VERSION ""

NS_ :

BS_:

BU_: Sound_A Ladegeraet_PAG_PF Motor_EDC17_Pirol PSM_Ant_Derivate GW_Routing_Derivate GW_Applikation_Derivate BMS_Hybrid Getriebe_Derivate LEH_Hybrid Motor_MED17_Hybrid Sound_I Tool Airbag Waehlhebel

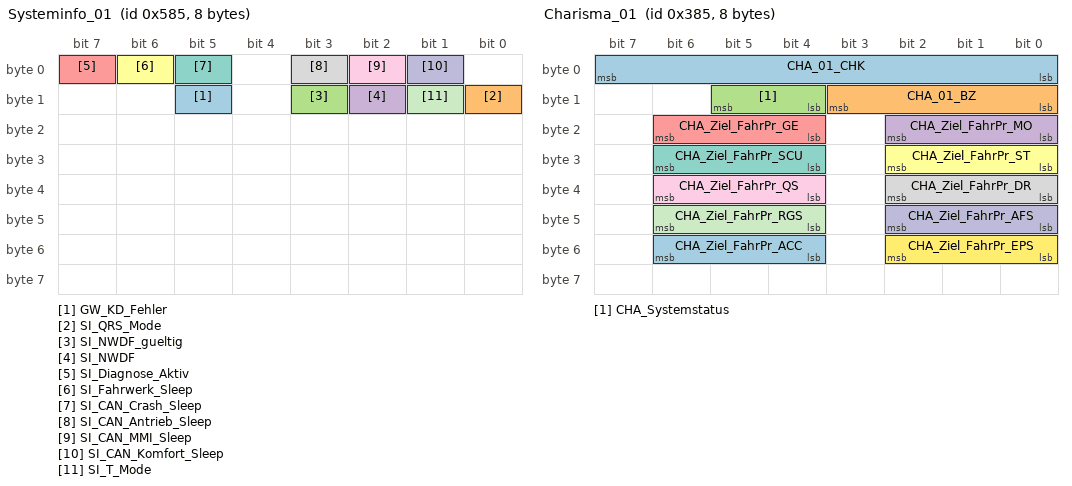
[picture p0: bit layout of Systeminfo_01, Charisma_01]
BO_ 1413 Systeminfo_01: 8 GW_Applikation_Derivate
 SG_ GW_KD_Fehler : 13|1@1+ (1,0) [0|1] "" Vector__XXX
 SG_ SI_QRS_Mode : 8|1@1+ (1,0) [0|1] ""  Motor_MED17_Hybrid,Motor_EDC17_Pirol
 SG_ SI_NWDF_gueltig : 11|1@1+ (1,0) [0|1] "" Vector__XXX
 SG_ SI_NWDF : 10|1@1+ (1,0) [0|1] "" Vector__XXX
 SG_ SI_Diagnose_Aktiv : 7|1@1+ (1,0) [0|1] "" Vector__XXX
 SG_ SI_Fahrwerk_Sleep : 6|1@1+ (1,0) [0|1] "" Vector__XXX
 SG_ SI_CAN_Crash_Sleep : 5|1@1+ (1,0) [0|1] "" Vector__XXX
 SG_ SI_CAN_Antrieb_Sleep : 3|1@1+ (1,0) [0|1] "" Vector__XXX
 SG_ SI_CAN_MMI_Sleep : 2|1@1+ (1,0) [0|1] "" Vector__XXX
 SG_ SI_CAN_Komfort_Sleep : 1|1@1+ (1,0) [0|1] "" Vector__XXX
 SG_ SI_T_Mode : 9|1@1+ (1,0) [0|1] ""  Motor_EDC17_Pirol,Motor_MED17_Hybrid,Airbag

BO_ 2616986624 CCP_MO_CRO_02: 8 Tool
 SG_ CCP_MO_CRO_02_Data : 0|64@1+ (1,0) [0|1] ""  Motor_MED17_Hybrid,Motor_EDC17_Pirol

BO_ 480 CCP_MO_CRO_01: 8 Tool
 SG_ CCP_MO_CRO_01_Data : 0|64@1+ (1,0) [0|1] ""  Motor_MED17_Hybrid,Motor_EDC17_Pirol

BO_ 901 Charisma_01: 8 GW_Routing_Derivate
 SG_ CHA_01_CHK : 0|8@1+ (1,0) [0|255] ""  Motor_EDC17_Pirol,Motor_MED17_Hybrid
 SG_ CHA_01_BZ : 8|4@1+ (1,0) [0|15] ""  Motor_EDC17_Pirol,Motor_MED17_Hybrid
 SG_ CHA_Systemstatus : 12|2@1+ (1,0) [0|3] ""  Motor_EDC17_Pirol,Motor_MED17_Hybrid
 SG_ CHA_Ziel_FahrPr_MO : 16|3@1+ (1,0) [0|7] ""  Motor_EDC17_Pirol,Motor_MED17_Hybrid
 SG_ CHA_Ziel_FahrPr_GE : 20|3@1+ (1,0) [0|7] ""  Getriebe_Derivate
 SG_ CHA_Ziel_FahrPr_ST : 24|3@1+ (1,0) [0|7] "" Vector__XXX
 SG_ CHA_Ziel_FahrPr_SCU : 28|3@1+ (1,0) [0|7] "" Vector__XXX
 SG_ CHA_Ziel_FahrPr_DR : 32|3@1+ (1,0) [0|7] "" Vector__XXX
 SG_ CHA_Ziel_FahrPr_QS : 36|3@1+ (1,0) [0|7] "" Vector__XXX
 SG_ CHA_Ziel_FahrPr_AFS : 40|3@1+ (1,0) [0|7] "" Vector__XXX
 SG_ CHA_Ziel_FahrPr_RGS : 44|3@1+ (1,0) [0|7] "" Vector__XXX
 SG_ CHA_Ziel_FahrPr_EPS : 48|3@1+ (1,0) [0|7] "" Vector__XXX
 SG_ CHA_Ziel_FahrPr_ACC : 52|3@1+ (1,0) [0|7] "" Vector__XXX

BO_ 1728 NMH_Gateway: 7 GW_Applikation_Derivate
 SG_ NMH_GW_Start_1 : 0|1@1+ (1,0) [0|1] ""  Ladegeraet_PAG_PF,Getriebe_Derivate,Motor_MED17_Hybrid,Motor_EDC17_Pirol,LEH_Hybrid,BMS_Hybrid
 SG_ NMH_GW_Start_2 : 1|1@1+ (1,0) [0|1] "" Vector__XXX
 SG_ NMH_GW_Normal_Mode_1 : 2|1@1+ (1,0) [0|1] "" Vector__XXX
 SG_ NMH_GW_Normal_Mode_2 : 3|1@1+ (1,0) [0|1] "" Vector__XXX
 SG_ NMH_GW_Car_WakeUp : 6|1@1+ (1,0) [0|1] "" Vector__XXX
 SG_ NMH_GW_Per_WakeUp : 8|5@1+ (1,0) [0|31] "" Vector__XXX
 SG_ NMH_GW_Fkt_WakeUp : 13|3@1+ (1,0) [0|7] "" Vector__XXX
 SG_ NMH_GW_NM_aktiv_Klemme_15 : 16|1@1+ (1,0) [0|1] "" Vector__XXX
 SG_ NMH_GW_NM_aktiv_Diagnose : 17|1@1+ (1,0) [0|1] "" Vector__XXX
 SG_ NMH_GW_NM_aktiv_Start : 18|1@1+ (1,0) [0|1] "" Vector__XXX
 SG_ NMH_GW_NM_aktiv_BDM : 19|1@1+ (1,0) [0|1] "" Vector__XXX
 SG_ NMH_GW_NM_aktiv_Warnblinken : 20|1@1+ (1,0) [0|1] "" Vector__XXX
 SG_ NMH_GW_NM_aktiv_ESP : 21|1@1+ (1,0) [0|1] "" Vector__XXX
 SG_ NMH_GW_NM_aktiv_EMP : 22|1@1+ (1,0) [0|1] "" Vector__XXX
 SG_ NMH_GW_Abschaltstufe_3 : 24|1@1+ (1,0) [0|1] "" Vector__XXX
 SG_ NMH_GW_SG_Fehlerdauer : 25|1@1+ (1,0) [0|1] "" Vector__XXX
 SG_ NMH_GW_STH_Wakeup : 26|1@1+ (1,0) [0|1] "" Vector__XXX
 SG_ NMH_GW_NL_Diagnose : 27|1@1+ (1,0) [0|1] "" Vector__XXX
 SG_ NM_GW_Signalfehler : 32|1@1+ (1,0) [0|1] "" Vector__XXX
 SG_ NMH_GW_TimeOut_Fehler : 33|1@1+ (1,0) [0|1] "" Vector__XXX
 SG_ NMH_GW_CAN_Diag_deaktiv : 34|1@1+ (1,0) [0|1] "" Vector__XXX
 SG_ NMH_GW_KompSchutz : 35|1@1+ (1,0) [0|1] "" Vector__XXX
 SG_ NMH_GW_Mute_Mode : 36|1@1+ (1,0) [0|1] "" Vector__XXX
 SG_ NMH_GW_Transport_Mode : 37|1@1+ (1,0) [0|1] "" Vector__XXX
 SG_ NMH_GW_Abschaltstufe_aktiv : 38|1@1+ (1,0) [0|1] "" Vector__XXX
 SG_ NMH_GW_Eindraht_Fehler : 39|1@1+ (1,0) [0|1] "" Vector__XXX
 SG_ NMH_GW_ACAN : 40|1@1+ (1,0) [0|1] "" Vector__XXX
 SG_ NMH_GW_KombiCAN : 41|1@1+ (1,0) [0|1] "" Vector__XXX
 SG_ NMH_GW_KomfortCAN : 42|1@1+ (1,0) [0|1] "" Vector__XXX
 SG_ NMH_GW_Infotainment : 43|1@1+ (1,0) [0|1] "" Vector__XXX
 SG_ NMH_GW_Fahrwerk : 44|1@1+ (1,0) [0|1] "" Vector__XXX
 SG_ NMH_GW_WakeUp_CAN_Bus : 45|3@1+ (1,0) [0|7] "" Vector__XXX

BO_ 1327 ESP_27: 8 PSM_Ant_Derivate
 SG_ OBD_Fehler_Laengsbeschleunigung : 14|4@1+ (1,0) [0|15] ""  Motor_MED17_Hybrid
 SG_ OBD_Fehler_Vordrucksensor : 12|2@1+ (1,0) [0|3] ""  Motor_MED17_Hybrid

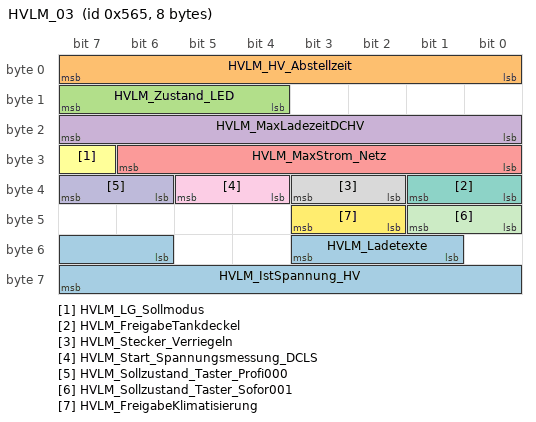
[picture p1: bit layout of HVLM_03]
BO_ 1381 HVLM_03: 8 Ladegeraet_PAG_PF
 SG_ HVLM_IstSpannung_HV : 54|10@1+ (1,0) [0|1021] "Unit_Volt"  GW_Applikation_Derivate,GW_Routing_Derivate
 SG_ HVLM_HV_Abstellzeit : 0|8@1+ (4,0) [0|1012] "Unit_Minut"  GW_Routing_Derivate
 SG_ HVLM_Zustand_LED : 12|4@1+ (1,0) [0|15] ""  GW_Routing_Derivate
 SG_ HVLM_MaxLadezeitDCHV : 16|8@1+ (10,0) [0|2530] "Unit_Minut"  GW_Routing_Derivate
 SG_ HVLM_MaxStrom_Netz : 24|7@1+ (0.5,0) [0|62.5] "Unit_Amper"  GW_Routing_Derivate
 SG_ HVLM_LG_Sollmodus : 31|1@1+ (1,0) [0|1] ""  GW_Routing_Derivate
 SG_ HVLM_FreigabeTankdeckel : 32|2@1+ (1,0) [0|3] ""  GW_Routing_Derivate
 SG_ HVLM_Stecker_Verriegeln : 34|2@1+ (1,0) [0|3] ""  GW_Routing_Derivate
 SG_ HVLM_Start_Spannungsmessung_DCLS : 36|2@1+ (1,0) [0|3] ""  GW_Routing_Derivate
 SG_ HVLM_Sollzustand_Taster_Profi000 : 38|2@1+ (1,0) [0|3] ""  GW_Routing_Derivate
 SG_ HVLM_Sollzustand_Taster_Sofor001 : 40|2@1+ (1,0) [0|3] ""  GW_Routing_Derivate
 SG_ HVLM_FreigabeKlimatisierung : 42|2@1+ (1,0) [0|3] ""  GW_Routing_Derivate
 SG_ HVLM_Ladetexte : 49|3@1+ (1,0) [0|7] ""  GW_Routing_Derivate

BO_ 1534 Kombi_18_PAG: 8 GW_Routing_Derivate
 SG_ KBI_Set_Timer_MUX M : 0|3@1+ (1,0) [0|7] ""  Ladegeraet_PAG_PF
 SG_ KBI_Set_Timer_1_Jahr m1 : 3|7@1+ (1,2000) [2000|2125] "Unit_Year"  Ladegeraet_PAG_PF
 SG_ KBI_Set_Timer_2_Jahr m2 : 3|7@1+ (1,2000) [2000|2125] "Unit_Year"  Ladegeraet_PAG_PF
 SG_ KBI_Set_Timer_3_Jahr m3 : 3|7@1+ (1,2000) [2000|2125] "Unit_Year"  Ladegeraet_PAG_PF
 SG_ KBI_Set_Timer_4_Jahr m4 : 3|7@1+ (1,2000) [2000|2125] "Unit_Year"  Ladegeraet_PAG_PF
 SG_ KBI_Set_Timer_1_Minute m1 : 10|6@1+ (1,0) [0|59] "Unit_Minut"  Ladegeraet_PAG_PF
 SG_ KBI_Set_Timer_2_Minute m2 : 10|6@1+ (1,0) [0|59] "Unit_Minut"  Ladegeraet_PAG_PF
 SG_ KBI_Set_Timer_3_Minute m3 : 10|6@1+ (1,0) [0|59] "Unit_Minut"  Ladegeraet_PAG_PF
 SG_ KBI_Set_Timer_4_Minute m4 : 10|6@1+ (1,0) [0|59] "Unit_Minut"  Ladegeraet_PAG_PF
 SG_ KBI_Set_Timer_1_Monat m1 : 16|4@1+ (1,0) [1|12] "Unit_Month"  Ladegeraet_PAG_PF
 SG_ KBI_Set_Timer_2_Monat m2 : 16|4@1+ (1,0) [1|12] "Unit_Month"  Ladegeraet_PAG_PF
 SG_ KBI_Set_Timer_3_Monat m3 : 16|4@1+ (1,0) [1|12] "Unit_Month"  Ladegeraet_PAG_PF
 SG_ KBI_Set_Timer_4_Monat m4 : 16|4@1+ (1,0) [1|12] "Unit_Month"  Ladegeraet_PAG_PF
 SG_ KBI_Set_Timer_1_Stunde m1 : 20|5@1+ (1,0) [0|23] "Unit_Hours"  Ladegeraet_PAG_PF
 SG_ KBI_Set_Timer_2_Stunde m2 : 20|5@1+ (1,0) [0|23] "Unit_Hours"  Ladegeraet_PAG_PF
 SG_ KBI_Set_Timer_3_Stunde m3 : 20|5@1+ (1,0) [0|23] "Unit_Hours"  Ladegeraet_PAG_PF
 SG_ KBI_Set_Timer_4_Stunde m4 : 20|5@1+ (1,0) [0|23] "Unit_Hours"  Ladegeraet_PAG_PF
 SG_ KBI_Set_Timer_1_Tag m1 : 25|5@1+ (1,0) [1|31] "Unit_Day"  Ladegeraet_PAG_PF
 SG_ KBI_Set_Timer_2_Tag m2 : 25|5@1+ (1,0) [1|31] "Unit_Day"  Ladegeraet_PAG_PF
 SG_ KBI_Set_Timer_3_Tag m3 : 25|5@1+ (1,0) [1|31] "Unit_Day"  Ladegeraet_PAG_PF
 SG_ KBI_Set_Timer_4_Tag m4 : 25|5@1+ (1,0) [1|31] "Unit_Day"  Ladegeraet_PAG_PF
 SG_ KBI_Set_Timer_1_Laden m1 : 30|1@1+ (1,0) [0|1] ""  Ladegeraet_PAG_PF
 SG_ KBI_Set_Timer_2_Laden m2 : 30|1@1+ (1,0) [0|1] ""  Ladegeraet_PAG_PF
 SG_ KBI_Set_Timer_3_Laden m3 : 30|1@1+ (1,0) [0|1] ""  Ladegeraet_PAG_PF
 SG_ KBI_Set_Timer_4_Laden m4 : 30|1@1+ (1,0) [0|1] ""  Ladegeraet_PAG_PF
 SG_ KBI_Set_Timer_1_Vorklima m1 : 31|1@1+ (1,0) [0|1] ""  Ladegeraet_PAG_PF
 SG_ KBI_Set_Timer_2_Vorklima m2 : 31|1@1+ (1,0) [0|1] ""  Ladegeraet_PAG_PF
 SG_ KBI_Set_Timer_3_Vorklima m3 : 31|1@1+ (1,0) [0|1] ""  Ladegeraet_PAG_PF
 SG_ KBI_Set_Timer_4_Vorklima m4 : 31|1@1+ (1,0) [0|1] ""  Ladegeraet_PAG_PF
 SG_ KBI_Set_Timer_1_Zyklus_Mo m1 : 32|1@1+ (1,0) [0|1] ""  Ladegeraet_PAG_PF
 SG_ KBI_Set_Timer_2_Zyklus_Mo m2 : 32|1@1+ (1,0) [0|1] ""  Ladegeraet_PAG_PF
 SG_ KBI_Set_Timer_3_Zyklus_Mo m3 : 32|1@1+ (1,0) [0|1] ""  Ladegeraet_PAG_PF
 SG_ KBI_Set_Timer_4_Zyklus_Mo m4 : 32|1@1+ (1,0) [0|1] ""  Ladegeraet_PAG_PF
 SG_ KBI_Set_Timer_1_Zyklus_Di m1 : 33|1@1+ (1,0) [0|1] ""  Ladegeraet_PAG_PF
 SG_ KBI_Set_Timer_2_Zyklus_Di m2 : 33|1@1+ (1,0) [0|1] ""  Ladegeraet_PAG_PF
 SG_ KBI_Set_Timer_3_Zyklus_Di m3 : 33|1@1+ (1,0) [0|1] ""  Ladegeraet_PAG_PF
 SG_ KBI_Set_Timer_4_Zyklus_Di m4 : 33|1@1+ (1,0) [0|1] ""  Ladegeraet_PAG_PF
 SG_ KBI_Set_Timer_1_Zyklus_Mi m1 : 34|1@1+ (1,0) [0|1] ""  Ladegeraet_PAG_PF
 SG_ KBI_Set_Timer_2_Zyklus_Mi m2 : 34|1@1+ (1,0) [0|1] ""  Ladegeraet_PAG_PF
 SG_ KBI_Set_Timer_3_Zyklus_Mi m3 : 34|1@1+ (1,0) [0|1] ""  Ladegeraet_PAG_PF
 SG_ KBI_Set_Timer_4_Zyklus_Mi m4 : 34|1@1+ (1,0) [0|1] ""  Ladegeraet_PAG_PF
 SG_ KBI_Set_Timer_1_Zyklus_Do m1 : 35|1@1+ (1,0) [0|1] ""  Ladegeraet_PAG_PF
 SG_ KBI_Set_Timer_2_Zyklus_Do m2 : 35|1@1+ (1,0) [0|1] ""  Ladegeraet_PAG_PF
 SG_ KBI_Set_Timer_3_Zyklus_Do m3 : 35|1@1+ (1,0) [0|1] ""  Ladegeraet_PAG_PF
 SG_ KBI_Set_Timer_4_Zyklus_Do m4 : 35|1@1+ (1,0) [0|1] ""  Ladegeraet_PAG_PF
 SG_ KBI_Set_Timer_1_Zyklus_Fr m1 : 36|1@1+ (1,0) [0|1] ""  Ladegeraet_PAG_PF
 SG_ KBI_Set_Timer_2_Zyklus_Fr m2 : 36|1@1+ (1,0) [0|1] ""  Ladegeraet_PAG_PF
 SG_ KBI_Set_Timer_3_Zyklus_Fr m3 : 36|1@1+ (1,0) [0|1] ""  Ladegeraet_PAG_PF
 SG_ KBI_Set_Timer_4_Zyklus_Fr m4 : 36|1@1+ (1,0) [0|1] ""  Ladegeraet_PAG_PF
 SG_ KBI_Set_Timer_1_Zyklus_Sa m1 : 37|1@1+ (1,0) [0|1] ""  Ladegeraet_PAG_PF
 SG_ KBI_Set_Timer_2_Zyklus_Sa m2 : 37|1@1+ (1,0) [0|1] ""  Ladegeraet_PAG_PF
 SG_ KBI_Set_Timer_3_Zyklus_Sa m3 : 37|1@1+ (1,0) [0|1] ""  Ladegeraet_PAG_PF
 SG_ KBI_Set_Timer_4_Zyklus_Sa m4 : 37|1@1+ (1,0) [0|1] ""  Ladegeraet_PAG_PF
 SG_ KBI_Set_Timer_1_Zyklus_So m1 : 38|1@1+ (1,0) [0|1] ""  Ladegeraet_PAG_PF
 SG_ KBI_Set_Timer_2_Zyklus_So m2 : 38|1@1+ (1,0) [0|1] ""  Ladegeraet_PAG_PF
 SG_ KBI_Set_Timer_3_Zyklus_So m3 : 38|1@1+ (1,0) [0|1] ""  Ladegeraet_PAG_PF
 SG_ KBI_Set_Timer_4_Zyklus_So m4 : 38|1@1+ (1,0) [0|1] ""  Ladegeraet_PAG_PF
 SG_ KBI_Set_Timer_1_Zyklus_WH m1 : 39|1@1+ (1,0) [0|1] ""  Ladegeraet_PAG_PF
 SG_ KBI_Set_Timer_2_Zyklus_WH m2 : 39|1@1+ (1,0) [0|1] ""  Ladegeraet_PAG_PF
 SG_ KBI_Set_Timer_3_Zyklus_WH m3 : 39|1@1+ (1,0) [0|1] ""  Ladegeraet_PAG_PF
 SG_ KBI_Set_Timer_4_Zyklus_WH m4 : 39|1@1+ (1,0) [0|1] ""  Ladegeraet_PAG_PF
 SG_ KBI_MOD_Privatsphaere : 60|2@1+ (1,0) [0|3] "" Vector__XXX
 SG_ KBI_STH_Status : 62|2@1+ (1,0) [0|3] "" Vector__XXX

BO_ 1631 Motor_16: 8 Motor_MED17_Hybrid
 SG_ MO_Energieinhalt_BMS : 36|12@1+ (25,0) [0|102325] "Unit_Watt"  BMS_Hybrid

BO_ 1398 MOD_01_PAG: 8 GW_Routing_Derivate
 SG_ MOD_Set_Timer_5_Jahr m5 : 3|7@1+ (1,2000) [2000|2125] "Unit_Year" Vector__XXX
 SG_ MOD_Set_Timer_6_Jahr m6 : 3|7@1+ (1,2000) [2000|2125] "Unit_Year" Vector__XXX
 SG_ MOD_Set_Timer_5_Minute m5 : 10|6@1+ (1,0) [0|59] "Unit_Minut" Vector__XXX
 SG_ MOD_Set_Timer_6_Minute m6 : 10|6@1+ (1,0) [0|59] "Unit_Minut" Vector__XXX
 SG_ MOD_Set_Timer_5_Monat m5 : 16|4@1+ (1,0) [1|12] "Unit_Month" Vector__XXX
 SG_ MOD_Set_Timer_6_Monat m6 : 16|4@1+ (1,0) [1|12] "Unit_Month" Vector__XXX
 SG_ MOD_Set_Timer_5_Stunde m5 : 20|5@1+ (1,0) [0|23] "Unit_Hours" Vector__XXX
 SG_ MOD_Set_Timer_6_Stunde m6 : 20|5@1+ (1,0) [0|23] "Unit_Hours" Vector__XXX
 SG_ MOD_Set_Timer_5_Tag m5 : 25|5@1+ (1,0) [1|31] "Unit_Day" Vector__XXX
 SG_ MOD_Set_Timer_6_Tag m6 : 25|5@1+ (1,0) [1|31] "Unit_Day" Vector__XXX
 SG_ MOD_Set_Timer_5_Vorklima m5 : 31|1@1+ (1,0) [0|1] "" Vector__XXX
 SG_ MOD_Set_Timer_6_Vorklima m6 : 31|1@1+ (1,0) [0|1] "" Vector__XXX
 SG_ MOD_Set_Timerladen : 57|1@1+ (1,0) [0|1] ""  Ladegeraet_PAG_PF
 SG_ MOD_Set_Sofortladen : 59|1@1+ (1,0) [0|1] ""  Ladegeraet_PAG_PF
 SG_ MOD_Set_Timer_4_Jahr m4 : 3|7@1+ (1,2000) [2000|2125] "Unit_Year"  Ladegeraet_PAG_PF
 SG_ MOD_Set_Timer_4_Minute m4 : 10|6@1+ (1,0) [0|59] "Unit_Minut"  Ladegeraet_PAG_PF
 SG_ MOD_Set_Timer_4_Monat m4 : 16|4@1+ (1,0) [1|12] "Unit_Month"  Ladegeraet_PAG_PF
 SG_ MOD_Set_Timer_4_Stunde m4 : 20|5@1+ (1,0) [0|23] "Unit_Hours"  Ladegeraet_PAG_PF
 SG_ MOD_Set_Timer_4_Tag m4 : 25|5@1+ (1,0) [1|31] "Unit_Day"  Ladegeraet_PAG_PF
 SG_ MOD_Set_Timer_4_Laden m4 : 30|1@1+ (1,0) [0|1] ""  Ladegeraet_PAG_PF
 SG_ MOD_Set_Timer_4_Vorklima m4 : 31|1@1+ (1,0) [0|1] ""  Ladegeraet_PAG_PF
 SG_ MOD_Set_Timer_4_Zyklus_Mo m4 : 32|1@1+ (1,0) [0|1] ""  Ladegeraet_PAG_PF
 SG_ MOD_Set_Timer_4_Zyklus_Di m4 : 33|1@1+ (1,0) [0|1] ""  Ladegeraet_PAG_PF
 SG_ MOD_Set_Timer_4_Zyklus_Mi m4 : 34|1@1+ (1,0) [0|1] ""  Ladegeraet_PAG_PF
 SG_ MOD_Set_Timer_4_Zyklus_Do m4 : 35|1@1+ (1,0) [0|1] ""  Ladegeraet_PAG_PF
 SG_ MOD_Set_Timer_4_Zyklus_Fr m4 : 36|1@1+ (1,0) [0|1] ""  Ladegeraet_PAG_PF
 SG_ MOD_Set_Timer_4_Zyklus_Sa m4 : 37|1@1+ (1,0) [0|1] ""  Ladegeraet_PAG_PF
 SG_ MOD_Set_Timer_4_Zyklus_So m4 : 38|1@1+ (1,0) [0|1] ""  Ladegeraet_PAG_PF
 SG_ MOD_Set_Timer_4_Zyklus_WH m4 : 39|1@1+ (1,0) [0|1] ""  Ladegeraet_PAG_PF
 SG_ MOD_Set_Timer_1_Jahr m1 : 3|7@1+ (1,2000) [2000|2125] "Unit_Year"  Ladegeraet_PAG_PF
 SG_ MOD_Set_Timer_2_Jahr m2 : 3|7@1+ (1,2000) [2000|2125] "Unit_Year"  Ladegeraet_PAG_PF
 SG_ MOD_Set_Timer_3_Jahr m3 : 3|7@1+ (1,2000) [2000|2125] "Unit_Year"  Ladegeraet_PAG_PF
 SG_ MOD_Set_Timer_1_Minute m1 : 10|6@1+ (1,0) [0|59] "Unit_Minut"  Ladegeraet_PAG_PF
 SG_ MOD_Set_Timer_2_Minute m2 : 10|6@1+ (1,0) [0|59] "Unit_Minut"  Ladegeraet_PAG_PF
 SG_ MOD_Set_Timer_3_Minute m3 : 10|6@1+ (1,0) [0|59] "Unit_Minut"  Ladegeraet_PAG_PF
 SG_ MOD_Set_Timer_1_Monat m1 : 16|4@1+ (1,0) [1|12] "Unit_Month"  Ladegeraet_PAG_PF
 SG_ MOD_Set_Timer_2_Monat m2 : 16|4@1+ (1,0) [1|12] "Unit_Month"  Ladegeraet_PAG_PF
 SG_ MOD_Set_Timer_3_Monat m3 : 16|4@1+ (1,0) [1|12] "Unit_Month"  Ladegeraet_PAG_PF
 SG_ MOD_Set_Timer_1_Stunde m1 : 20|5@1+ (1,0) [0|23] "Unit_Hours"  Ladegeraet_PAG_PF
 SG_ MOD_Set_Timer_2_Stunde m2 : 20|5@1+ (1,0) [0|23] "Unit_Hours"  Ladegeraet_PAG_PF
 SG_ MOD_Set_Timer_3_Stunde m3 : 20|5@1+ (1,0) [0|23] "Unit_Hours"  Ladegeraet_PAG_PF
 SG_ MOD_Set_Timer_1_Tag m1 : 25|5@1+ (1,0) [1|31] "Unit_Day"  Ladegeraet_PAG_PF
 SG_ MOD_Set_Timer_2_Tag m2 : 25|5@1+ (1,0) [1|31] "Unit_Day"  Ladegeraet_PAG_PF
 SG_ MOD_Set_Timer_3_Tag m3 : 25|5@1+ (1,0) [1|31] "Unit_Day"  Ladegeraet_PAG_PF
 SG_ MOD_Set_Timer_1_Laden m1 : 30|1@1+ (1,0) [0|1] ""  Ladegeraet_PAG_PF
 SG_ MOD_Set_Timer_2_Laden m2 : 30|1@1+ (1,0) [0|1] ""  Ladegeraet_PAG_PF
 SG_ MOD_Set_Timer_3_Laden m3 : 30|1@1+ (1,0) [0|1] ""  Ladegeraet_PAG_PF
 SG_ MOD_Set_Timer_1_Vorklima m1 : 31|1@1+ (1,0) [0|1] ""  Ladegeraet_PAG_PF
 SG_ MOD_Set_Timer_2_Vorklima m2 : 31|1@1+ (1,0) [0|1] ""  Ladegeraet_PAG_PF
 SG_ MOD_Set_Timer_3_Vorklima m3 : 31|1@1+ (1,0) [0|1] ""  Ladegeraet_PAG_PF
 SG_ MOD_Set_Timer_1_Zyklus_Mo m1 : 32|1@1+ (1,0) [0|1] ""  Ladegeraet_PAG_PF
 SG_ MOD_Set_Timer_2_Zyklus_Mo m2 : 32|1@1+ (1,0) [0|1] ""  Ladegeraet_PAG_PF
 SG_ MOD_Set_Timer_3_Zyklus_Mo m3 : 32|1@1+ (1,0) [0|1] ""  Ladegeraet_PAG_PF
 SG_ MOD_Set_Timer_1_Zyklus_Di m1 : 33|1@1+ (1,0) [0|1] ""  Ladegeraet_PAG_PF
 SG_ MOD_Set_Timer_2_Zyklus_Di m2 : 33|1@1+ (1,0) [0|1] ""  Ladegeraet_PAG_PF
 SG_ MOD_Set_Timer_3_Zyklus_Di m3 : 33|1@1+ (1,0) [0|1] ""  Ladegeraet_PAG_PF
 SG_ MOD_Set_Timer_1_Zyklus_Mi m1 : 34|1@1+ (1,0) [0|1] ""  Ladegeraet_PAG_PF
 SG_ MOD_Set_Timer_2_Zyklus_Mi m2 : 34|1@1+ (1,0) [0|1] ""  Ladegeraet_PAG_PF
 SG_ MOD_Set_Timer_3_Zyklus_Mi m3 : 34|1@1+ (1,0) [0|1] ""  Ladegeraet_PAG_PF
 SG_ MOD_Set_Timer_1_Zyklus_Do m1 : 35|1@1+ (1,0) [0|1] ""  Ladegeraet_PAG_PF
 SG_ MOD_Set_Timer_2_Zyklus_Do m2 : 35|1@1+ (1,0) [0|1] ""  Ladegeraet_PAG_PF
 SG_ MOD_Set_Timer_3_Zyklus_Do m3 : 35|1@1+ (1,0) [0|1] ""  Ladegeraet_PAG_PF
 SG_ MOD_Set_Timer_1_Zyklus_Fr m1 : 36|1@1+ (1,0) [0|1] ""  Ladegeraet_PAG_PF
 SG_ MOD_Set_Timer_2_Zyklus_Fr m2 : 36|1@1+ (1,0) [0|1] ""  Ladegeraet_PAG_PF
 SG_ MOD_Set_Timer_3_Zyklus_Fr m3 : 36|1@1+ (1,0) [0|1] ""  Ladegeraet_PAG_PF
 SG_ MOD_Set_Timer_1_Zyklus_Sa m1 : 37|1@1+ (1,0) [0|1] ""  Ladegeraet_PAG_PF
 SG_ MOD_Set_Timer_2_Zyklus_Sa m2 : 37|1@1+ (1,0) [0|1] ""  Ladegeraet_PAG_PF
 SG_ MOD_Set_Timer_3_Zyklus_Sa m3 : 37|1@1+ (1,0) [0|1] ""  Ladegeraet_PAG_PF
 SG_ MOD_Set_Timer_1_Zyklus_So m1 : 38|1@1+ (1,0) [0|1] ""  Ladegeraet_PAG_PF
 SG_ MOD_Set_Timer_2_Zyklus_So m2 : 38|1@1+ (1,0) [0|1] ""  Ladegeraet_PAG_PF
 SG_ MOD_Set_Timer_3_Zyklus_So m3 : 38|1@1+ (1,0) [0|1] ""  Ladegeraet_PAG_PF
 SG_ MOD_Set_Timer_1_Zyklus_WH m1 : 39|1@1+ (1,0) [0|1] ""  Ladegeraet_PAG_PF
 SG_ MOD_Set_Timer_2_Zyklus_WH m2 : 39|1@1+ (1,0) [0|1] ""  Ladegeraet_PAG_PF
 SG_ MOD_Set_Timer_MUX M : 0|3@1+ (1,0) [0|7] ""  Ladegeraet_PAG_PF
 SG_ MOD_Set_Timer_3_Zyklus_WH m3 : 39|1@1+ (1,0) [0|1] ""  Ladegeraet_PAG_PF
 SG_ MOD_Set_Nachtstrom_X_Std_Anf : 40|6@1+ (0.5,0) [0|23.5] "Unit_Hours"  Ladegeraet_PAG_PF
 SG_ MOD_Set_Nachtstrom_Prof : 46|2@1+ (1,0) [0|3] ""  Ladegeraet_PAG_PF
 SG_ MOD_Set_Nachtstrom_X_Std_End : 48|6@1+ (0.5,0) [0|23.5] "Unit_Hours"  Ladegeraet_PAG_PF
 SG_ MOD_Set_Nachtstrom_Akt_Prof : 54|2@1+ (1,0) [0|3] ""  Ladegeraet_PAG_PF
 SG_ MOD_Set_Abbruch_Klima : 56|1@1+ (1,0) [0|1] ""  Ladegeraet_PAG_PF
 SG_ MOD_Set_Sofortstart_Klima : 58|1@1+ (1,0) [0|1] ""  Ladegeraet_PAG_PF
 SG_ MOD_Anf_Spiegel_anklappen : 60|1@1+ (1,0) [0|1] "" Vector__XXX
 SG_ MOD_Anf_ZV : 61|2@1+ (1,0) [0|3] "" Vector__XXX

BO_ 1397 HVLM_07_PAG: 8 Ladegeraet_PAG_PF
 SG_ HVLM_Status_Timer_7_Laden m7 : 30|1@1+ (1,0) [0|1] ""  GW_Routing_Derivate
 SG_ HVLM_Ladetexte : 59|3@1+ (1,0) [0|7] ""  GW_Routing_Derivate
 SG_ HVLM_Status_Timer_4_Jahr m4 : 3|7@1+ (1,2000) [2000|2125] "Unit_Year"  GW_Routing_Derivate
 SG_ HVLM_Status_Timer_4_Minute m4 : 10|6@1+ (1,0) [0|59] "Unit_Minut"  GW_Routing_Derivate
 SG_ HVLM_Status_Timer_4_Monat m4 : 16|4@1+ (1,0) [1|12] "Unit_Month"  GW_Routing_Derivate
 SG_ HVLM_Status_Timer_4_Stunde m4 : 20|5@1+ (1,0) [0|23] "Unit_Hours"  GW_Routing_Derivate
 SG_ HVLM_Status_Timer_4_Tag m4 : 25|5@1+ (1,0) [1|31] "Unit_Day"  GW_Routing_Derivate
 SG_ HVLM_Status_Timer_4_Laden m4 : 30|1@1+ (1,0) [0|1] ""  GW_Routing_Derivate
 SG_ HVLM_Status_Timer_4_Vorklima m4 : 31|1@1+ (1,0) [0|1] ""  GW_Routing_Derivate
 SG_ HVLM_Status_Timer_4_Zyklus_Mo m4 : 32|1@1+ (1,0) [0|1] ""  GW_Routing_Derivate
 SG_ HVLM_Status_Timer_2_Vorklima m2 : 31|1@1+ (1,0) [0|1] ""  GW_Routing_Derivate
 SG_ HVLM_Status_Timer_3_Vorklima m3 : 31|1@1+ (1,0) [0|1] ""  GW_Routing_Derivate
 SG_ HVLM_Status_Timer_1_Zyklus_Mo m1 : 32|1@1+ (1,0) [0|1] ""  GW_Routing_Derivate
 SG_ HVLM_Status_Timer_2_Zyklus_Mo m2 : 32|1@1+ (1,0) [0|1] ""  GW_Routing_Derivate
 SG_ HVLM_Status_Timer_3_Zyklus_Mo m3 : 32|1@1+ (1,0) [0|1] ""  GW_Routing_Derivate
 SG_ HVLM_Status_Timer_1_Zyklus_Di m1 : 33|1@1+ (1,0) [0|1] ""  GW_Routing_Derivate
 SG_ HVLM_Status_Timer_2_Zyklus_Di m2 : 33|1@1+ (1,0) [0|1] ""  GW_Routing_Derivate
 SG_ HVLM_Status_Timer_3_Zyklus_Di m3 : 33|1@1+ (1,0) [0|1] ""  GW_Routing_Derivate
 SG_ HVLM_Status_Timer_1_Zyklus_Mi m1 : 34|1@1+ (1,0) [0|1] ""  GW_Routing_Derivate
 SG_ HVLM_Status_Timer_2_Zyklus_Mi m2 : 34|1@1+ (1,0) [0|1] ""  GW_Routing_Derivate
 SG_ HVLM_Status_Timer_3_Zyklus_Mi m3 : 34|1@1+ (1,0) [0|1] ""  GW_Routing_Derivate
 SG_ HVLM_Status_Timer_1_Zyklus_Do m1 : 35|1@1+ (1,0) [0|1] ""  GW_Routing_Derivate
 SG_ HVLM_Status_Timer_2_Zyklus_Do m2 : 35|1@1+ (1,0) [0|1] ""  GW_Routing_Derivate
 SG_ HVLM_Status_Timer_3_Zyklus_Do m3 : 35|1@1+ (1,0) [0|1] ""  GW_Routing_Derivate
 SG_ HVLM_Status_Timer_1_Zyklus_Fr m1 : 36|1@1+ (1,0) [0|1] ""  GW_Routing_Derivate
 SG_ HVLM_Status_Timer_2_Zyklus_Fr m2 : 36|1@1+ (1,0) [0|1] ""  GW_Routing_Derivate
 SG_ HVLM_Status_Timer_3_Zyklus_Fr m3 : 36|1@1+ (1,0) [0|1] ""  GW_Routing_Derivate
 SG_ HVLM_Status_Timer_1_Zyklus_Sa m1 : 37|1@1+ (1,0) [0|1] ""  GW_Routing_Derivate
 SG_ HVLM_Status_Timer_2_Zyklus_Sa m2 : 37|1@1+ (1,0) [0|1] ""  GW_Routing_Derivate
 SG_ HVLM_Status_Timer_3_Zyklus_Sa m3 : 37|1@1+ (1,0) [0|1] ""  GW_Routing_Derivate
 SG_ HVLM_Status_Timer_1_Zyklus_So m1 : 38|1@1+ (1,0) [0|1] ""  GW_Routing_Derivate
 SG_ HVLM_Status_Timer_2_Zyklus_So m2 : 38|1@1+ (1,0) [0|1] ""  GW_Routing_Derivate
 SG_ HVLM_Status_Timer_3_Zyklus_So m3 : 38|1@1+ (1,0) [0|1] ""  GW_Routing_Derivate
 SG_ HVLM_Status_Timer_1_Zyklus_WH m1 : 39|1@1+ (1,0) [0|1] ""  GW_Routing_Derivate
 SG_ HVLM_Status_Timer_2_Zyklus_WH m2 : 39|1@1+ (1,0) [0|1] ""  GW_Routing_Derivate
 SG_ HVLM_Status_Timer_MUX M : 0|3@1+ (1,0) [0|7] ""  GW_Routing_Derivate
 SG_ HVLM_Status_Timer_3_Zyklus_WH m3 : 39|1@1+ (1,0) [0|1] ""  GW_Routing_Derivate
 SG_ HVLM_Status_Nachtstrom_X_Std_Anf : 40|6@1+ (0.5,0) [0|23.5] "Unit_Hours"  GW_Routing_Derivate
 SG_ HVLM_Status_Nachtstrom_Prof : 46|2@1+ (1,0) [0|3] ""  GW_Routing_Derivate
 SG_ HVLM_Status_Nachtstrom_X_Std_End : 48|6@1+ (0.5,0) [0|23.5] "Unit_Hours"  GW_Routing_Derivate
 SG_ HVLM_Status_Nachtstrom_Akt_Prof : 54|2@1+ (1,0) [0|3] ""  GW_Routing_Derivate
 SG_ HVLM_Status_Laden : 56|3@1+ (1,0) [0|7] ""  GW_Routing_Derivate
 SG_ HVLM_Status_Timer_4_Zyklus_Di m4 : 33|1@1+ (1,0) [0|1] ""  GW_Routing_Derivate
 SG_ HVLM_Status_Timer_4_Zyklus_Mi m4 : 34|1@1+ (1,0) [0|1] ""  GW_Routing_Derivate
 SG_ HVLM_Status_Timer_4_Zyklus_Do m4 : 35|1@1+ (1,0) [0|1] ""  GW_Routing_Derivate
 SG_ HVLM_Status_Timer_4_Zyklus_Fr m4 : 36|1@1+ (1,0) [0|1] ""  GW_Routing_Derivate
 SG_ HVLM_Status_Timer_1_Jahr m1 : 3|7@1+ (1,2000) [2000|2125] "Unit_Year"  GW_Routing_Derivate
 SG_ HVLM_Status_Timer_2_Jahr m2 : 3|7@1+ (1,2000) [2000|2125] "Unit_Year"  GW_Routing_Derivate
 SG_ HVLM_Status_Timer_3_Jahr m3 : 3|7@1+ (1,2000) [2000|2125] "Unit_Year"  GW_Routing_Derivate
 SG_ HVLM_Status_Timer_7_Jahr m7 : 3|7@1+ (1,2000) [2000|2125] "Unit_Year"  GW_Routing_Derivate
 SG_ HVLM_Status_Timer_1_Minute m1 : 10|6@1+ (1,0) [0|59] "Unit_Minut"  GW_Routing_Derivate
 SG_ HVLM_Status_Timer_2_Minute m2 : 10|6@1+ (1,0) [0|59] "Unit_Minut"  GW_Routing_Derivate
 SG_ HVLM_Status_Timer_3_Minute m3 : 10|6@1+ (1,0) [0|59] "Unit_Minut"  GW_Routing_Derivate
 SG_ HVLM_Status_Timer_7_Minute m7 : 10|6@1+ (1,0) [0|59] "Unit_Minut"  GW_Routing_Derivate
 SG_ HVLM_Status_Timer_1_Monat m1 : 16|4@1+ (1,0) [1|12] "Unit_Month"  GW_Routing_Derivate
 SG_ HVLM_Status_Timer_2_Monat m2 : 16|4@1+ (1,0) [1|12] "Unit_Month"  GW_Routing_Derivate
 SG_ HVLM_Status_Timer_3_Monat m3 : 16|4@1+ (1,0) [1|12] "Unit_Month"  GW_Routing_Derivate
 SG_ HVLM_Status_Timer_7_Monat m7 : 16|4@1+ (1,0) [1|12] "Unit_Month"  GW_Routing_Derivate
 SG_ HVLM_Status_Timer_1_Stunde m1 : 20|5@1+ (1,0) [0|23] "Unit_Hours"  GW_Routing_Derivate
 SG_ HVLM_Status_Timer_2_Stunde m2 : 20|5@1+ (1,0) [0|23] "Unit_Hours"  GW_Routing_Derivate
 SG_ HVLM_Status_Timer_3_Stunde m3 : 20|5@1+ (1,0) [0|23] "Unit_Hours"  GW_Routing_Derivate
 SG_ HVLM_Status_Timer_7_Stunde m7 : 20|5@1+ (1,0) [0|23] "Unit_Hours"  GW_Routing_Derivate
 SG_ HVLM_Status_Timer_1_Tag m1 : 25|5@1+ (1,0) [1|31] "Unit_Day"  GW_Routing_Derivate
 SG_ HVLM_Status_Timer_2_Tag m2 : 25|5@1+ (1,0) [1|31] "Unit_Day"  GW_Routing_Derivate
 SG_ HVLM_Status_Timer_3_Tag m3 : 25|5@1+ (1,0) [1|31] "Unit_Day"  GW_Routing_Derivate
 SG_ HVLM_Status_Timer_7_Tag m7 : 25|5@1+ (1,0) [1|31] "Unit_Day"  GW_Routing_Derivate
 SG_ HVLM_Status_Timer_1_Laden m1 : 30|1@1+ (1,0) [0|1] ""  GW_Routing_Derivate
 SG_ HVLM_Status_Timer_2_Laden m2 : 30|1@1+ (1,0) [0|1] ""  GW_Routing_Derivate
 SG_ HVLM_Status_Timer_3_Laden m3 : 30|1@1+ (1,0) [0|1] ""  GW_Routing_Derivate
 SG_ HVLM_Status_Timer_1_Vorklima m1 : 31|1@1+ (1,0) [0|1] ""  GW_Routing_Derivate
 SG_ HVLM_Status_Timer_4_Zyklus_Sa m4 : 37|1@1+ (1,0) [0|1] ""  GW_Routing_Derivate
 SG_ HVLM_Status_Timer_4_Zyklus_So m4 : 38|1@1+ (1,0) [0|1] ""  GW_Routing_Derivate
 SG_ HVLM_Status_Timer_4_Zyklus_WH m4 : 39|1@1+ (1,0) [0|1] ""  GW_Routing_Derivate

BO_ 1446 OBC_Komponentenfehler: 8 Ladegeraet_PAG_PF
 SG_ OBC_KomponentenFehler_01 : 0|2@1+ (1,0) [0|3] ""  BMS_Hybrid
 SG_ OBC_KomponentenFehler_02 : 2|2@1+ (1,0) [0|3] ""  BMS_Hybrid
 SG_ OBC_KomponentenFehler_03 : 4|2@1+ (1,0) [0|3] ""  BMS_Hybrid
 SG_ OBC_KomponentenFehler_04 : 6|2@1+ (1,0) [0|3] ""  BMS_Hybrid
 SG_ OBC_KomponentenFehler_05 : 8|2@1+ (1,0) [0|3] ""  BMS_Hybrid
 SG_ OBC_KomponentenFehler_06 : 10|2@1+ (1,0) [0|3] ""  BMS_Hybrid
 SG_ OBC_KomponentenFehler_07 : 12|2@1+ (1,0) [0|3] ""  BMS_Hybrid
 SG_ OBC_KomponentenFehler_08 : 14|2@1+ (1,0) [0|3] ""  BMS_Hybrid
 SG_ OBC_KomponentenFehler_09 : 16|2@1+ (1,0) [0|3] ""  BMS_Hybrid
 SG_ OBC_KomponentenFehler_10 : 18|2@1+ (1,0) [0|3] ""  BMS_Hybrid
 SG_ OBC_KomponentenFehler_11 : 20|2@1+ (1,0) [0|3] ""  BMS_Hybrid
 SG_ OBC_KomponentenFehler_12 : 22|2@1+ (1,0) [0|3] ""  BMS_Hybrid
 SG_ OBC_KomponentenFehler_13 : 24|2@1+ (1,0) [0|3] ""  BMS_Hybrid
 SG_ OBC_KomponentenFehler_14 : 26|2@1+ (1,0) [0|3] ""  BMS_Hybrid
 SG_ OBC_KomponentenFehler_15 : 28|2@1+ (1,0) [0|3] ""  BMS_Hybrid
 SG_ OBC_KomponentenFehler_16 : 30|2@1+ (1,0) [0|3] ""  BMS_Hybrid
 SG_ OBC_KomponentenFehler_17 : 32|2@1+ (1,0) [0|3] ""  BMS_Hybrid
 SG_ OBC_KomponentenFehler_18 : 34|2@1+ (1,0) [0|3] ""  BMS_Hybrid
 SG_ OBC_KomponentenFehler_19 : 36|2@1+ (1,0) [0|3] ""  BMS_Hybrid
 SG_ OBC_KomponentenFehler_20 : 38|2@1+ (1,0) [0|3] ""  BMS_Hybrid
 SG_ OBC_KomponentenFehler_21 : 40|2@1+ (1,0) [0|3] ""  BMS_Hybrid
 SG_ OBC_KomponentenFehler_22 : 42|2@1+ (1,0) [0|3] ""  BMS_Hybrid
 SG_ OBC_KomponentenFehler_23 : 44|2@1+ (1,0) [0|3] ""  BMS_Hybrid
 SG_ OBC_KomponentenFehler_24 : 46|2@1+ (1,0) [0|3] ""  BMS_Hybrid
 SG_ OBC_KomponentenFehler_25 : 48|2@1+ (1,0) [0|3] ""  BMS_Hybrid
 SG_ OBC_KomponentenFehler_26 : 50|2@1+ (1,0) [0|3] ""  BMS_Hybrid
 SG_ OBC_KomponentenFehler_27 : 52|2@1+ (1,0) [0|3] ""  BMS_Hybrid
 SG_ OBC_KomponentenFehler_28 : 54|2@1+ (1,0) [0|3] ""  BMS_Hybrid
 SG_ OBC_KomponentenFehler_29 : 56|2@1+ (1,0) [0|3] ""  BMS_Hybrid
 SG_ OBC_KomponentenFehler_30 : 58|2@1+ (1,0) [0|3] ""  BMS_Hybrid
 SG_ OBC_KomponentenFehler_31 : 60|2@1+ (1,0) [0|3] ""  BMS_Hybrid
 SG_ OBC_KomponentenFehler_32 : 62|2@1+ (1,0) [0|3] ""  BMS_Hybrid

CM_ SG_ 1413 GW_KD_Fehler "Status Kundendienstfehlerspeichereinträge";
CM_ SG_ 1413 SI_QRS_Mode "Quickruhestrom
(wird vom GW nur im G1 Hybrid / Pirol bedient)";
CM_ SG_ 1413 SI_NWDF_gueltig "Gültigkeitsbit für Netzwerkdiagnosefreigabe-Signal
(Signal wird im Panamera nicht bedient)";
CM_ SG_ 1413 SI_NWDF "Netzwerk-Diagnose Freigebe zur zentralen Aktivierung der Netzwerkdiagnose.
(Signal wird im Panamera nicht bedient)";
CM_ SG_ 1413 SI_Diagnose_Aktiv "Gibt an ob Diagnose-Botschaften empfangen werden und somit eine Diagnose aktiv ist
(Signal wir im Panamera nicht bedient)";
CM_ SG_ 1413 SI_Fahrwerk_Sleep "CAN Fahrwerk schläft (Status des NM)";
CM_ SG_ 1413 SI_CAN_Crash_Sleep "CAN Crash-Gefahren schläft (Status des NM)";
CM_ SG_ 1413 SI_CAN_Antrieb_Sleep "CAN Antrieb schläft (Status des NM)";
CM_ SG_ 1413 SI_CAN_MMI_Sleep "CAN MMI schläft (Status des NM)";
CM_ SG_ 1413 SI_CAN_Komfort_Sleep "CAN Komfort schläft (Status des NM)";
CM_ SG_ 1413 SI_T_Mode "Transportmodus";
CM_ BO_ 480 "CCP in Serie mit 11Bit - Empfangskanal";
CM_ SG_ 901 CHA_01_CHK "Berechnung siehe Lastenheft 'Kommunikationsabsicherung für FlexRay und CAN'
Endwerte siehe 'Kommunikationsabsicherung für FlexRay und CAN / Anhang C: Tabelle S-PDU Kennungen'";
CM_ SG_ 901 CHA_01_BZ "Botschaftszähler konstant zu senden mit 0x00
Die Auswertung dieses BZ der Botschaft Charisma_01 ist durch den Empfänger nicht zulässig.";
CM_ SG_ 901 CHA_Systemstatus "Konstant zu senden mit 0x00 für in Ordnung";
CM_ SG_ 901 CHA_Ziel_FahrPr_MO "Anforderung Ziel-Fahrprogramm Motor

Änderung der Beschriftung des 'Audi drive select'
   alt: 'SPORT'           ->     neu: 'DYNAMIC'
   alt: 'DYNAMIC'       ->     neu: 'AUTO'
";
CM_ SG_ 901 CHA_Ziel_FahrPr_GE "Anforderung Ziel-Fahrprogramm Getriebe

Änderung der Beschriftung des 'Audi drive select'
   alt: 'SPORT'           ->     neu: 'DYNAMIC'
   alt: 'DYNAMIC'       ->     neu: 'AUTO'";
CM_ SG_ 901 CHA_Ziel_FahrPr_ST "Anforderung Ziel-Fahrprogramm

Änderung der Beschriftung des 'Audi drive select'
   alt: 'SPORT'           ->     neu: 'DYNAMIC'
   alt: 'DYNAMIC'       ->     neu: 'AUTO'";
CM_ SG_ 901 CHA_Ziel_FahrPr_SCU "Anforderung Ziel-Fahrprogramm SCU

Änderung der Beschriftung des 'Audi drive select'
   alt: 'SPORT'           ->     neu: 'DYNAMIC'
   alt: 'DYNAMIC'       ->     neu: 'AUTO'";
CM_ SG_ 901 CHA_Ziel_FahrPr_DR "Anforderung Ziel-Fahrprogramm Dämpfer

Änderung der Beschriftung des 'Audi drive select'
   alt: 'SPORT'           ->     neu: 'DYNAMIC'
   alt: 'DYNAMIC'       ->     neu: 'AUTO'";
CM_ SG_ 901 CHA_Ziel_FahrPr_QS "Anforderung Ziel-Fahrprogramm Quattro Sport

Änderung der Beschriftung des 'Audi drive select'
   alt: 'SPORT'           ->     neu: 'DYNAMIC'
   alt: 'DYNAMIC'       ->     neu: 'AUTO'";
CM_ SG_ 901 CHA_Ziel_FahrPr_AFS "Anforderung Ziel-Fahrprogramm AFS

Änderung der Beschriftung des 'Audi drive select'
   alt: 'SPORT'           ->     neu: 'DYNAMIC'
   alt: 'DYNAMIC'       ->     neu: 'AUTO'";
CM_ SG_ 901 CHA_Ziel_FahrPr_RGS "Anforderung Ziel-Fahrprogramm Reversibler Gurtstraffer

Änderung der Beschriftung des 'Audi drive select'
   alt: 'SPORT'           ->     neu: 'DYNAMIC'
   alt: 'DYNAMIC'       ->     neu: 'AUTO'";
CM_ SG_ 901 CHA_Ziel_FahrPr_EPS "Anforderung Ziel-Fahrprogramm Elekronische Lenkung

Änderung der Beschriftung des 'Audi drive select'
   alt: 'SPORT'           ->     neu: 'DYNAMIC'
   alt: 'DYNAMIC'       ->     neu: 'AUTO'";
CM_ SG_ 901 CHA_Ziel_FahrPr_ACC "Anforderung Ziel-Fahrprogramm ACC";
CM_ BO_ 1728 "D4 Kombi-Komfort 200ms";
CM_ SG_ 1728 NMH_GW_Start_1 "Zustand Start (<--Sleep)";
CM_ SG_ 1728 NMH_GW_Start_2 "Zustand Start (<--Prepare to Sleep)";
CM_ SG_ 1728 NMH_GW_Normal_Mode_1 "Zustand Normal Mode (<-- Start)";
CM_ SG_ 1728 NMH_GW_Normal_Mode_2 "Zustand Normal Mode (<-- Ready to Sleep)";
CM_ SG_ 1728 NMH_GW_Car_WakeUp "Car WakeUp (optional), wird vom GW nicht gesendet";
CM_ SG_ 1728 NMH_GW_Per_WakeUp "Weckursache Peripherie
";
CM_ SG_ 1728 NMH_GW_Fkt_WakeUp "Weckursache Funktion (Softwarefunktion hat geweckt)
0 = wenn Peripheriewakeup
1 = BDM BEM
2 = Car Wakeup empfangen: Das Bussegment wurde aufgrund einer CarWakeup Anforderung geweckt. Das GW hat zuvor eine NWM-Botschaft auf einem Bus mit aktiviertem Car";
CM_ SG_ 1728 NMH_GW_NM_aktiv_Klemme_15 "Kl.15 EIN (Nachlaufursache, nicht 'Ready To Sleep')";
CM_ SG_ 1728 NMH_GW_NM_aktiv_Diagnose "Diagnose bei Kl 15 aus (Nachlaufursache, nicht 'Ready To Sleep')";
CM_ SG_ 1728 NMH_GW_NM_aktiv_Start "Mindestaktivzeit Zustand 'Start' (Nachlaufursache, nicht 'Ready To Sleep')";
CM_ SG_ 1728 NMH_GW_NM_aktiv_BDM "BDM-Kommunikation (Nachlaufursache, nicht 'Ready To Sleep')
";
CM_ SG_ 1728 NMH_GW_NM_aktiv_Warnblinken "Warnblinken (NM-Nachlaufursache, nicht 'Ready To Sleep')
";
CM_ SG_ 1728 NMH_GW_NM_aktiv_ESP "ESP aktiv (Wakeup/Sleep-Konzept)
(NM-Nachlaufursache, nicht 'Ready To Sleep')
";
CM_ SG_ 1728 NMH_GW_NM_aktiv_EMP "Nachlauf Energiemanagementplannung";
CM_ SG_ 1728 NMH_GW_Abschaltstufe_3 "Abschaltstufe 3 (BEM) 
(SG-interner Nachlauf vor CAN-Wakeup)
";
CM_ SG_ 1728 NMH_GW_SG_Fehlerdauer "Steuergeraetefehlerdauer (BEM)
(SG-interner Nachlauf vor CAN-Wakeup)
";
CM_ SG_ 1728 NMH_GW_STH_Wakeup "Standheizungswakeup (BEM)
(SG-interner Nachlauf vor CAN-Wakeup)";
CM_ SG_ 1728 NMH_GW_NL_Diagnose "Gateway hat lokalen Nachlauf wegen Kommunikation mit Tester auf DiagCAN";
CM_ SG_ 1728 NM_GW_Signalfehler "Bei der Speicherung eines CAN-Signalfehlers muss dieser mindestens einmal in der NM-Botschaft angezeigt werden.";
CM_ SG_ 1728 NMH_GW_TimeOut_Fehler "Aktiver Timeout Fehlerspeichereintrag";
CM_ SG_ 1728 NMH_GW_CAN_Diag_deaktiv "CAN Bus bezogene Eigendiagnose deaktiviert (Überspannung, Unterspannung, Hochlaufphase, ...) ";
CM_ SG_ 1728 NMH_GW_KompSchutz "Funktionseinschränung aufgrund Komponentenschutz aktiv";
CM_ SG_ 1728 NMH_GW_Mute_Mode "Funktionseinschränung aufgrund Mute Mode aktiv, nur VW";
CM_ SG_ 1728 NMH_GW_Transport_Mode "Funktionseinschränung aufgrund Transport Mode aktiv";
CM_ SG_ 1728 NMH_GW_Abschaltstufe_aktiv "Funktionsabschaltung wegen Abschaltschaltstufe";
CM_ SG_ 1728 NMH_GW_Eindraht_Fehler "Erkennung Eindrahtfehler";
CM_ SG_ 1728 NMH_GW_ACAN "Antriebs-CAN aktiv (Wakeup/Sleep Konzept)
(NM-Nachlaufursache, nicht 'Ready To Sleep')
";
CM_ SG_ 1728 NMH_GW_KombiCAN "Kombi/Fahrwerks-CAN aktiv (Wakeup/Sleep Konzept)
(NM-Nachlaufursache, nicht 'Ready To Sleep')
";
CM_ SG_ 1728 NMH_GW_KomfortCAN "Komfort-CAN aktiv (Wakeup/Sleep Konzept)
(NM-Nachlaufursache, nicht 'Ready To Sleep')

";
CM_ SG_ 1728 NMH_GW_Infotainment "Infotainment aktiv (CAN oder MOST), Wakeup/Sleep-Konzept
(NM-Nachlaufursache, nicht 'Ready To Sleep')
";
CM_ SG_ 1728 NMH_GW_Fahrwerk "Fahrwerks-Bus aktiv (Wakeup/Sleep Konzept)
(NM-Nachlaufursache, nicht 'Ready To Sleep')
";
CM_ SG_ 1728 NMH_GW_WakeUp_CAN_Bus "Weckendes Bussegment (Welcher CAN hat geweckt bzw. CarWakeup angefordert?)

";
CM_ SG_ 1327 OBD_Fehler_Laengsbeschleunigung "Pin pointing für OBD Kommunikation zu Motor SG";
CM_ SG_ 1327 OBD_Fehler_Vordrucksensor "Fehlerstatus Vordrucksensor PSM für OBD";
CM_ SG_ 1381 HVLM_IstSpannung_HV "Ausgangsspannung des Ladegerätes und DC-Spannung der Ladesäule. Messung zwischen den DC HV-Leitungen. ";
CM_ SG_ 1381 HVLM_HV_Abstellzeit "Zeitraum zwischen HV-Deaktiviert und HV-Aktiviert";
CM_ SG_ 1381 HVLM_Zustand_LED "Zustand der Lade-LED im Kombi und Dosenbeleuchtung";
CM_ SG_ 1381 HVLM_MaxLadezeitDCHV "maximale Ladezeit in Minuten für die Ladesäule";
CM_ SG_ 1381 HVLM_MaxStrom_Netz "maximal zulässiger Strom auf Primärseite (AC) des Ladegerätes
Minima aus
Vorgabe z.B. über
- intelligente Kommunikation
- Control Pilot Duty Cycle
- Widerstandskodierung Kabel (Proximity)
- Vorgabe MMI, o.ä.";
CM_ SG_ 1381 HVLM_LG_Sollmodus "Sollmodus AC Ladegerät";
CM_ SG_ 1381 HVLM_FreigabeTankdeckel "Tankdeckelfreigabe";
CM_ SG_ 1381 HVLM_Stecker_Verriegeln "Anforderung Steckerverriegelung";
CM_ SG_ 1381 HVLM_Start_Spannungsmessung_DCLS "Meldung an das BMS, dass an der DC-Ladesäule eine Messspannung aufgeschaltet wird.";
CM_ SG_ 1381 HVLM_Sollzustand_Taster_Profi000 "Zustand der Profil-Laden-Taste; LED an der Ladedose";
CM_ SG_ 1381 HVLM_Sollzustand_Taster_Sofor001 "Zustand der Sofort-Laden-Taste; LED an der Ladedose";
CM_ SG_ 1381 HVLM_FreigabeKlimatisierung "Klimatisierung freigeben";
CM_ SG_ 1381 HVLM_Ladetexte "Anzeige, ob AC- oder DC-Laden nicht möglich ist";
CM_ SG_ 1534 KBI_Set_Timer_MUX "Multiplexor zur Anzeige des aktuell übertragenden und zu setzenden Timers";
CM_ SG_ 1534 KBI_Set_Timer_1_Jahr "Status Timer 1 gesetztes Datum -> Jahr";
CM_ SG_ 1534 KBI_Set_Timer_2_Jahr "Status Timer 2 gesetztes Datum -> Jahr";
CM_ SG_ 1534 KBI_Set_Timer_3_Jahr "Status Timer 3 gesetztes Datum -> Jahr";
CM_ SG_ 1534 KBI_Set_Timer_4_Jahr "Status Timer 4 gesetztes Datum -> Jahr";
CM_ SG_ 1534 KBI_Set_Timer_1_Minute "Status Timer 1 gesetztes Datum -> Minute";
CM_ SG_ 1534 KBI_Set_Timer_2_Minute "Status Timer 2 gesetztes Datum -> Minute";
CM_ SG_ 1534 KBI_Set_Timer_3_Minute "Status Timer 3 gesetztes Datum -> Minute";
CM_ SG_ 1534 KBI_Set_Timer_4_Minute "Status Timer 4 gesetztes Datum -> Minute";
CM_ SG_ 1534 KBI_Set_Timer_1_Monat "Status Timer 1 gesetztes Datum -> Monat";
CM_ SG_ 1534 KBI_Set_Timer_2_Monat "Status Timer 2 gesetztes Datum -> Monat";
CM_ SG_ 1534 KBI_Set_Timer_3_Monat "Status Timer 3 gesetztes Datum -> Monat";
CM_ SG_ 1534 KBI_Set_Timer_4_Monat "Status Timer 4 gesetztes Datum -> Monat";
CM_ SG_ 1534 KBI_Set_Timer_1_Stunde "Status Timer 1 gesetztes Datum -> Stunde";
CM_ SG_ 1534 KBI_Set_Timer_2_Stunde "Status Timer 2 gesetztes Datum -> Stunde";
CM_ SG_ 1534 KBI_Set_Timer_3_Stunde "Status Timer 3 gesetztes Datum -> Stunde";
CM_ SG_ 1534 KBI_Set_Timer_4_Stunde "Status Timer 4 gesetztes Datum -> Stunde";
CM_ SG_ 1534 KBI_Set_Timer_1_Tag "Status Timer 1 gesetztes Datum -> Tag";
CM_ SG_ 1534 KBI_Set_Timer_2_Tag "Status Timer 2 gesetztes Datum -> Tag";
CM_ SG_ 1534 KBI_Set_Timer_3_Tag "Status Timer 3 gesetztes Datum -> Tag";
CM_ SG_ 1534 KBI_Set_Timer_4_Tag "Status Timer 4 gesetztes Datum -> Tag";
CM_ SG_ 1534 KBI_Set_Timer_1_Laden "Setzen des Ladetimers 1";
CM_ SG_ 1534 KBI_Set_Timer_2_Laden "Setzen des Ladetimers 2";
CM_ SG_ 1534 KBI_Set_Timer_3_Laden "Setzen des Ladetimers 3";
CM_ SG_ 1534 KBI_Set_Timer_4_Laden "Setzen des Ladetimers 4";
CM_ SG_ 1534 KBI_Set_Timer_1_Vorklima "Setzen des Vorklimatisierungs-Timers 1";
CM_ SG_ 1534 KBI_Set_Timer_2_Vorklima "Setzen des Vorklimatisierungs-Timers 2";
CM_ SG_ 1534 KBI_Set_Timer_3_Vorklima "Setzen des Vorklimatisierungs-Timers 3";
CM_ SG_ 1534 KBI_Set_Timer_4_Vorklima "Setzen des Vorklimatisierungs-Timers 4";
CM_ SG_ 1534 KBI_Set_Timer_1_Zyklus_Mo "Timer 1 für Wochentag gesetzt";
CM_ SG_ 1534 KBI_Set_Timer_2_Zyklus_Mo "Timer 2 für Wochentag gesetzt";
CM_ SG_ 1534 KBI_Set_Timer_3_Zyklus_Mo "Timer 3 für Wochentag gesetzt";
CM_ SG_ 1534 KBI_Set_Timer_4_Zyklus_Mo "Timer 4 für Wochentag gesetzt";
CM_ SG_ 1534 KBI_Set_Timer_1_Zyklus_Di "Timer 1 für Wochentag gesetzt";
CM_ SG_ 1534 KBI_Set_Timer_2_Zyklus_Di "Timer 2 für Wochentag gesetzt";
CM_ SG_ 1534 KBI_Set_Timer_3_Zyklus_Di "Timer 3 für Wochentag gesetzt";
CM_ SG_ 1534 KBI_Set_Timer_4_Zyklus_Di "Timer 4 für Wochentag gesetzt";
CM_ SG_ 1534 KBI_Set_Timer_1_Zyklus_Mi "Timer 1 für Wochentag gesetzt";
CM_ SG_ 1534 KBI_Set_Timer_2_Zyklus_Mi "Timer 2 für Wochentag gesetzt";
CM_ SG_ 1534 KBI_Set_Timer_3_Zyklus_Mi "Timer 3 für Wochentag gesetzt";
CM_ SG_ 1534 KBI_Set_Timer_4_Zyklus_Mi "Timer 4 für Wochentag gesetzt";
CM_ SG_ 1534 KBI_Set_Timer_1_Zyklus_Do "Timer 1 für Wochentag gesetzt";
CM_ SG_ 1534 KBI_Set_Timer_2_Zyklus_Do "Timer 2 für Wochentag gesetzt";
CM_ SG_ 1534 KBI_Set_Timer_3_Zyklus_Do "Timer 3 für Wochentag gesetzt";
CM_ SG_ 1534 KBI_Set_Timer_4_Zyklus_Do "Timer 4 für Wochentag gesetzt";
CM_ SG_ 1534 KBI_Set_Timer_1_Zyklus_Fr "Timer 1 für Wochentag gesetzt";
CM_ SG_ 1534 KBI_Set_Timer_2_Zyklus_Fr "Timer 2 für Wochentag gesetzt";
CM_ SG_ 1534 KBI_Set_Timer_3_Zyklus_Fr "Timer 3 für Wochentag gesetzt";
CM_ SG_ 1534 KBI_Set_Timer_4_Zyklus_Fr "Timer 4 für Wochentag gesetzt";
CM_ SG_ 1534 KBI_Set_Timer_1_Zyklus_Sa "Timer 1 für Wochentag gesetzt";
CM_ SG_ 1534 KBI_Set_Timer_2_Zyklus_Sa "Timer 2 für Wochentag gesetzt";
CM_ SG_ 1534 KBI_Set_Timer_3_Zyklus_Sa "Timer 3 für Wochentag gesetzt";
CM_ SG_ 1534 KBI_Set_Timer_4_Zyklus_Sa "Timer 4 für Wochentag gesetzt";
CM_ SG_ 1534 KBI_Set_Timer_1_Zyklus_So "Timer 1 für Wochentag gesetzt";
CM_ SG_ 1534 KBI_Set_Timer_2_Zyklus_So "Timer 2 für Wochentag gesetzt";
CM_ SG_ 1534 KBI_Set_Timer_3_Zyklus_So "Timer 3 für Wochentag gesetzt";
CM_ SG_ 1534 KBI_Set_Timer_4_Zyklus_So "Timer 4 für Wochentag gesetzt";
CM_ SG_ 1534 KBI_Set_Timer_1_Zyklus_WH "Timer 1 ist zur einmaligen Auslösung gestezt oder wiederholt sich";
CM_ SG_ 1534 KBI_Set_Timer_2_Zyklus_WH "Timer 2 ist zur einmaligen Auslösung gestezt oder wiederholt sich";
CM_ SG_ 1534 KBI_Set_Timer_3_Zyklus_WH "Timer 3 ist zur einmaligen Auslösung gestezt oder wiederholt sich";
CM_ SG_ 1534 KBI_Set_Timer_4_Zyklus_WH "Timer 4 ist zur einmaligen Auslösung gestezt oder wiederholt sich";
CM_ SG_ 1534 KBI_MOD_Privatsphaere "Ein- und Ausschalten der MOD-Funktion (NICHT VTS) über Kombiinstrument.";
CM_ SG_ 1534 KBI_STH_Status "Standheizungs- Status
";
CM_ SG_ 1631 MO_Energieinhalt_BMS "Restenergieinhalt der Traktionsbatterie, beeinflusst durch Fahrstrategie und weiteren Faktoren der Antriebssteuerung.";
CM_ SG_ 1398 MOD_Set_Timer_5_Jahr "Standheizungstimer #2 (Timer 5) zur zeitversetzten Steuerung der STH auf Anforderung durch MOD.";
CM_ SG_ 1398 MOD_Set_Timer_6_Jahr "Standheizungstimer #3 - Jahr (Timer 6) zur zeitversetzten Steuerung der STH auf Anforderung durch MOD.";
CM_ SG_ 1398 MOD_Set_Timer_5_Minute "Standheizungstimer #2 - Minute (Timer 5) zur zeitversetzten Steuerung der STH auf Anforderung durch MOD.";
CM_ SG_ 1398 MOD_Set_Timer_6_Minute "Standheizungstimer #3 - Minute (Timer 6) zur zeitversetzten Steuerung der STH auf Anforderung durch MOD.";
CM_ SG_ 1398 MOD_Set_Timer_5_Monat "Standheizungstimer #2 - Monat (Timer 5) zur zeitversetzten Steuerung der STH auf Anforderung durch MOD.";
CM_ SG_ 1398 MOD_Set_Timer_6_Monat "Standheizungstimer #3 - Monat";
CM_ SG_ 1398 MOD_Set_Timer_5_Stunde "Standheizungstimer #2 - Stunde (Timer 5) zur zeitversetzten Steuerung der STH auf Anforderung durch MOD.";
CM_ SG_ 1398 MOD_Set_Timer_6_Stunde "Standheizungstimer #3 - Stunde (Timer 6) zur zeitversetzten Steuerung der STH auf Anforderung durch MOD.";
CM_ SG_ 1398 MOD_Set_Timer_5_Tag "Standheizungstimer #2 - Monat";
CM_ SG_ 1398 MOD_Set_Timer_6_Tag "Standheizungstimer #3 - Tag (Timer 6) zur zeitversetzten Steuerung der STH auf Anforderung durch MOD.";
CM_ SG_ 1398 MOD_Set_Timer_5_Vorklima "Status des Standheizungstimers #2 (Timer 5).";
CM_ SG_ 1398 MOD_Set_Timer_6_Vorklima "Status des Standheizungstimers #3 (Timer 6).";
CM_ SG_ 1398 MOD_Set_Timerladen "Timerladen starten / unterbrechen auf Anforderung durch MOD.";
CM_ SG_ 1398 MOD_Set_Sofortladen "Sofortladen starten / unterbrechen auf Anforderung durch MOD.";
CM_ SG_ 1398 MOD_Set_Timer_4_Jahr "Status Timer 4 gesetztes Datum -> Jahr";
CM_ SG_ 1398 MOD_Set_Timer_4_Minute "Status Timer 4 gesetztes Datum -> Minute";
CM_ SG_ 1398 MOD_Set_Timer_4_Monat "Status Timer 4 gesetztes Datum -> Monat";
CM_ SG_ 1398 MOD_Set_Timer_4_Stunde "Status Timer 4 gesetztes Datum -> Stunde";
CM_ SG_ 1398 MOD_Set_Timer_4_Tag "Status Timer 4 gesetztes Datum -> Tag";
CM_ SG_ 1398 MOD_Set_Timer_4_Laden "Status des Ladetimers 4";
CM_ SG_ 1398 MOD_Set_Timer_4_Vorklima "Status des Vorklimatisierungs-Timers 4";
CM_ SG_ 1398 MOD_Set_Timer_4_Zyklus_Mo "Timer 4 für Wochentag gesetzt";
CM_ SG_ 1398 MOD_Set_Timer_4_Zyklus_Di "Timer 4 für Wochentag gesetzt";
CM_ SG_ 1398 MOD_Set_Timer_4_Zyklus_Mi "Timer 4 für Wochentag gesetzt";
CM_ SG_ 1398 MOD_Set_Timer_4_Zyklus_Do "Timer 4 für Wochentag gesetzt";
CM_ SG_ 1398 MOD_Set_Timer_4_Zyklus_Fr "Timer 4 für Wochentag gesetzt";
CM_ SG_ 1398 MOD_Set_Timer_4_Zyklus_Sa "Timer 4 für Wochentag gesetzt";
CM_ SG_ 1398 MOD_Set_Timer_4_Zyklus_So "Timer 4 für Wochentag gesetzt";
CM_ SG_ 1398 MOD_Set_Timer_4_Zyklus_WH "Timer 4 ist zur einmaligen Auslösung gestezt oder wiederholt sich";
CM_ SG_ 1398 MOD_Set_Timer_1_Jahr "Status Timer 1 gesetztes Datum -> Jahr";
CM_ SG_ 1398 MOD_Set_Timer_2_Jahr "Status Timer 2 gesetztes Datum -> Jahr";
CM_ SG_ 1398 MOD_Set_Timer_3_Jahr "Status Timer 3 gesetztes Datum -> Jahr";
CM_ SG_ 1398 MOD_Set_Timer_1_Minute "Status Timer 1 gesetztes Datum -> Minute";
CM_ SG_ 1398 MOD_Set_Timer_2_Minute "Status Timer 2 gesetztes Datum -> Minute";
CM_ SG_ 1398 MOD_Set_Timer_3_Minute "Status Timer 3 gesetztes Datum -> Minute";
CM_ SG_ 1398 MOD_Set_Timer_1_Monat "Status Timer 1 gesetztes Datum -> Monat";
CM_ SG_ 1398 MOD_Set_Timer_2_Monat "Status Timer 2 gesetztes Datum -> Monat";
CM_ SG_ 1398 MOD_Set_Timer_3_Monat "Status Timer 3 gesetztes Datum -> Monat";
CM_ SG_ 1398 MOD_Set_Timer_1_Stunde "Status Timer 1 gesetztes Datum -> Stunde";
CM_ SG_ 1398 MOD_Set_Timer_2_Stunde "Status Timer 2 gesetztes Datum -> Stunde";
CM_ SG_ 1398 MOD_Set_Timer_3_Stunde "Status Timer 3 gesetztes Datum -> Stunde";
CM_ SG_ 1398 MOD_Set_Timer_1_Tag "Status Timer 1 gesetztes Datum -> Tag";
CM_ SG_ 1398 MOD_Set_Timer_2_Tag "Status Timer 2 gesetztes Datum -> Tag";
CM_ SG_ 1398 MOD_Set_Timer_3_Tag "Status Timer 3 gesetztes Datum -> Tag";
CM_ SG_ 1398 MOD_Set_Timer_1_Laden "Status des Ladetimers 1";
CM_ SG_ 1398 MOD_Set_Timer_2_Laden "Status des Ladetimers 2";
CM_ SG_ 1398 MOD_Set_Timer_3_Laden "Status des Ladetimers 3";
CM_ SG_ 1398 MOD_Set_Timer_1_Vorklima "Status des Vorklimatisierungs-Timers 1";
CM_ SG_ 1398 MOD_Set_Timer_2_Vorklima "Status des Vorklimatisierungs-Timers 2";
CM_ SG_ 1398 MOD_Set_Timer_3_Vorklima "Status des Vorklimatisierungs-Timers 3";
CM_ SG_ 1398 MOD_Set_Timer_1_Zyklus_Mo "Timer 1 für Wochentag gesetzt";
CM_ SG_ 1398 MOD_Set_Timer_2_Zyklus_Mo "Timer 2 für Wochentag gesetzt";
CM_ SG_ 1398 MOD_Set_Timer_3_Zyklus_Mo "Timer 3 für Wochentag gesetzt";
CM_ SG_ 1398 MOD_Set_Timer_1_Zyklus_Di "Timer 1 für Wochentag gesetzt";
CM_ SG_ 1398 MOD_Set_Timer_2_Zyklus_Di "Timer 2 für Wochentag gesetzt";
CM_ SG_ 1398 MOD_Set_Timer_3_Zyklus_Di "Timer 3 für Wochentag gesetzt";
CM_ SG_ 1398 MOD_Set_Timer_1_Zyklus_Mi "Timer 1 für Wochentag gesetzt";
CM_ SG_ 1398 MOD_Set_Timer_2_Zyklus_Mi "Timer 2 für Wochentag gesetzt";
CM_ SG_ 1398 MOD_Set_Timer_3_Zyklus_Mi "Timer 3 für Wochentag gesetzt";
CM_ SG_ 1398 MOD_Set_Timer_1_Zyklus_Do "Timer 1 für Wochentag gesetzt";
CM_ SG_ 1398 MOD_Set_Timer_2_Zyklus_Do "Timer 2 für Wochentag gesetzt";
CM_ SG_ 1398 MOD_Set_Timer_3_Zyklus_Do "Timer 3 für Wochentag gesetzt";
CM_ SG_ 1398 MOD_Set_Timer_1_Zyklus_Fr "Timer 1 für Wochentag gesetzt";
CM_ SG_ 1398 MOD_Set_Timer_2_Zyklus_Fr "Timer 2 für Wochentag gesetzt";
CM_ SG_ 1398 MOD_Set_Timer_3_Zyklus_Fr "Timer 3 für Wochentag gesetzt";
CM_ SG_ 1398 MOD_Set_Timer_1_Zyklus_Sa "Timer 1 für Wochentag gesetzt";
CM_ SG_ 1398 MOD_Set_Timer_2_Zyklus_Sa "Timer 2 für Wochentag gesetzt";
CM_ SG_ 1398 MOD_Set_Timer_3_Zyklus_Sa "Timer 3 für Wochentag gesetzt";
CM_ SG_ 1398 MOD_Set_Timer_1_Zyklus_So "Timer 1 für Wochentag gesetzt";
CM_ SG_ 1398 MOD_Set_Timer_2_Zyklus_So "Timer 2 für Wochentag gesetzt";
CM_ SG_ 1398 MOD_Set_Timer_3_Zyklus_So "Timer 3 für Wochentag gesetzt";
CM_ SG_ 1398 MOD_Set_Timer_1_Zyklus_WH "Timer 1 ist zur einmaligen Auslösung gestezt oder wiederholt sich";
CM_ SG_ 1398 MOD_Set_Timer_2_Zyklus_WH "Timer 2 ist zur einmaligen Auslösung gestezt oder wiederholt sich";
CM_ SG_ 1398 MOD_Set_Timer_MUX "Multiplexor zur Anzeige des aktuell übertragenden und zu setzenden Timers";
CM_ SG_ 1398 MOD_Set_Timer_3_Zyklus_WH "Timer 3 ist zur einmaligen Auslösung gestezt oder wiederholt sich";
CM_ SG_ 1398 MOD_Set_Nachtstrom_X_Std_Anf "Anfangszeit für Setzen der Nachtstromtabelle im Profil X - gibt die volle halbe Stunde an
(Aktuell zu setzendes Profil wird im Signal MOD_Set_Nachtstrom_Profil angezeigt)";
CM_ SG_ 1398 MOD_Set_Nachtstrom_Prof "Zusammenfassung Zeitraum 1¿3 zu einem Profil für Setzen der Nachtstromtabelle";
CM_ SG_ 1398 MOD_Set_Nachtstrom_X_Std_End "Endezeit für Setzen der Nachtstromtabelle im Profil X - gibt die volle halbe Stunde an
(Aktuell zu setzendes Profil wird im Signal MOD_Set_Nachtstrom_Profil angezeigt)";
CM_ SG_ 1398 MOD_Set_Nachtstrom_Akt_Prof "Setzen des eingestellten Nachtstrom-Profils";
CM_ SG_ 1398 MOD_Set_Abbruch_Klima "Sofortiger Abbruch der Vorklimatisierung über Standklimatisierung (PHEV über HVLM) oder Standheizung (konventionell über KBI).";
CM_ SG_ 1398 MOD_Set_Sofortstart_Klima "Sofortige Aktivierung der Vorklimatisierung über Standklimatisierung (PHEV über HVLM) oder Standheizung (konventionell über KBI).";
CM_ SG_ 1398 MOD_Anf_Spiegel_anklappen "Anforderung durch MOD die Außenspiegel anzuklappen";
CM_ SG_ 1398 MOD_Anf_ZV "Anforderung durch MOD ZV verriegeln/ entriegeln";
CM_ BO_ 1397 "nur für PAG - Mobile Online Dienste";
CM_ SG_ 1397 HVLM_Status_Timer_7_Laden "Status des Ladetimers 7";
CM_ SG_ 1397 HVLM_Ladetexte "Anzeige, ob AC- oder DC-Laden nicht möglich ist";
CM_ SG_ 1397 HVLM_Status_Timer_4_Jahr "Status Timer 4 gesetztes Datum -> Jahr";
CM_ SG_ 1397 HVLM_Status_Timer_4_Minute "Status Timer 4 gesetztes Datum -> Minute";
CM_ SG_ 1397 HVLM_Status_Timer_4_Monat "Status Timer 4 gesetztes Datum -> Monat";
CM_ SG_ 1397 HVLM_Status_Timer_4_Stunde "Status Timer 4 gesetztes Datum -> Stunde";
CM_ SG_ 1397 HVLM_Status_Timer_4_Tag "Status Timer 4 gesetztes Datum -> Tag";
CM_ SG_ 1397 HVLM_Status_Timer_4_Laden "Status des Ladetimers 4";
CM_ SG_ 1397 HVLM_Status_Timer_4_Vorklima "Status des Vorklimatisierungs-Timers 4";
CM_ SG_ 1397 HVLM_Status_Timer_4_Zyklus_Mo "Timer 4 für Wochentag gesetzt";
CM_ SG_ 1397 HVLM_Status_Timer_2_Vorklima "Status des Vorklimatisierungs-Timers 2";
CM_ SG_ 1397 HVLM_Status_Timer_3_Vorklima "Status des Vorklimatisierungs-Timers 3";
CM_ SG_ 1397 HVLM_Status_Timer_1_Zyklus_Mo "Timer 1 für Wochentag gesetzt";
CM_ SG_ 1397 HVLM_Status_Timer_2_Zyklus_Mo "Timer 2 für Wochentag gesetzt";
CM_ SG_ 1397 HVLM_Status_Timer_3_Zyklus_Mo "Timer 3 für Wochentag gesetzt";
CM_ SG_ 1397 HVLM_Status_Timer_1_Zyklus_Di "Timer 1 für Wochentag gesetzt";
CM_ SG_ 1397 HVLM_Status_Timer_2_Zyklus_Di "Timer 2 für Wochentag gesetzt";
CM_ SG_ 1397 HVLM_Status_Timer_3_Zyklus_Di "Timer 3 für Wochentag gesetzt";
CM_ SG_ 1397 HVLM_Status_Timer_1_Zyklus_Mi "Timer 1 für Wochentag gesetzt";
CM_ SG_ 1397 HVLM_Status_Timer_2_Zyklus_Mi "Timer 2 für Wochentag gesetzt";
CM_ SG_ 1397 HVLM_Status_Timer_3_Zyklus_Mi "Timer 3 für Wochentag gesetzt";
CM_ SG_ 1397 HVLM_Status_Timer_1_Zyklus_Do "Timer 1 für Wochentag gesetzt";
CM_ SG_ 1397 HVLM_Status_Timer_2_Zyklus_Do "Timer 2 für Wochentag gesetzt";
CM_ SG_ 1397 HVLM_Status_Timer_3_Zyklus_Do "Timer 3 für Wochentag gesetzt";
CM_ SG_ 1397 HVLM_Status_Timer_1_Zyklus_Fr "Timer 1 für Wochentag gesetzt";
CM_ SG_ 1397 HVLM_Status_Timer_2_Zyklus_Fr "Timer 2 für Wochentag gesetzt";
CM_ SG_ 1397 HVLM_Status_Timer_3_Zyklus_Fr "Timer 3 für Wochentag gesetzt";
CM_ SG_ 1397 HVLM_Status_Timer_1_Zyklus_Sa "Timer 1 für Wochentag gesetzt";
CM_ SG_ 1397 HVLM_Status_Timer_2_Zyklus_Sa "Timer 2 für Wochentag gesetzt";
CM_ SG_ 1397 HVLM_Status_Timer_3_Zyklus_Sa "Timer 3 für Wochentag gesetzt";
CM_ SG_ 1397 HVLM_Status_Timer_1_Zyklus_So "Timer 1 für Wochentag gesetzt";
CM_ SG_ 1397 HVLM_Status_Timer_2_Zyklus_So "Timer 2 für Wochentag gesetzt";
CM_ SG_ 1397 HVLM_Status_Timer_3_Zyklus_So "Timer 3 für Wochentag gesetzt";
CM_ SG_ 1397 HVLM_Status_Timer_1_Zyklus_WH "Timer 1 ist zur einmaligen Auslösung gestezt oder wiederholt sich";
CM_ SG_ 1397 HVLM_Status_Timer_2_Zyklus_WH "Timer 2 ist zur einmaligen Auslösung gestezt oder wiederholt sich";
CM_ SG_ 1397 HVLM_Status_Timer_MUX "Multiplexor zur Anzeige des aktuell übertragenden Timer-Status (0x1-0x3) und Wecktimer (0x7)";
CM_ SG_ 1397 HVLM_Status_Timer_3_Zyklus_WH "Timer 3 ist zur einmaligen Auslösung gestezt oder wiederholt sich";
CM_ SG_ 1397 HVLM_Status_Nachtstrom_X_Std_Anf "Anfangszeit für Setzen der Nachtstromtabelle im Profil X - gibt die volle halbe Stunde an
(Aktuell zu setzendes Profil wird im Signal HVLM_Status_Nachtstrom_Profil angezeigt)";
CM_ SG_ 1397 HVLM_Status_Nachtstrom_Prof "Zusammenfassung Zeitraum 1..3 zu einem Profil für Setzen der Nachtstromtabelle";
CM_ SG_ 1397 HVLM_Status_Nachtstrom_X_Std_End "Endezeit für Setzen der Nachtstromtabelle im Profil X - gibt die volle halbe Stunde an
(Aktuell zu setzendes Profil wird im Signal HVLM_Status_Nachtstrom_Profil angezeigt)";
CM_ SG_ 1397 HVLM_Status_Nachtstrom_Akt_Prof "Status: aktuell eingestelltes Nachtstrom-Profil";
CM_ SG_ 1397 HVLM_Status_Laden "aktueller Status des Ladevorgangs";
CM_ SG_ 1397 HVLM_Status_Timer_4_Zyklus_Di "Timer 4 für Wochentag gesetzt";
CM_ SG_ 1397 HVLM_Status_Timer_4_Zyklus_Mi "Timer 4 für Wochentag gesetzt";
CM_ SG_ 1397 HVLM_Status_Timer_4_Zyklus_Do "Timer 4 für Wochentag gesetzt";
CM_ SG_ 1397 HVLM_Status_Timer_4_Zyklus_Fr "Timer 4 für Wochentag gesetzt";
CM_ SG_ 1397 HVLM_Status_Timer_1_Jahr "Status Timer 1 gesetztes Datum -> Jahr";
CM_ SG_ 1397 HVLM_Status_Timer_2_Jahr "Status Timer 2 gesetztes Datum -> Jahr";
CM_ SG_ 1397 HVLM_Status_Timer_3_Jahr "Status Timer 3 gesetztes Datum -> Jahr";
CM_ SG_ 1397 HVLM_Status_Timer_7_Jahr "Status Timer 7 gesetztes Datum -> Jahr";
CM_ SG_ 1397 HVLM_Status_Timer_1_Minute "Status Timer 1 gesetztes Datum -> Minute";
CM_ SG_ 1397 HVLM_Status_Timer_2_Minute "Status Timer 2 gesetztes Datum -> Minute";
CM_ SG_ 1397 HVLM_Status_Timer_3_Minute "Status Timer 3 gesetztes Datum -> Minute";
CM_ SG_ 1397 HVLM_Status_Timer_7_Minute "Status Timer 7 gesetztes Datum -> Minute";
CM_ SG_ 1397 HVLM_Status_Timer_1_Monat "Status Timer 1 gesetztes Datum -> Monat";
CM_ SG_ 1397 HVLM_Status_Timer_2_Monat "Status Timer 2 gesetztes Datum -> Monat";
CM_ SG_ 1397 HVLM_Status_Timer_3_Monat "Status Timer 3 gesetztes Datum -> Monat";
CM_ SG_ 1397 HVLM_Status_Timer_7_Monat "Status Timer 7 gesetztes Datum -> Monat";
CM_ SG_ 1397 HVLM_Status_Timer_1_Stunde "Status Timer 1 gesetztes Datum -> Stunde";
CM_ SG_ 1397 HVLM_Status_Timer_2_Stunde "Status Timer 2 gesetztes Datum -> Stunde";
CM_ SG_ 1397 HVLM_Status_Timer_3_Stunde "Status Timer 3 gesetztes Datum -> Stunde";
CM_ SG_ 1397 HVLM_Status_Timer_7_Stunde "Status Timer 7 gesetztes Datum -> Stunde";
CM_ SG_ 1397 HVLM_Status_Timer_1_Tag "Status Timer 1 gesetztes Datum -> Tag";
CM_ SG_ 1397 HVLM_Status_Timer_2_Tag "Status Timer 2 gesetztes Datum -> Tag";
CM_ SG_ 1397 HVLM_Status_Timer_3_Tag "Status Timer 3 gesetztes Datum -> Tag";
CM_ SG_ 1397 HVLM_Status_Timer_7_Tag "Status Timer 1 gesetztes Datum -> Tag";
CM_ SG_ 1397 HVLM_Status_Timer_1_Laden "Status des Ladetimers 1";
CM_ SG_ 1397 HVLM_Status_Timer_2_Laden "Status des Ladetimers 2";
CM_ SG_ 1397 HVLM_Status_Timer_3_Laden "Status des Ladetimers 3";
CM_ SG_ 1397 HVLM_Status_Timer_1_Vorklima "Status des Vorklimatisierungs-Timers 1";
CM_ SG_ 1397 HVLM_Status_Timer_4_Zyklus_Sa "Timer 4 für Wochentag gesetzt";
CM_ SG_ 1397 HVLM_Status_Timer_4_Zyklus_So "Timer 4 für Wochentag gesetzt";
CM_ SG_ 1397 HVLM_Status_Timer_4_Zyklus_WH "Timer 4 ist zur einmaligen Auslösung gestezt oder wiederholt sich";
CM_ SG_ 1446 OBC_KomponentenFehler_01 "Übertragung OBD relevanter Fehlerpfade vom Secondary zum Primary Steuergerät. 
Zuordnung der generischen Komponentenfehler muss zwischen Sender und Empfänger abgestimmt werden.";
CM_ SG_ 1446 OBC_KomponentenFehler_02 "Übertragung OBD relevanter Fehlerpfade vom Secondary zum Primary Steuergerät. 
Zuordnung der generischen Komponentenfehler muss zwischen Sender und Empfänger abgestimmt werden.";
CM_ SG_ 1446 OBC_KomponentenFehler_03 "Übertragung OBD relevanter Fehlerpfade vom Secondary zum Primary Steuergerät. 
Zuordnung der generischen Komponentenfehler muss zwischen Sender und Empfänger abgestimmt werden.";
CM_ SG_ 1446 OBC_KomponentenFehler_04 "Übertragung OBD relevanter Fehlerpfade vom Secondary zum Primary Steuergerät. 
Zuordnung der generischen Komponentenfehler muss zwischen Sender und Empfänger abgestimmt werden.";
CM_ SG_ 1446 OBC_KomponentenFehler_05 "Übertragung OBD relevanter Fehlerpfade vom Secondary zum Primary Steuergerät. 
Zuordnung der generischen Komponentenfehler muss zwischen Sender und Empfänger abgestimmt werden.";
CM_ SG_ 1446 OBC_KomponentenFehler_06 "Übertragung OBD relevanter Fehlerpfade vom Secondary zum Primary Steuergerät. 
Zuordnung der generischen Komponentenfehler muss zwischen Sender und Empfänger abgestimmt werden.";
CM_ SG_ 1446 OBC_KomponentenFehler_07 "Übertragung OBD relevanter Fehlerpfade vom Secondary zum Primary Steuergerät. 
Zuordnung der generischen Komponentenfehler muss zwischen Sender und Empfänger abgestimmt werden.";
CM_ SG_ 1446 OBC_KomponentenFehler_08 "Übertragung OBD relevanter Fehlerpfade vom Secondary zum Primary Steuergerät. 
Zuordnung der generischen Komponentenfehler muss zwischen Sender und Empfänger abgestimmt werden.";
CM_ SG_ 1446 OBC_KomponentenFehler_09 "Übertragung OBD relevanter Fehlerpfade vom Secondary zum Primary Steuergerät. 
Zuordnung der generischen Komponentenfehler muss zwischen Sender und Empfänger abgestimmt werden.";
CM_ SG_ 1446 OBC_KomponentenFehler_10 "Übertragung OBD relevanter Fehlerpfade vom Secondary zum Primary Steuergerät. 
Zuordnung der generischen Komponentenfehler muss zwischen Sender und Empfänger abgestimmt werden.";
CM_ SG_ 1446 OBC_KomponentenFehler_11 "Übertragung OBD relevanter Fehlerpfade vom Secondary zum Primary Steuergerät. 
Zuordnung der generischen Komponentenfehler muss zwischen Sender und Empfänger abgestimmt werden.";
CM_ SG_ 1446 OBC_KomponentenFehler_12 "Übertragung OBD relevanter Fehlerpfade vom Secondary zum Primary Steuergerät. 
Zuordnung der generischen Komponentenfehler muss zwischen Sender und Empfänger abgestimmt werden.";
CM_ SG_ 1446 OBC_KomponentenFehler_13 "Übertragung OBD relevanter Fehlerpfade vom Secondary zum Primary Steuergerät. 
Zuordnung der generischen Komponentenfehler muss zwischen Sender und Empfänger abgestimmt werden.";
CM_ SG_ 1446 OBC_KomponentenFehler_14 "Übertragung OBD relevanter Fehlerpfade vom Secondary zum Primary Steuergerät. 
Zuordnung der generischen Komponentenfehler muss zwischen Sender und Empfänger abgestimmt werden.";
CM_ SG_ 1446 OBC_KomponentenFehler_15 "Übertragung OBD relevanter Fehlerpfade vom Secondary zum Primary Steuergerät. 
Zuordnung der generischen Komponentenfehler muss zwischen Sender und Empfänger abgestimmt werden.";
CM_ SG_ 1446 OBC_KomponentenFehler_16 "Übertragung OBD relevanter Fehlerpfade vom Secondary zum Primary Steuergerät. 
Zuordnung der generischen Komponentenfehler muss zwischen Sender und Empfänger abgestimmt werden.";
CM_ SG_ 1446 OBC_KomponentenFehler_17 "Übertragung OBD relevanter Fehlerpfade vom Secondary zum Primary Steuergerät. 
Zuordnung der generischen Komponentenfehler muss zwischen Sender und Empfänger abgestimmt werden.";
CM_ SG_ 1446 OBC_KomponentenFehler_18 "Übertragung OBD relevanter Fehlerpfade vom Secondary zum Primary Steuergerät. 
Zuordnung der generischen Komponentenfehler muss zwischen Sender und Empfänger abgestimmt werden.";
CM_ SG_ 1446 OBC_KomponentenFehler_19 "Übertragung OBD relevanter Fehlerpfade vom Secondary zum Primary Steuergerät. 
Zuordnung der generischen Komponentenfehler muss zwischen Sender und Empfänger abgestimmt werden.";
CM_ SG_ 1446 OBC_KomponentenFehler_20 "Übertragung OBD relevanter Fehlerpfade vom Secondary zum Primary Steuergerät. 
Zuordnung der generischen Komponentenfehler muss zwischen Sender und Empfänger abgestimmt werden.";
CM_ SG_ 1446 OBC_KomponentenFehler_21 "Übertragung OBD relevanter Fehlerpfade vom Secondary zum Primary Steuergerät. 
Zuordnung der generischen Komponentenfehler muss zwischen Sender und Empfänger abgestimmt werden.";
CM_ SG_ 1446 OBC_KomponentenFehler_22 "Übertragung OBD relevanter Fehlerpfade vom Secondary zum Primary Steuergerät. 
Zuordnung der generischen Komponentenfehler muss zwischen Sender und Empfänger abgestimmt werden.";
CM_ SG_ 1446 OBC_KomponentenFehler_23 "Übertragung OBD relevanter Fehlerpfade vom Secondary zum Primary Steuergerät. 
Zuordnung der generischen Komponentenfehler muss zwischen Sender und Empfänger abgestimmt werden.";
CM_ SG_ 1446 OBC_KomponentenFehler_24 "Übertragung OBD relevanter Fehlerpfade vom Secondary zum Primary Steuergerät. 
Zuordnung der generischen Komponentenfehler muss zwischen Sender und Empfänger abgestimmt werden.";
CM_ SG_ 1446 OBC_KomponentenFehler_25 "Übertragung OBD relevanter Fehlerpfade vom Secondary zum Primary Steuergerät. 
Zuordnung der generischen Komponentenfehler muss zwischen Sender und Empfänger abgestimmt werden.";
CM_ SG_ 1446 OBC_KomponentenFehler_26 "Übertragung OBD relevanter Fehlerpfade vom Secondary zum Primary Steuergerät. 
Zuordnung der generischen Komponentenfehler muss zwischen Sender und Empfänger abgestimmt werden.";
CM_ SG_ 1446 OBC_KomponentenFehler_27 "Übertragung OBD relevanter Fehlerpfade vom Secondary zum Primary Steuergerät. 
Zuordnung der generischen Komponentenfehler muss zwischen Sender und Empfänger abgestimmt werden.";
CM_ SG_ 1446 OBC_KomponentenFehler_28 "Übertragung OBD relevanter Fehlerpfade vom Secondary zum Primary Steuergerät. 
Zuordnung der generischen Komponentenfehler muss zwischen Sender und Empfänger abgestimmt werden.";
CM_ SG_ 1446 OBC_KomponentenFehler_29 "Übertragung OBD relevanter Fehlerpfade vom Secondary zum Primary Steuergerät. 
Zuordnung der generischen Komponentenfehler muss zwischen Sender und Empfänger abgestimmt werden.";
CM_ SG_ 1446 OBC_KomponentenFehler_30 "Übertragung OBD relevanter Fehlerpfade vom Secondary zum Primary Steuergerät. 
Zuordnung der generischen Komponentenfehler muss zwischen Sender und Empfänger abgestimmt werden.";
CM_ SG_ 1446 OBC_KomponentenFehler_31 "Übertragung OBD relevanter Fehlerpfade vom Secondary zum Primary Steuergerät. 
Zuordnung der generischen Komponentenfehler muss zwischen Sender und Empfänger abgestimmt werden.";
CM_ SG_ 1446 OBC_KomponentenFehler_32 "Übertragung OBD relevanter Fehlerpfade vom Secondary zum Primary Steuergerät. 
Zuordnung der generischen Komponentenfehler muss zwischen Sender und Empfänger abgestimmt werden.";
BA_DEF_ SG_  "DERIVATE_Pruefung" ENUM  "offen","geprüft";
BA_DEF_ SG_  "HYB_Rx_Baureihe" ENUM  "G1+Derivate","nur G1","nur Derivate";
BA_DEF_ SG_  "HYB_Rx_Verwendung" ENUM  "DERIV_Rout","DERIV_Calc","DERIV_Rout+DERIV_Calc";
BA_DEF_ SG_  "GenSigSwitchedByIgnition" ENUM  "No","Yes";
BA_DEF_ SG_  "GenSigEnvVarType" ENUM  "int","float","undef";
BA_DEF_ SG_  "GenSigAutoGenSnd" ENUM  "No","Yes";
BA_DEF_ SG_  "GenSigAutoGenDsp" ENUM  "No","Yes";
BA_DEF_ SG_  "GenSigActiveRepetitions" INT -2147483648 2147483647;
BA_DEF_ SG_  "GenSigFuncType" ENUM  "NoFunction","MsgCounter","CRC-8","XOR","XOR-2","DatedBit","SW-Kl15","CHK","Constant","Protocol";
BA_DEF_ SG_  "Info_BCM_HutHut_Kommunikation" ENUM  "Nein","Ja";
BA_DEF_ SG_  "NWM-WakeupAllowed" ENUM  "No","Yes";
BA_DEF_ SG_  "GenSigInactiveValue" STRING ;
BA_DEF_ SG_  "GenSigMissingSourceValue" INT 0 2147483647;
BA_DEF_ SG_  "GenSigStartValue" INT 0 0;
BA_DEF_ SG_  "Fehlerwert" HEX 0 2147483647;
BA_DEF_ SG_  "Bemerkung" STRING ;
BA_DEF_ SG_  "GenSigSendType" ENUM  "Cyclic","OnWrite","OnWriteWithRepetition","OnChange","OnChangeWithRepetition","IfActive","IfActiveWithRepetition","NoSigSendType";
BA_DEF_ BO_  "NmMessage" ENUM  "No","Yes";
BA_DEF_ BO_  "GenMsgAutoGenSnd" ENUM  "No","Yes";
BA_DEF_ BO_  "GenMsgAutoGenDsp" ENUM  "No","Yes";
BA_DEF_ BO_  "MsgType" ENUM  "Broadcast","Event","NM ","NMH","TP2.0","ISO-TP ","BAP","EID";
BA_DEF_ BO_  "GenMsgChkConstant" HEX 0 4095;
BA_DEF_ BO_  "sim_GenMsgILSupport" ENUM  "No","Yes";
BA_DEF_ BO_  "NWM-Botschaft" ENUM  "No","Yes";
BA_DEF_ BO_  "VAGTP20_StatConnection" ENUM  "No","Yes";
BA_DEF_ BO_  "VAGTP20_DynSetup" ENUM  "No","Yes";
BA_DEF_ BO_  "VAGTP20_DynConnection" ENUM  "No","Yes";
BA_DEF_ BO_  "VAGTP20_API" HEX 0 255;
BA_DEF_ BO_  "Direkt_1zu1" ENUM  "Nein","Ja";
BA_DEF_ BO_  "GenMsgSendType" ENUM  "Cyclic","NotUsed","NotUsed","NotUsed","NotUsed","NotUsed","NotUsed","IfActive","NoMsgSendType","NotUsed";
BA_DEF_ BO_  "DiagResponse" ENUM  "No","Yes";
BA_DEF_ BO_  "DiagRequest" ENUM  "No","Yes";
BA_DEF_ BO_  "GenMsgDelayTime" INT 0 65535;
BA_DEF_ BO_  "GenMsgStartDelayTime" INT 0 65535;
BA_DEF_ BO_  "GenMsgILSupport" ENUM  "No","Yes";
BA_DEF_ BO_  "NmhMessage" ENUM  "No","Yes";
BA_DEF_ BO_  "GenMsgNrOfRepetition" INT 0 65535;
BA_DEF_ BO_  "GenMsgCycleTimeFast" INT 0 65535;
BA_DEF_ BO_  "DiagState" ENUM  "No","Yes";
BA_DEF_ BO_  "GenMsgCycleTime" INT 0 65535;
BA_DEF_REL_ BU_BO_REL_  "HYB_Tx_Verwendung" ENUM  "Rout","Calc";
BA_DEF_REL_ BU_BO_REL_  "HYB_Tx_Baureihe" ENUM  "G1+Derivate","G1","Derivate","vector_leerstring";
BA_DEF_REL_ BU_SG_REL_  "GenSigTimeoutTime" INT 0 65535;
BA_DEF_DEF_  "DERIVATE_Pruefung" "offen";
BA_DEF_DEF_  "HYB_Rx_Baureihe" "G1+Derivate";
BA_DEF_DEF_  "HYB_Rx_Verwendung" "DERIV_Rout";
BA_DEF_DEF_  "GenSigSwitchedByIgnition" "No";
BA_DEF_DEF_  "GenSigEnvVarType" "undef";
BA_DEF_DEF_  "GenSigAutoGenSnd" "No";
BA_DEF_DEF_  "GenSigAutoGenDsp" "No";
BA_DEF_DEF_  "GenSigActiveRepetitions" 0;
BA_DEF_DEF_  "GenSigFuncType" "NoFunction";
BA_DEF_DEF_  "Info_BCM_HutHut_Kommunikation" "Nein";
BA_DEF_DEF_  "NWM-WakeupAllowed" "Yes";
BA_DEF_DEF_  "GenSigInactiveValue" "0";
BA_DEF_DEF_  "GenSigMissingSourceValue" 0;
BA_DEF_DEF_  "GenSigStartValue" 0;
BA_DEF_DEF_  "Fehlerwert" 0;
BA_DEF_DEF_  "Bemerkung" "";
BA_DEF_DEF_  "GenSigSendType" "Cyclic";
BA_DEF_DEF_  "NmMessage" "No";
BA_DEF_DEF_  "GenMsgAutoGenSnd" "Yes";
BA_DEF_DEF_  "GenMsgAutoGenDsp" "Yes";
BA_DEF_DEF_  "MsgType" "Broadcast";
BA_DEF_DEF_  "GenMsgChkConstant" 0;
BA_DEF_DEF_  "sim_GenMsgILSupport" "No";
BA_DEF_DEF_  "NWM-Botschaft" "No";
BA_DEF_DEF_  "VAGTP20_StatConnection" "No";
BA_DEF_DEF_  "VAGTP20_DynSetup" "No";
BA_DEF_DEF_  "VAGTP20_DynConnection" "No";
BA_DEF_DEF_  "VAGTP20_API" 1;
BA_DEF_DEF_  "Direkt_1zu1" "Nein";
BA_DEF_DEF_  "GenMsgSendType" "Cyclic";
BA_DEF_DEF_  "DiagResponse" "No";
BA_DEF_DEF_  "DiagRequest" "No";
BA_DEF_DEF_  "GenMsgDelayTime" 0;
BA_DEF_DEF_  "GenMsgStartDelayTime" 0;
BA_DEF_DEF_  "GenMsgILSupport" "No";
BA_DEF_DEF_  "NmhMessage" "No";
BA_DEF_DEF_  "GenMsgNrOfRepetition" 0;
BA_DEF_DEF_  "GenMsgCycleTimeFast" 0;
BA_DEF_DEF_  "DiagState" "No";
BA_DEF_DEF_  "GenMsgCycleTime" 0;
BA_DEF_DEF_REL_ "HYB_Tx_Verwendung" "Rout";
BA_DEF_DEF_REL_ "HYB_Tx_Baureihe" "G1+Derivate";
BA_DEF_DEF_REL_ "GenSigTimeoutTime" 0;
BA_ "GenMsgCycleTime" BO_ 1413 1000;
BA_ "GenMsgILSupport" BO_ 1413 1;
BA_ "GenMsgDelayTime" BO_ 1413 10;
BA_ "sim_GenMsgILSupport" BO_ 1413 1;
BA_ "GenMsgSendType" BO_ 2616986624 8;
BA_ "VAGTP20_API" BO_ 2616986624 0;
BA_ "MsgType" BO_ 2616986624 7;
BA_ "GenMsgSendType" BO_ 480 8;
BA_ "VAGTP20_API" BO_ 480 0;
BA_ "MsgType" BO_ 480 7;
BA_ "GenMsgCycleTime" BO_ 901 100;
BA_ "GenMsgILSupport" BO_ 901 1;
BA_ "VAGTP20_API" BO_ 901 0;
BA_ "GenMsgChkConstant" BO_ 901 134;
BA_ "MsgType" BO_ 901 1;
BA_ "GenMsgCycleTime" BO_ 1728 200;
BA_ "NmhMessage" BO_ 1728 1;
BA_ "GenMsgSendType" BO_ 1728 8;
BA_ "VAGTP20_API" BO_ 1728 0;
BA_ "MsgType" BO_ 1728 3;
BA_ "GenMsgCycleTime" BO_ 1327 200;
BA_ "GenMsgILSupport" BO_ 1327 1;
BA_ "VAGTP20_API" BO_ 1327 0;
BA_ "GenMsgCycleTime" BO_ 1381 500;
BA_ "GenMsgILSupport" BO_ 1381 1;
BA_ "GenMsgDelayTime" BO_ 1381 50;
BA_ "VAGTP20_API" BO_ 1381 0;
BA_ "GenMsgCycleTime" BO_ 1534 1000;
BA_ "GenMsgILSupport" BO_ 1534 1;
BA_ "VAGTP20_API" BO_ 1534 0;
BA_ "GenMsgCycleTime" BO_ 1631 500;
BA_ "GenMsgILSupport" BO_ 1631 1;
BA_ "VAGTP20_API" BO_ 1631 0;
BA_ "GenMsgCycleTime" BO_ 1398 800;
BA_ "GenMsgILSupport" BO_ 1398 1;
BA_ "VAGTP20_API" BO_ 1398 0;
BA_ "GenMsgCycleTime" BO_ 1397 800;
BA_ "GenMsgILSupport" BO_ 1397 1;
BA_ "VAGTP20_API" BO_ 1397 0;
BA_ "GenMsgCycleTime" BO_ 1446 500;
BA_ "GenMsgILSupport" BO_ 1446 1;
BA_ "VAGTP20_API" BO_ 1446 0;
BA_ "NWM-WakeupAllowed" SG_ 1413 SI_QRS_Mode 0;
BA_ "GenSigSendType" SG_ 1413 SI_QRS_Mode 3;
BA_ "GenSigSendType" SG_ 1413 SI_NWDF_gueltig 3;
BA_ "GenSigSendType" SG_ 1413 SI_NWDF 3;
BA_ "GenSigSendType" SG_ 1413 SI_Diagnose_Aktiv 3;
BA_ "GenSigStartValue" SG_ 1413 SI_Fahrwerk_Sleep 1;
BA_ "GenSigSendType" SG_ 1413 SI_Fahrwerk_Sleep 3;
BA_ "GenSigStartValue" SG_ 1413 SI_CAN_Crash_Sleep 1;
BA_ "GenSigSendType" SG_ 1413 SI_CAN_Crash_Sleep 3;
BA_ "GenSigStartValue" SG_ 1413 SI_CAN_Antrieb_Sleep 1;
BA_ "GenSigSendType" SG_ 1413 SI_CAN_Antrieb_Sleep 3;
BA_ "GenSigStartValue" SG_ 1413 SI_CAN_MMI_Sleep 1;
BA_ "GenSigSendType" SG_ 1413 SI_CAN_MMI_Sleep 3;
BA_ "GenSigStartValue" SG_ 1413 SI_CAN_Komfort_Sleep 1;
BA_ "GenSigSendType" SG_ 1413 SI_CAN_Komfort_Sleep 3;
BA_ "GenSigSendType" SG_ 1413 SI_T_Mode 3;
BA_ "NWM-WakeupAllowed" SG_ 2616986624 CCP_MO_CRO_02_Data 0;
BA_ "NWM-WakeupAllowed" SG_ 480 CCP_MO_CRO_01_Data 0;
BA_ "NWM-WakeupAllowed" SG_ 901 CHA_01_CHK 0;
BA_ "GenSigFuncType" SG_ 901 CHA_01_CHK 3;
BA_ "NWM-WakeupAllowed" SG_ 901 CHA_01_BZ 0;
BA_ "GenSigFuncType" SG_ 901 CHA_01_BZ 1;
BA_ "NWM-WakeupAllowed" SG_ 901 CHA_Systemstatus 0;
BA_ "NWM-WakeupAllowed" SG_ 901 CHA_Ziel_FahrPr_MO 0;
BA_ "NWM-WakeupAllowed" SG_ 901 CHA_Ziel_FahrPr_GE 0;
BA_ "NWM-WakeupAllowed" SG_ 901 CHA_Ziel_FahrPr_ST 0;
BA_ "NWM-WakeupAllowed" SG_ 901 CHA_Ziel_FahrPr_SCU 0;
BA_ "NWM-WakeupAllowed" SG_ 901 CHA_Ziel_FahrPr_DR 0;
BA_ "NWM-WakeupAllowed" SG_ 901 CHA_Ziel_FahrPr_QS 0;
BA_ "NWM-WakeupAllowed" SG_ 901 CHA_Ziel_FahrPr_AFS 0;
BA_ "NWM-WakeupAllowed" SG_ 901 CHA_Ziel_FahrPr_RGS 0;
BA_ "NWM-WakeupAllowed" SG_ 901 CHA_Ziel_FahrPr_EPS 0;
BA_ "NWM-WakeupAllowed" SG_ 901 CHA_Ziel_FahrPr_ACC 0;
BA_ "GenSigStartValue" SG_ 1728 NMH_GW_Start_1 1;
BA_ "NWM-WakeupAllowed" SG_ 1728 NMH_GW_Start_1 0;
BA_ "NWM-WakeupAllowed" SG_ 1728 NMH_GW_Start_2 0;
BA_ "NWM-WakeupAllowed" SG_ 1728 NMH_GW_Normal_Mode_1 0;
BA_ "NWM-WakeupAllowed" SG_ 1728 NMH_GW_Normal_Mode_2 0;
BA_ "NWM-WakeupAllowed" SG_ 1728 NMH_GW_Car_WakeUp 0;
BA_ "NWM-WakeupAllowed" SG_ 1728 NMH_GW_NM_aktiv_Klemme_15 0;
BA_ "NWM-WakeupAllowed" SG_ 1728 NMH_GW_NM_aktiv_Diagnose 0;
BA_ "NWM-WakeupAllowed" SG_ 1728 NMH_GW_NM_aktiv_Start 0;
BA_ "NWM-WakeupAllowed" SG_ 1728 NMH_GW_NM_aktiv_BDM 0;
BA_ "NWM-WakeupAllowed" SG_ 1728 NMH_GW_NM_aktiv_Warnblinken 0;
BA_ "NWM-WakeupAllowed" SG_ 1728 NMH_GW_NM_aktiv_ESP 0;
BA_ "NWM-WakeupAllowed" SG_ 1728 NMH_GW_NM_aktiv_EMP 0;
BA_ "NWM-WakeupAllowed" SG_ 1728 NMH_GW_Abschaltstufe_3 0;
BA_ "NWM-WakeupAllowed" SG_ 1728 NMH_GW_SG_Fehlerdauer 0;
BA_ "NWM-WakeupAllowed" SG_ 1728 NMH_GW_STH_Wakeup 0;
BA_ "NWM-WakeupAllowed" SG_ 1728 NMH_GW_NL_Diagnose 0;
BA_ "NWM-WakeupAllowed" SG_ 1728 NM_GW_Signalfehler 0;
BA_ "NWM-WakeupAllowed" SG_ 1728 NMH_GW_TimeOut_Fehler 0;
BA_ "NWM-WakeupAllowed" SG_ 1728 NMH_GW_CAN_Diag_deaktiv 0;
BA_ "NWM-WakeupAllowed" SG_ 1728 NMH_GW_KompSchutz 0;
BA_ "NWM-WakeupAllowed" SG_ 1728 NMH_GW_Mute_Mode 0;
BA_ "NWM-WakeupAllowed" SG_ 1728 NMH_GW_Transport_Mode 0;
BA_ "NWM-WakeupAllowed" SG_ 1728 NMH_GW_Abschaltstufe_aktiv 0;
BA_ "NWM-WakeupAllowed" SG_ 1728 NMH_GW_Eindraht_Fehler 0;
BA_ "NWM-WakeupAllowed" SG_ 1728 NMH_GW_ACAN 0;
BA_ "NWM-WakeupAllowed" SG_ 1728 NMH_GW_KombiCAN 0;
BA_ "NWM-WakeupAllowed" SG_ 1728 NMH_GW_KomfortCAN 0;
BA_ "NWM-WakeupAllowed" SG_ 1728 NMH_GW_Infotainment 0;
BA_ "NWM-WakeupAllowed" SG_ 1728 NMH_GW_Fahrwerk 0;
BA_ "NWM-WakeupAllowed" SG_ 1728 NMH_GW_WakeUp_CAN_Bus 0;
BA_ "NWM-WakeupAllowed" SG_ 1327 OBD_Fehler_Laengsbeschleunigung 0;
BA_ "GenSigSwitchedByIgnition" SG_ 1327 OBD_Fehler_Laengsbeschleunigung 1;
BA_ "NWM-WakeupAllowed" SG_ 1327 OBD_Fehler_Vordrucksensor 0;
BA_ "GenSigSwitchedByIgnition" SG_ 1327 OBD_Fehler_Vordrucksensor 1;
BA_ "Fehlerwert" SG_ 1381 HVLM_IstSpannung_HV 1023;
BA_ "GenSigStartValue" SG_ 1381 HVLM_IstSpannung_HV 1022;
BA_ "NWM-WakeupAllowed" SG_ 1381 HVLM_IstSpannung_HV 0;
BA_ "Fehlerwert" SG_ 1381 HVLM_HV_Abstellzeit 255;
BA_ "GenSigStartValue" SG_ 1381 HVLM_HV_Abstellzeit 254;
BA_ "NWM-WakeupAllowed" SG_ 1381 HVLM_HV_Abstellzeit 0;
BA_ "Fehlerwert" SG_ 1381 HVLM_Zustand_LED 15;
BA_ "GenSigStartValue" SG_ 1381 HVLM_Zustand_LED 14;
BA_ "NWM-WakeupAllowed" SG_ 1381 HVLM_Zustand_LED 0;
BA_ "GenSigSendType" SG_ 1381 HVLM_Zustand_LED 3;
BA_ "Fehlerwert" SG_ 1381 HVLM_MaxLadezeitDCHV 255;
BA_ "GenSigStartValue" SG_ 1381 HVLM_MaxLadezeitDCHV 254;
BA_ "NWM-WakeupAllowed" SG_ 1381 HVLM_MaxLadezeitDCHV 0;
BA_ "GenSigSendType" SG_ 1381 HVLM_MaxLadezeitDCHV 3;
BA_ "Fehlerwert" SG_ 1381 HVLM_MaxStrom_Netz 127;
BA_ "GenSigStartValue" SG_ 1381 HVLM_MaxStrom_Netz 126;
BA_ "NWM-WakeupAllowed" SG_ 1381 HVLM_MaxStrom_Netz 0;
BA_ "GenSigSendType" SG_ 1381 HVLM_MaxStrom_Netz 3;
BA_ "NWM-WakeupAllowed" SG_ 1381 HVLM_LG_Sollmodus 0;
BA_ "GenSigSendType" SG_ 1381 HVLM_LG_Sollmodus 3;
BA_ "Fehlerwert" SG_ 1381 HVLM_FreigabeTankdeckel 3;
BA_ "GenSigStartValue" SG_ 1381 HVLM_FreigabeTankdeckel 2;
BA_ "NWM-WakeupAllowed" SG_ 1381 HVLM_FreigabeTankdeckel 0;
BA_ "GenSigSendType" SG_ 1381 HVLM_FreigabeTankdeckel 3;
BA_ "GenSigStartValue" SG_ 1381 HVLM_Stecker_Verriegeln 2;
BA_ "NWM-WakeupAllowed" SG_ 1381 HVLM_Stecker_Verriegeln 0;
BA_ "GenSigSendType" SG_ 1381 HVLM_Stecker_Verriegeln 3;
BA_ "NWM-WakeupAllowed" SG_ 1381 HVLM_Start_Spannungsmessung_DCLS 0;
BA_ "GenSigSendType" SG_ 1381 HVLM_Start_Spannungsmessung_DCLS 3;
BA_ "Fehlerwert" SG_ 1381 HVLM_Sollzustand_Taster_Profi000 3;
BA_ "GenSigStartValue" SG_ 1381 HVLM_Sollzustand_Taster_Profi000 2;
BA_ "NWM-WakeupAllowed" SG_ 1381 HVLM_Sollzustand_Taster_Profi000 0;
BA_ "GenSigSendType" SG_ 1381 HVLM_Sollzustand_Taster_Profi000 3;
BA_ "Fehlerwert" SG_ 1381 HVLM_Sollzustand_Taster_Sofor001 3;
BA_ "GenSigStartValue" SG_ 1381 HVLM_Sollzustand_Taster_Sofor001 2;
BA_ "NWM-WakeupAllowed" SG_ 1381 HVLM_Sollzustand_Taster_Sofor001 0;
BA_ "GenSigSendType" SG_ 1381 HVLM_Sollzustand_Taster_Sofor001 3;
BA_ "Fehlerwert" SG_ 1381 HVLM_FreigabeKlimatisierung 3;
BA_ "GenSigStartValue" SG_ 1381 HVLM_FreigabeKlimatisierung 2;
BA_ "NWM-WakeupAllowed" SG_ 1381 HVLM_FreigabeKlimatisierung 0;
BA_ "NWM-WakeupAllowed" SG_ 1381 HVLM_Ladetexte 0;
BA_ "NWM-WakeupAllowed" SG_ 1534 KBI_Set_Timer_MUX 0;
BA_ "GenSigStartValue" SG_ 1534 KBI_Set_Timer_1_Jahr 126;
BA_ "NWM-WakeupAllowed" SG_ 1534 KBI_Set_Timer_1_Jahr 0;
BA_ "GenSigSendType" SG_ 1534 KBI_Set_Timer_1_Jahr 7;
BA_ "GenSigStartValue" SG_ 1534 KBI_Set_Timer_2_Jahr 126;
BA_ "NWM-WakeupAllowed" SG_ 1534 KBI_Set_Timer_2_Jahr 0;
BA_ "GenSigSendType" SG_ 1534 KBI_Set_Timer_2_Jahr 7;
BA_ "GenSigStartValue" SG_ 1534 KBI_Set_Timer_3_Jahr 126;
BA_ "NWM-WakeupAllowed" SG_ 1534 KBI_Set_Timer_3_Jahr 0;
BA_ "GenSigSendType" SG_ 1534 KBI_Set_Timer_3_Jahr 7;
BA_ "GenSigStartValue" SG_ 1534 KBI_Set_Timer_4_Jahr 126;
BA_ "NWM-WakeupAllowed" SG_ 1534 KBI_Set_Timer_4_Jahr 0;
BA_ "GenSigSendType" SG_ 1534 KBI_Set_Timer_4_Jahr 7;
BA_ "Fehlerwert" SG_ 1534 KBI_Set_Timer_1_Minute 63;
BA_ "GenSigStartValue" SG_ 1534 KBI_Set_Timer_1_Minute 62;
BA_ "NWM-WakeupAllowed" SG_ 1534 KBI_Set_Timer_1_Minute 0;
BA_ "GenSigSendType" SG_ 1534 KBI_Set_Timer_1_Minute 7;
BA_ "Fehlerwert" SG_ 1534 KBI_Set_Timer_2_Minute 63;
BA_ "GenSigStartValue" SG_ 1534 KBI_Set_Timer_2_Minute 62;
BA_ "NWM-WakeupAllowed" SG_ 1534 KBI_Set_Timer_2_Minute 0;
BA_ "GenSigSendType" SG_ 1534 KBI_Set_Timer_2_Minute 7;
BA_ "NWM-WakeupAllowed" SG_ 1534 KBI_Set_Timer_3_Minute 0;
BA_ "GenSigSendType" SG_ 1534 KBI_Set_Timer_3_Minute 7;
BA_ "NWM-WakeupAllowed" SG_ 1534 KBI_Set_Timer_4_Minute 0;
BA_ "GenSigSendType" SG_ 1534 KBI_Set_Timer_4_Minute 7;
BA_ "Fehlerwert" SG_ 1534 KBI_Set_Timer_1_Monat 15;
BA_ "NWM-WakeupAllowed" SG_ 1534 KBI_Set_Timer_1_Monat 0;
BA_ "GenSigSendType" SG_ 1534 KBI_Set_Timer_1_Monat 7;
BA_ "Fehlerwert" SG_ 1534 KBI_Set_Timer_2_Monat 15;
BA_ "NWM-WakeupAllowed" SG_ 1534 KBI_Set_Timer_2_Monat 0;
BA_ "GenSigSendType" SG_ 1534 KBI_Set_Timer_2_Monat 7;
BA_ "Fehlerwert" SG_ 1534 KBI_Set_Timer_3_Monat 15;
BA_ "NWM-WakeupAllowed" SG_ 1534 KBI_Set_Timer_3_Monat 0;
BA_ "GenSigSendType" SG_ 1534 KBI_Set_Timer_3_Monat 7;
BA_ "Fehlerwert" SG_ 1534 KBI_Set_Timer_4_Monat 15;
BA_ "NWM-WakeupAllowed" SG_ 1534 KBI_Set_Timer_4_Monat 0;
BA_ "GenSigSendType" SG_ 1534 KBI_Set_Timer_4_Monat 7;
BA_ "Fehlerwert" SG_ 1534 KBI_Set_Timer_1_Stunde 31;
BA_ "GenSigStartValue" SG_ 1534 KBI_Set_Timer_1_Stunde 30;
BA_ "NWM-WakeupAllowed" SG_ 1534 KBI_Set_Timer_1_Stunde 0;
BA_ "GenSigSendType" SG_ 1534 KBI_Set_Timer_1_Stunde 7;
BA_ "Fehlerwert" SG_ 1534 KBI_Set_Timer_2_Stunde 31;
BA_ "GenSigStartValue" SG_ 1534 KBI_Set_Timer_2_Stunde 30;
BA_ "NWM-WakeupAllowed" SG_ 1534 KBI_Set_Timer_2_Stunde 0;
BA_ "GenSigSendType" SG_ 1534 KBI_Set_Timer_2_Stunde 7;
BA_ "Fehlerwert" SG_ 1534 KBI_Set_Timer_3_Stunde 31;
BA_ "GenSigStartValue" SG_ 1534 KBI_Set_Timer_3_Stunde 30;
BA_ "NWM-WakeupAllowed" SG_ 1534 KBI_Set_Timer_3_Stunde 0;
BA_ "GenSigSendType" SG_ 1534 KBI_Set_Timer_3_Stunde 7;
BA_ "Fehlerwert" SG_ 1534 KBI_Set_Timer_4_Stunde 31;
BA_ "GenSigStartValue" SG_ 1534 KBI_Set_Timer_4_Stunde 30;
BA_ "NWM-WakeupAllowed" SG_ 1534 KBI_Set_Timer_4_Stunde 0;
BA_ "GenSigSendType" SG_ 1534 KBI_Set_Timer_4_Stunde 7;
BA_ "NWM-WakeupAllowed" SG_ 1534 KBI_Set_Timer_1_Tag 0;
BA_ "GenSigSendType" SG_ 1534 KBI_Set_Timer_1_Tag 7;
BA_ "NWM-WakeupAllowed" SG_ 1534 KBI_Set_Timer_2_Tag 0;
BA_ "GenSigSendType" SG_ 1534 KBI_Set_Timer_2_Tag 7;
BA_ "NWM-WakeupAllowed" SG_ 1534 KBI_Set_Timer_3_Tag 0;
BA_ "GenSigSendType" SG_ 1534 KBI_Set_Timer_3_Tag 7;
BA_ "NWM-WakeupAllowed" SG_ 1534 KBI_Set_Timer_4_Tag 0;
BA_ "GenSigSendType" SG_ 1534 KBI_Set_Timer_4_Tag 7;
BA_ "NWM-WakeupAllowed" SG_ 1534 KBI_Set_Timer_1_Laden 0;
BA_ "GenSigSendType" SG_ 1534 KBI_Set_Timer_1_Laden 7;
BA_ "NWM-WakeupAllowed" SG_ 1534 KBI_Set_Timer_2_Laden 0;
BA_ "GenSigSendType" SG_ 1534 KBI_Set_Timer_2_Laden 7;
BA_ "NWM-WakeupAllowed" SG_ 1534 KBI_Set_Timer_3_Laden 0;
BA_ "GenSigSendType" SG_ 1534 KBI_Set_Timer_3_Laden 7;
BA_ "NWM-WakeupAllowed" SG_ 1534 KBI_Set_Timer_4_Laden 0;
BA_ "GenSigSendType" SG_ 1534 KBI_Set_Timer_4_Laden 7;
BA_ "NWM-WakeupAllowed" SG_ 1534 KBI_Set_Timer_1_Vorklima 0;
BA_ "GenSigSendType" SG_ 1534 KBI_Set_Timer_1_Vorklima 7;
BA_ "NWM-WakeupAllowed" SG_ 1534 KBI_Set_Timer_2_Vorklima 0;
BA_ "GenSigSendType" SG_ 1534 KBI_Set_Timer_2_Vorklima 7;
BA_ "NWM-WakeupAllowed" SG_ 1534 KBI_Set_Timer_3_Vorklima 0;
BA_ "GenSigSendType" SG_ 1534 KBI_Set_Timer_3_Vorklima 7;
BA_ "NWM-WakeupAllowed" SG_ 1534 KBI_Set_Timer_4_Vorklima 0;
BA_ "GenSigSendType" SG_ 1534 KBI_Set_Timer_4_Vorklima 7;
BA_ "NWM-WakeupAllowed" SG_ 1534 KBI_Set_Timer_1_Zyklus_Mo 0;
BA_ "GenSigSendType" SG_ 1534 KBI_Set_Timer_1_Zyklus_Mo 7;
BA_ "NWM-WakeupAllowed" SG_ 1534 KBI_Set_Timer_2_Zyklus_Mo 0;
BA_ "GenSigSendType" SG_ 1534 KBI_Set_Timer_2_Zyklus_Mo 7;
BA_ "NWM-WakeupAllowed" SG_ 1534 KBI_Set_Timer_3_Zyklus_Mo 0;
BA_ "GenSigSendType" SG_ 1534 KBI_Set_Timer_3_Zyklus_Mo 7;
BA_ "NWM-WakeupAllowed" SG_ 1534 KBI_Set_Timer_4_Zyklus_Mo 0;
BA_ "GenSigSendType" SG_ 1534 KBI_Set_Timer_4_Zyklus_Mo 7;
BA_ "NWM-WakeupAllowed" SG_ 1534 KBI_Set_Timer_1_Zyklus_Di 0;
BA_ "GenSigSendType" SG_ 1534 KBI_Set_Timer_1_Zyklus_Di 7;
BA_ "NWM-WakeupAllowed" SG_ 1534 KBI_Set_Timer_2_Zyklus_Di 0;
BA_ "GenSigSendType" SG_ 1534 KBI_Set_Timer_2_Zyklus_Di 7;
BA_ "NWM-WakeupAllowed" SG_ 1534 KBI_Set_Timer_3_Zyklus_Di 0;
BA_ "GenSigSendType" SG_ 1534 KBI_Set_Timer_3_Zyklus_Di 7;
BA_ "NWM-WakeupAllowed" SG_ 1534 KBI_Set_Timer_4_Zyklus_Di 0;
BA_ "GenSigSendType" SG_ 1534 KBI_Set_Timer_4_Zyklus_Di 7;
BA_ "NWM-WakeupAllowed" SG_ 1534 KBI_Set_Timer_1_Zyklus_Mi 0;
BA_ "GenSigSendType" SG_ 1534 KBI_Set_Timer_1_Zyklus_Mi 7;
BA_ "NWM-WakeupAllowed" SG_ 1534 KBI_Set_Timer_2_Zyklus_Mi 0;
BA_ "GenSigSendType" SG_ 1534 KBI_Set_Timer_2_Zyklus_Mi 7;
BA_ "NWM-WakeupAllowed" SG_ 1534 KBI_Set_Timer_3_Zyklus_Mi 0;
BA_ "GenSigSendType" SG_ 1534 KBI_Set_Timer_3_Zyklus_Mi 7;
BA_ "NWM-WakeupAllowed" SG_ 1534 KBI_Set_Timer_4_Zyklus_Mi 0;
BA_ "GenSigSendType" SG_ 1534 KBI_Set_Timer_4_Zyklus_Mi 7;
BA_ "NWM-WakeupAllowed" SG_ 1534 KBI_Set_Timer_1_Zyklus_Do 0;
BA_ "GenSigSendType" SG_ 1534 KBI_Set_Timer_1_Zyklus_Do 7;
BA_ "NWM-WakeupAllowed" SG_ 1534 KBI_Set_Timer_2_Zyklus_Do 0;
BA_ "GenSigSendType" SG_ 1534 KBI_Set_Timer_2_Zyklus_Do 7;
BA_ "NWM-WakeupAllowed" SG_ 1534 KBI_Set_Timer_3_Zyklus_Do 0;
BA_ "GenSigSendType" SG_ 1534 KBI_Set_Timer_3_Zyklus_Do 7;
BA_ "NWM-WakeupAllowed" SG_ 1534 KBI_Set_Timer_4_Zyklus_Do 0;
BA_ "GenSigSendType" SG_ 1534 KBI_Set_Timer_4_Zyklus_Do 7;
BA_ "NWM-WakeupAllowed" SG_ 1534 KBI_Set_Timer_1_Zyklus_Fr 0;
BA_ "GenSigSendType" SG_ 1534 KBI_Set_Timer_1_Zyklus_Fr 7;
BA_ "NWM-WakeupAllowed" SG_ 1534 KBI_Set_Timer_2_Zyklus_Fr 0;
BA_ "GenSigSendType" SG_ 1534 KBI_Set_Timer_2_Zyklus_Fr 7;
BA_ "NWM-WakeupAllowed" SG_ 1534 KBI_Set_Timer_3_Zyklus_Fr 0;
BA_ "GenSigSendType" SG_ 1534 KBI_Set_Timer_3_Zyklus_Fr 7;
BA_ "NWM-WakeupAllowed" SG_ 1534 KBI_Set_Timer_4_Zyklus_Fr 0;
BA_ "GenSigSendType" SG_ 1534 KBI_Set_Timer_4_Zyklus_Fr 7;
BA_ "NWM-WakeupAllowed" SG_ 1534 KBI_Set_Timer_1_Zyklus_Sa 0;
BA_ "GenSigSendType" SG_ 1534 KBI_Set_Timer_1_Zyklus_Sa 7;
BA_ "NWM-WakeupAllowed" SG_ 1534 KBI_Set_Timer_2_Zyklus_Sa 0;
BA_ "GenSigSendType" SG_ 1534 KBI_Set_Timer_2_Zyklus_Sa 7;
BA_ "NWM-WakeupAllowed" SG_ 1534 KBI_Set_Timer_3_Zyklus_Sa 0;
BA_ "GenSigSendType" SG_ 1534 KBI_Set_Timer_3_Zyklus_Sa 7;
BA_ "NWM-WakeupAllowed" SG_ 1534 KBI_Set_Timer_4_Zyklus_Sa 0;
BA_ "GenSigSendType" SG_ 1534 KBI_Set_Timer_4_Zyklus_Sa 7;
BA_ "NWM-WakeupAllowed" SG_ 1534 KBI_Set_Timer_1_Zyklus_So 0;
BA_ "GenSigSendType" SG_ 1534 KBI_Set_Timer_1_Zyklus_So 7;
BA_ "NWM-WakeupAllowed" SG_ 1534 KBI_Set_Timer_2_Zyklus_So 0;
BA_ "GenSigSendType" SG_ 1534 KBI_Set_Timer_2_Zyklus_So 7;
BA_ "NWM-WakeupAllowed" SG_ 1534 KBI_Set_Timer_3_Zyklus_So 0;
BA_ "GenSigSendType" SG_ 1534 KBI_Set_Timer_3_Zyklus_So 7;
BA_ "NWM-WakeupAllowed" SG_ 1534 KBI_Set_Timer_4_Zyklus_So 0;
BA_ "GenSigSendType" SG_ 1534 KBI_Set_Timer_4_Zyklus_So 7;
BA_ "NWM-WakeupAllowed" SG_ 1534 KBI_Set_Timer_1_Zyklus_WH 0;
BA_ "GenSigSendType" SG_ 1534 KBI_Set_Timer_1_Zyklus_WH 7;
BA_ "NWM-WakeupAllowed" SG_ 1534 KBI_Set_Timer_2_Zyklus_WH 0;
BA_ "GenSigSendType" SG_ 1534 KBI_Set_Timer_2_Zyklus_WH 7;
BA_ "NWM-WakeupAllowed" SG_ 1534 KBI_Set_Timer_3_Zyklus_WH 0;
BA_ "GenSigSendType" SG_ 1534 KBI_Set_Timer_3_Zyklus_WH 7;
BA_ "NWM-WakeupAllowed" SG_ 1534 KBI_Set_Timer_4_Zyklus_WH 0;
BA_ "GenSigSendType" SG_ 1534 KBI_Set_Timer_4_Zyklus_WH 7;
BA_ "NWM-WakeupAllowed" SG_ 1534 KBI_MOD_Privatsphaere 0;
BA_ "NWM-WakeupAllowed" SG_ 1534 KBI_STH_Status 0;
BA_ "Fehlerwert" SG_ 1631 MO_Energieinhalt_BMS 4095;
BA_ "GenSigStartValue" SG_ 1631 MO_Energieinhalt_BMS 4094;
BA_ "NWM-WakeupAllowed" SG_ 1631 MO_Energieinhalt_BMS 0;
BA_ "GenSigStartValue" SG_ 1398 MOD_Set_Timer_5_Jahr 126;
BA_ "NWM-WakeupAllowed" SG_ 1398 MOD_Set_Timer_5_Jahr 0;
BA_ "GenSigSendType" SG_ 1398 MOD_Set_Timer_5_Jahr 7;
BA_ "GenSigStartValue" SG_ 1398 MOD_Set_Timer_6_Jahr 126;
BA_ "NWM-WakeupAllowed" SG_ 1398 MOD_Set_Timer_6_Jahr 0;
BA_ "GenSigSendType" SG_ 1398 MOD_Set_Timer_6_Jahr 7;
BA_ "GenSigStartValue" SG_ 1398 MOD_Set_Timer_5_Minute 62;
BA_ "NWM-WakeupAllowed" SG_ 1398 MOD_Set_Timer_5_Minute 0;
BA_ "GenSigSendType" SG_ 1398 MOD_Set_Timer_5_Minute 7;
BA_ "GenSigStartValue" SG_ 1398 MOD_Set_Timer_6_Minute 62;
BA_ "NWM-WakeupAllowed" SG_ 1398 MOD_Set_Timer_6_Minute 0;
BA_ "GenSigSendType" SG_ 1398 MOD_Set_Timer_6_Minute 7;
BA_ "NWM-WakeupAllowed" SG_ 1398 MOD_Set_Timer_5_Monat 0;
BA_ "GenSigSendType" SG_ 1398 MOD_Set_Timer_5_Monat 7;
BA_ "NWM-WakeupAllowed" SG_ 1398 MOD_Set_Timer_6_Monat 0;
BA_ "GenSigSendType" SG_ 1398 MOD_Set_Timer_6_Monat 7;
BA_ "GenSigStartValue" SG_ 1398 MOD_Set_Timer_5_Stunde 30;
BA_ "NWM-WakeupAllowed" SG_ 1398 MOD_Set_Timer_5_Stunde 0;
BA_ "GenSigSendType" SG_ 1398 MOD_Set_Timer_5_Stunde 7;
BA_ "GenSigStartValue" SG_ 1398 MOD_Set_Timer_6_Stunde 30;
BA_ "NWM-WakeupAllowed" SG_ 1398 MOD_Set_Timer_6_Stunde 0;
BA_ "GenSigSendType" SG_ 1398 MOD_Set_Timer_6_Stunde 7;
BA_ "NWM-WakeupAllowed" SG_ 1398 MOD_Set_Timer_5_Tag 0;
BA_ "GenSigSendType" SG_ 1398 MOD_Set_Timer_5_Tag 7;
BA_ "NWM-WakeupAllowed" SG_ 1398 MOD_Set_Timer_6_Tag 0;
BA_ "GenSigSendType" SG_ 1398 MOD_Set_Timer_6_Tag 7;
BA_ "NWM-WakeupAllowed" SG_ 1398 MOD_Set_Timer_5_Vorklima 0;
BA_ "GenSigSendType" SG_ 1398 MOD_Set_Timer_5_Vorklima 7;
BA_ "NWM-WakeupAllowed" SG_ 1398 MOD_Set_Timer_6_Vorklima 0;
BA_ "GenSigSendType" SG_ 1398 MOD_Set_Timer_6_Vorklima 7;
BA_ "NWM-WakeupAllowed" SG_ 1398 MOD_Set_Timerladen 0;
BA_ "NWM-WakeupAllowed" SG_ 1398 MOD_Set_Sofortladen 0;
BA_ "GenSigStartValue" SG_ 1398 MOD_Set_Timer_4_Jahr 126;
BA_ "NWM-WakeupAllowed" SG_ 1398 MOD_Set_Timer_4_Jahr 0;
BA_ "GenSigSendType" SG_ 1398 MOD_Set_Timer_4_Jahr 7;
BA_ "Fehlerwert" SG_ 1398 MOD_Set_Timer_4_Minute 63;
BA_ "GenSigStartValue" SG_ 1398 MOD_Set_Timer_4_Minute 62;
BA_ "NWM-WakeupAllowed" SG_ 1398 MOD_Set_Timer_4_Minute 0;
BA_ "GenSigSendType" SG_ 1398 MOD_Set_Timer_4_Minute 7;
BA_ "Fehlerwert" SG_ 1398 MOD_Set_Timer_4_Monat 15;
BA_ "NWM-WakeupAllowed" SG_ 1398 MOD_Set_Timer_4_Monat 0;
BA_ "GenSigSendType" SG_ 1398 MOD_Set_Timer_4_Monat 7;
BA_ "Fehlerwert" SG_ 1398 MOD_Set_Timer_4_Stunde 31;
BA_ "GenSigStartValue" SG_ 1398 MOD_Set_Timer_4_Stunde 30;
BA_ "NWM-WakeupAllowed" SG_ 1398 MOD_Set_Timer_4_Stunde 0;
BA_ "GenSigSendType" SG_ 1398 MOD_Set_Timer_4_Stunde 7;
BA_ "NWM-WakeupAllowed" SG_ 1398 MOD_Set_Timer_4_Tag 0;
BA_ "GenSigSendType" SG_ 1398 MOD_Set_Timer_4_Tag 7;
BA_ "NWM-WakeupAllowed" SG_ 1398 MOD_Set_Timer_4_Laden 0;
BA_ "GenSigSendType" SG_ 1398 MOD_Set_Timer_4_Laden 7;
BA_ "NWM-WakeupAllowed" SG_ 1398 MOD_Set_Timer_4_Vorklima 0;
BA_ "GenSigSendType" SG_ 1398 MOD_Set_Timer_4_Vorklima 7;
BA_ "NWM-WakeupAllowed" SG_ 1398 MOD_Set_Timer_4_Zyklus_Mo 0;
BA_ "GenSigSendType" SG_ 1398 MOD_Set_Timer_4_Zyklus_Mo 7;
BA_ "NWM-WakeupAllowed" SG_ 1398 MOD_Set_Timer_4_Zyklus_Di 0;
BA_ "GenSigSendType" SG_ 1398 MOD_Set_Timer_4_Zyklus_Di 7;
BA_ "NWM-WakeupAllowed" SG_ 1398 MOD_Set_Timer_4_Zyklus_Mi 0;
BA_ "GenSigSendType" SG_ 1398 MOD_Set_Timer_4_Zyklus_Mi 7;
BA_ "NWM-WakeupAllowed" SG_ 1398 MOD_Set_Timer_4_Zyklus_Do 0;
BA_ "GenSigSendType" SG_ 1398 MOD_Set_Timer_4_Zyklus_Do 7;
BA_ "NWM-WakeupAllowed" SG_ 1398 MOD_Set_Timer_4_Zyklus_Fr 0;
BA_ "GenSigSendType" SG_ 1398 MOD_Set_Timer_4_Zyklus_Fr 7;
BA_ "NWM-WakeupAllowed" SG_ 1398 MOD_Set_Timer_4_Zyklus_Sa 0;
BA_ "GenSigSendType" SG_ 1398 MOD_Set_Timer_4_Zyklus_Sa 7;
BA_ "NWM-WakeupAllowed" SG_ 1398 MOD_Set_Timer_4_Zyklus_So 0;
BA_ "GenSigSendType" SG_ 1398 MOD_Set_Timer_4_Zyklus_So 7;
BA_ "NWM-WakeupAllowed" SG_ 1398 MOD_Set_Timer_4_Zyklus_WH 0;
BA_ "GenSigSendType" SG_ 1398 MOD_Set_Timer_4_Zyklus_WH 7;
BA_ "GenSigStartValue" SG_ 1398 MOD_Set_Timer_1_Jahr 126;
BA_ "NWM-WakeupAllowed" SG_ 1398 MOD_Set_Timer_1_Jahr 0;
BA_ "GenSigSendType" SG_ 1398 MOD_Set_Timer_1_Jahr 7;
BA_ "GenSigStartValue" SG_ 1398 MOD_Set_Timer_2_Jahr 126;
BA_ "NWM-WakeupAllowed" SG_ 1398 MOD_Set_Timer_2_Jahr 0;
BA_ "GenSigSendType" SG_ 1398 MOD_Set_Timer_2_Jahr 7;
BA_ "GenSigStartValue" SG_ 1398 MOD_Set_Timer_3_Jahr 126;
BA_ "NWM-WakeupAllowed" SG_ 1398 MOD_Set_Timer_3_Jahr 0;
BA_ "GenSigSendType" SG_ 1398 MOD_Set_Timer_3_Jahr 7;
BA_ "Fehlerwert" SG_ 1398 MOD_Set_Timer_1_Minute 63;
BA_ "GenSigStartValue" SG_ 1398 MOD_Set_Timer_1_Minute 62;
BA_ "NWM-WakeupAllowed" SG_ 1398 MOD_Set_Timer_1_Minute 0;
BA_ "GenSigSendType" SG_ 1398 MOD_Set_Timer_1_Minute 7;
BA_ "Fehlerwert" SG_ 1398 MOD_Set_Timer_2_Minute 63;
BA_ "GenSigStartValue" SG_ 1398 MOD_Set_Timer_2_Minute 62;
BA_ "NWM-WakeupAllowed" SG_ 1398 MOD_Set_Timer_2_Minute 0;
BA_ "GenSigSendType" SG_ 1398 MOD_Set_Timer_2_Minute 7;
BA_ "Fehlerwert" SG_ 1398 MOD_Set_Timer_3_Minute 63;
BA_ "GenSigStartValue" SG_ 1398 MOD_Set_Timer_3_Minute 62;
BA_ "NWM-WakeupAllowed" SG_ 1398 MOD_Set_Timer_3_Minute 0;
BA_ "GenSigSendType" SG_ 1398 MOD_Set_Timer_3_Minute 7;
BA_ "Fehlerwert" SG_ 1398 MOD_Set_Timer_1_Monat 15;
BA_ "NWM-WakeupAllowed" SG_ 1398 MOD_Set_Timer_1_Monat 0;
BA_ "GenSigSendType" SG_ 1398 MOD_Set_Timer_1_Monat 7;
BA_ "Fehlerwert" SG_ 1398 MOD_Set_Timer_2_Monat 15;
BA_ "NWM-WakeupAllowed" SG_ 1398 MOD_Set_Timer_2_Monat 0;
BA_ "GenSigSendType" SG_ 1398 MOD_Set_Timer_2_Monat 7;
BA_ "Fehlerwert" SG_ 1398 MOD_Set_Timer_3_Monat 15;
BA_ "NWM-WakeupAllowed" SG_ 1398 MOD_Set_Timer_3_Monat 0;
BA_ "GenSigSendType" SG_ 1398 MOD_Set_Timer_3_Monat 7;
BA_ "Fehlerwert" SG_ 1398 MOD_Set_Timer_1_Stunde 31;
BA_ "GenSigStartValue" SG_ 1398 MOD_Set_Timer_1_Stunde 30;
BA_ "NWM-WakeupAllowed" SG_ 1398 MOD_Set_Timer_1_Stunde 0;
BA_ "GenSigSendType" SG_ 1398 MOD_Set_Timer_1_Stunde 7;
BA_ "Fehlerwert" SG_ 1398 MOD_Set_Timer_2_Stunde 31;
BA_ "GenSigStartValue" SG_ 1398 MOD_Set_Timer_2_Stunde 30;
BA_ "NWM-WakeupAllowed" SG_ 1398 MOD_Set_Timer_2_Stunde 0;
BA_ "GenSigSendType" SG_ 1398 MOD_Set_Timer_2_Stunde 7;
BA_ "Fehlerwert" SG_ 1398 MOD_Set_Timer_3_Stunde 31;
BA_ "GenSigStartValue" SG_ 1398 MOD_Set_Timer_3_Stunde 30;
BA_ "NWM-WakeupAllowed" SG_ 1398 MOD_Set_Timer_3_Stunde 0;
BA_ "GenSigSendType" SG_ 1398 MOD_Set_Timer_3_Stunde 7;
BA_ "NWM-WakeupAllowed" SG_ 1398 MOD_Set_Timer_1_Tag 0;
BA_ "GenSigSendType" SG_ 1398 MOD_Set_Timer_1_Tag 7;
BA_ "NWM-WakeupAllowed" SG_ 1398 MOD_Set_Timer_2_Tag 0;
BA_ "GenSigSendType" SG_ 1398 MOD_Set_Timer_2_Tag 7;
BA_ "NWM-WakeupAllowed" SG_ 1398 MOD_Set_Timer_3_Tag 0;
BA_ "GenSigSendType" SG_ 1398 MOD_Set_Timer_3_Tag 7;
BA_ "NWM-WakeupAllowed" SG_ 1398 MOD_Set_Timer_1_Laden 0;
BA_ "GenSigSendType" SG_ 1398 MOD_Set_Timer_1_Laden 7;
BA_ "NWM-WakeupAllowed" SG_ 1398 MOD_Set_Timer_2_Laden 0;
BA_ "GenSigSendType" SG_ 1398 MOD_Set_Timer_2_Laden 7;
BA_ "NWM-WakeupAllowed" SG_ 1398 MOD_Set_Timer_3_Laden 0;
BA_ "GenSigSendType" SG_ 1398 MOD_Set_Timer_3_Laden 7;
BA_ "NWM-WakeupAllowed" SG_ 1398 MOD_Set_Timer_1_Vorklima 0;
BA_ "GenSigSendType" SG_ 1398 MOD_Set_Timer_1_Vorklima 7;
BA_ "NWM-WakeupAllowed" SG_ 1398 MOD_Set_Timer_2_Vorklima 0;
BA_ "GenSigSendType" SG_ 1398 MOD_Set_Timer_2_Vorklima 7;
BA_ "NWM-WakeupAllowed" SG_ 1398 MOD_Set_Timer_3_Vorklima 0;
BA_ "GenSigSendType" SG_ 1398 MOD_Set_Timer_3_Vorklima 7;
BA_ "NWM-WakeupAllowed" SG_ 1398 MOD_Set_Timer_1_Zyklus_Mo 0;
BA_ "GenSigSendType" SG_ 1398 MOD_Set_Timer_1_Zyklus_Mo 7;
BA_ "NWM-WakeupAllowed" SG_ 1398 MOD_Set_Timer_2_Zyklus_Mo 0;
BA_ "GenSigSendType" SG_ 1398 MOD_Set_Timer_2_Zyklus_Mo 7;
BA_ "NWM-WakeupAllowed" SG_ 1398 MOD_Set_Timer_3_Zyklus_Mo 0;
BA_ "GenSigSendType" SG_ 1398 MOD_Set_Timer_3_Zyklus_Mo 7;
BA_ "NWM-WakeupAllowed" SG_ 1398 MOD_Set_Timer_1_Zyklus_Di 0;
BA_ "GenSigSendType" SG_ 1398 MOD_Set_Timer_1_Zyklus_Di 7;
BA_ "NWM-WakeupAllowed" SG_ 1398 MOD_Set_Timer_2_Zyklus_Di 0;
BA_ "GenSigSendType" SG_ 1398 MOD_Set_Timer_2_Zyklus_Di 7;
BA_ "NWM-WakeupAllowed" SG_ 1398 MOD_Set_Timer_3_Zyklus_Di 0;
BA_ "GenSigSendType" SG_ 1398 MOD_Set_Timer_3_Zyklus_Di 7;
BA_ "NWM-WakeupAllowed" SG_ 1398 MOD_Set_Timer_1_Zyklus_Mi 0;
BA_ "GenSigSendType" SG_ 1398 MOD_Set_Timer_1_Zyklus_Mi 7;
BA_ "NWM-WakeupAllowed" SG_ 1398 MOD_Set_Timer_2_Zyklus_Mi 0;
BA_ "GenSigSendType" SG_ 1398 MOD_Set_Timer_2_Zyklus_Mi 7;
BA_ "NWM-WakeupAllowed" SG_ 1398 MOD_Set_Timer_3_Zyklus_Mi 0;
BA_ "GenSigSendType" SG_ 1398 MOD_Set_Timer_3_Zyklus_Mi 7;
BA_ "NWM-WakeupAllowed" SG_ 1398 MOD_Set_Timer_1_Zyklus_Do 0;
BA_ "GenSigSendType" SG_ 1398 MOD_Set_Timer_1_Zyklus_Do 7;
BA_ "NWM-WakeupAllowed" SG_ 1398 MOD_Set_Timer_2_Zyklus_Do 0;
BA_ "GenSigSendType" SG_ 1398 MOD_Set_Timer_2_Zyklus_Do 7;
BA_ "NWM-WakeupAllowed" SG_ 1398 MOD_Set_Timer_3_Zyklus_Do 0;
BA_ "GenSigSendType" SG_ 1398 MOD_Set_Timer_3_Zyklus_Do 7;
BA_ "NWM-WakeupAllowed" SG_ 1398 MOD_Set_Timer_1_Zyklus_Fr 0;
BA_ "GenSigSendType" SG_ 1398 MOD_Set_Timer_1_Zyklus_Fr 7;
BA_ "NWM-WakeupAllowed" SG_ 1398 MOD_Set_Timer_2_Zyklus_Fr 0;
BA_ "GenSigSendType" SG_ 1398 MOD_Set_Timer_2_Zyklus_Fr 7;
BA_ "NWM-WakeupAllowed" SG_ 1398 MOD_Set_Timer_3_Zyklus_Fr 0;
BA_ "GenSigSendType" SG_ 1398 MOD_Set_Timer_3_Zyklus_Fr 7;
BA_ "NWM-WakeupAllowed" SG_ 1398 MOD_Set_Timer_1_Zyklus_Sa 0;
BA_ "GenSigSendType" SG_ 1398 MOD_Set_Timer_1_Zyklus_Sa 7;
BA_ "NWM-WakeupAllowed" SG_ 1398 MOD_Set_Timer_2_Zyklus_Sa 0;
BA_ "GenSigSendType" SG_ 1398 MOD_Set_Timer_2_Zyklus_Sa 7;
BA_ "NWM-WakeupAllowed" SG_ 1398 MOD_Set_Timer_3_Zyklus_Sa 0;
BA_ "GenSigSendType" SG_ 1398 MOD_Set_Timer_3_Zyklus_Sa 7;
BA_ "NWM-WakeupAllowed" SG_ 1398 MOD_Set_Timer_1_Zyklus_So 0;
BA_ "GenSigSendType" SG_ 1398 MOD_Set_Timer_1_Zyklus_So 7;
BA_ "NWM-WakeupAllowed" SG_ 1398 MOD_Set_Timer_2_Zyklus_So 0;
BA_ "GenSigSendType" SG_ 1398 MOD_Set_Timer_2_Zyklus_So 7;
BA_ "NWM-WakeupAllowed" SG_ 1398 MOD_Set_Timer_3_Zyklus_So 0;
BA_ "GenSigSendType" SG_ 1398 MOD_Set_Timer_3_Zyklus_So 7;
BA_ "NWM-WakeupAllowed" SG_ 1398 MOD_Set_Timer_1_Zyklus_WH 0;
BA_ "GenSigSendType" SG_ 1398 MOD_Set_Timer_1_Zyklus_WH 7;
BA_ "NWM-WakeupAllowed" SG_ 1398 MOD_Set_Timer_2_Zyklus_WH 0;
BA_ "GenSigSendType" SG_ 1398 MOD_Set_Timer_2_Zyklus_WH 7;
BA_ "NWM-WakeupAllowed" SG_ 1398 MOD_Set_Timer_MUX 0;
BA_ "NWM-WakeupAllowed" SG_ 1398 MOD_Set_Timer_3_Zyklus_WH 0;
BA_ "GenSigSendType" SG_ 1398 MOD_Set_Timer_3_Zyklus_WH 7;
BA_ "GenSigStartValue" SG_ 1398 MOD_Set_Nachtstrom_X_Std_Anf 62;
BA_ "NWM-WakeupAllowed" SG_ 1398 MOD_Set_Nachtstrom_X_Std_Anf 0;
BA_ "NWM-WakeupAllowed" SG_ 1398 MOD_Set_Nachtstrom_Prof 0;
BA_ "GenSigStartValue" SG_ 1398 MOD_Set_Nachtstrom_X_Std_End 62;
BA_ "NWM-WakeupAllowed" SG_ 1398 MOD_Set_Nachtstrom_X_Std_End 0;
BA_ "NWM-WakeupAllowed" SG_ 1398 MOD_Set_Nachtstrom_Akt_Prof 0;
BA_ "NWM-WakeupAllowed" SG_ 1398 MOD_Set_Abbruch_Klima 0;
BA_ "NWM-WakeupAllowed" SG_ 1398 MOD_Set_Sofortstart_Klima 0;
BA_ "NWM-WakeupAllowed" SG_ 1398 MOD_Anf_Spiegel_anklappen 0;
BA_ "NWM-WakeupAllowed" SG_ 1398 MOD_Anf_ZV 0;
BA_ "NWM-WakeupAllowed" SG_ 1397 HVLM_Status_Timer_7_Laden 0;
BA_ "GenSigSendType" SG_ 1397 HVLM_Status_Timer_7_Laden 7;
BA_ "NWM-WakeupAllowed" SG_ 1397 HVLM_Ladetexte 0;
BA_ "GenSigStartValue" SG_ 1397 HVLM_Status_Timer_4_Jahr 126;
BA_ "NWM-WakeupAllowed" SG_ 1397 HVLM_Status_Timer_4_Jahr 0;
BA_ "GenSigSendType" SG_ 1397 HVLM_Status_Timer_4_Jahr 7;
BA_ "Fehlerwert" SG_ 1397 HVLM_Status_Timer_4_Minute 63;
BA_ "GenSigStartValue" SG_ 1397 HVLM_Status_Timer_4_Minute 62;
BA_ "NWM-WakeupAllowed" SG_ 1397 HVLM_Status_Timer_4_Minute 0;
BA_ "GenSigSendType" SG_ 1397 HVLM_Status_Timer_4_Minute 7;
BA_ "Fehlerwert" SG_ 1397 HVLM_Status_Timer_4_Monat 15;
BA_ "NWM-WakeupAllowed" SG_ 1397 HVLM_Status_Timer_4_Monat 0;
BA_ "GenSigSendType" SG_ 1397 HVLM_Status_Timer_4_Monat 7;
BA_ "Fehlerwert" SG_ 1397 HVLM_Status_Timer_4_Stunde 31;
BA_ "GenSigStartValue" SG_ 1397 HVLM_Status_Timer_4_Stunde 30;
BA_ "NWM-WakeupAllowed" SG_ 1397 HVLM_Status_Timer_4_Stunde 0;
BA_ "GenSigSendType" SG_ 1397 HVLM_Status_Timer_4_Stunde 7;
BA_ "NWM-WakeupAllowed" SG_ 1397 HVLM_Status_Timer_4_Tag 0;
BA_ "GenSigSendType" SG_ 1397 HVLM_Status_Timer_4_Tag 7;
BA_ "NWM-WakeupAllowed" SG_ 1397 HVLM_Status_Timer_4_Laden 0;
BA_ "GenSigSendType" SG_ 1397 HVLM_Status_Timer_4_Laden 7;
BA_ "NWM-WakeupAllowed" SG_ 1397 HVLM_Status_Timer_4_Vorklima 0;
BA_ "GenSigSendType" SG_ 1397 HVLM_Status_Timer_4_Vorklima 7;
BA_ "NWM-WakeupAllowed" SG_ 1397 HVLM_Status_Timer_4_Zyklus_Mo 0;
BA_ "GenSigSendType" SG_ 1397 HVLM_Status_Timer_4_Zyklus_Mo 7;
BA_ "NWM-WakeupAllowed" SG_ 1397 HVLM_Status_Timer_2_Vorklima 0;
BA_ "GenSigSendType" SG_ 1397 HVLM_Status_Timer_2_Vorklima 7;
BA_ "NWM-WakeupAllowed" SG_ 1397 HVLM_Status_Timer_3_Vorklima 0;
BA_ "GenSigSendType" SG_ 1397 HVLM_Status_Timer_3_Vorklima 7;
BA_ "NWM-WakeupAllowed" SG_ 1397 HVLM_Status_Timer_1_Zyklus_Mo 0;
BA_ "GenSigSendType" SG_ 1397 HVLM_Status_Timer_1_Zyklus_Mo 7;
BA_ "NWM-WakeupAllowed" SG_ 1397 HVLM_Status_Timer_2_Zyklus_Mo 0;
BA_ "GenSigSendType" SG_ 1397 HVLM_Status_Timer_2_Zyklus_Mo 7;
BA_ "NWM-WakeupAllowed" SG_ 1397 HVLM_Status_Timer_3_Zyklus_Mo 0;
BA_ "GenSigSendType" SG_ 1397 HVLM_Status_Timer_3_Zyklus_Mo 7;
BA_ "NWM-WakeupAllowed" SG_ 1397 HVLM_Status_Timer_1_Zyklus_Di 0;
BA_ "GenSigSendType" SG_ 1397 HVLM_Status_Timer_1_Zyklus_Di 7;
BA_ "NWM-WakeupAllowed" SG_ 1397 HVLM_Status_Timer_2_Zyklus_Di 0;
BA_ "GenSigSendType" SG_ 1397 HVLM_Status_Timer_2_Zyklus_Di 7;
BA_ "NWM-WakeupAllowed" SG_ 1397 HVLM_Status_Timer_3_Zyklus_Di 0;
BA_ "GenSigSendType" SG_ 1397 HVLM_Status_Timer_3_Zyklus_Di 7;
BA_ "NWM-WakeupAllowed" SG_ 1397 HVLM_Status_Timer_1_Zyklus_Mi 0;
BA_ "GenSigSendType" SG_ 1397 HVLM_Status_Timer_1_Zyklus_Mi 7;
BA_ "NWM-WakeupAllowed" SG_ 1397 HVLM_Status_Timer_2_Zyklus_Mi 0;
BA_ "GenSigSendType" SG_ 1397 HVLM_Status_Timer_2_Zyklus_Mi 7;
BA_ "NWM-WakeupAllowed" SG_ 1397 HVLM_Status_Timer_3_Zyklus_Mi 0;
BA_ "GenSigSendType" SG_ 1397 HVLM_Status_Timer_3_Zyklus_Mi 7;
BA_ "NWM-WakeupAllowed" SG_ 1397 HVLM_Status_Timer_1_Zyklus_Do 0;
BA_ "GenSigSendType" SG_ 1397 HVLM_Status_Timer_1_Zyklus_Do 7;
BA_ "NWM-WakeupAllowed" SG_ 1397 HVLM_Status_Timer_2_Zyklus_Do 0;
BA_ "GenSigSendType" SG_ 1397 HVLM_Status_Timer_2_Zyklus_Do 7;
BA_ "NWM-WakeupAllowed" SG_ 1397 HVLM_Status_Timer_3_Zyklus_Do 0;
BA_ "GenSigSendType" SG_ 1397 HVLM_Status_Timer_3_Zyklus_Do 7;
BA_ "NWM-WakeupAllowed" SG_ 1397 HVLM_Status_Timer_1_Zyklus_Fr 0;
BA_ "GenSigSendType" SG_ 1397 HVLM_Status_Timer_1_Zyklus_Fr 7;
BA_ "NWM-WakeupAllowed" SG_ 1397 HVLM_Status_Timer_2_Zyklus_Fr 0;
BA_ "GenSigSendType" SG_ 1397 HVLM_Status_Timer_2_Zyklus_Fr 7;
BA_ "NWM-WakeupAllowed" SG_ 1397 HVLM_Status_Timer_3_Zyklus_Fr 0;
BA_ "GenSigSendType" SG_ 1397 HVLM_Status_Timer_3_Zyklus_Fr 7;
BA_ "NWM-WakeupAllowed" SG_ 1397 HVLM_Status_Timer_1_Zyklus_Sa 0;
BA_ "GenSigSendType" SG_ 1397 HVLM_Status_Timer_1_Zyklus_Sa 7;
BA_ "NWM-WakeupAllowed" SG_ 1397 HVLM_Status_Timer_2_Zyklus_Sa 0;
BA_ "GenSigSendType" SG_ 1397 HVLM_Status_Timer_2_Zyklus_Sa 7;
BA_ "NWM-WakeupAllowed" SG_ 1397 HVLM_Status_Timer_3_Zyklus_Sa 0;
BA_ "GenSigSendType" SG_ 1397 HVLM_Status_Timer_3_Zyklus_Sa 7;
BA_ "NWM-WakeupAllowed" SG_ 1397 HVLM_Status_Timer_1_Zyklus_So 0;
BA_ "GenSigSendType" SG_ 1397 HVLM_Status_Timer_1_Zyklus_So 7;
BA_ "NWM-WakeupAllowed" SG_ 1397 HVLM_Status_Timer_2_Zyklus_So 0;
BA_ "GenSigSendType" SG_ 1397 HVLM_Status_Timer_2_Zyklus_So 7;
BA_ "NWM-WakeupAllowed" SG_ 1397 HVLM_Status_Timer_3_Zyklus_So 0;
BA_ "GenSigSendType" SG_ 1397 HVLM_Status_Timer_3_Zyklus_So 7;
BA_ "NWM-WakeupAllowed" SG_ 1397 HVLM_Status_Timer_1_Zyklus_WH 0;
BA_ "GenSigSendType" SG_ 1397 HVLM_Status_Timer_1_Zyklus_WH 7;
BA_ "NWM-WakeupAllowed" SG_ 1397 HVLM_Status_Timer_2_Zyklus_WH 0;
BA_ "GenSigSendType" SG_ 1397 HVLM_Status_Timer_2_Zyklus_WH 7;
BA_ "NWM-WakeupAllowed" SG_ 1397 HVLM_Status_Timer_MUX 0;
BA_ "NWM-WakeupAllowed" SG_ 1397 HVLM_Status_Timer_3_Zyklus_WH 0;
BA_ "GenSigSendType" SG_ 1397 HVLM_Status_Timer_3_Zyklus_WH 7;
BA_ "GenSigStartValue" SG_ 1397 HVLM_Status_Nachtstrom_X_Std_Anf 62;
BA_ "NWM-WakeupAllowed" SG_ 1397 HVLM_Status_Nachtstrom_X_Std_Anf 0;
BA_ "NWM-WakeupAllowed" SG_ 1397 HVLM_Status_Nachtstrom_Prof 0;
BA_ "GenSigStartValue" SG_ 1397 HVLM_Status_Nachtstrom_X_Std_End 62;
BA_ "NWM-WakeupAllowed" SG_ 1397 HVLM_Status_Nachtstrom_X_Std_End 0;
BA_ "NWM-WakeupAllowed" SG_ 1397 HVLM_Status_Nachtstrom_Akt_Prof 0;
BA_ "Fehlerwert" SG_ 1397 HVLM_Status_Laden 7;
BA_ "GenSigStartValue" SG_ 1397 HVLM_Status_Laden 6;
BA_ "NWM-WakeupAllowed" SG_ 1397 HVLM_Status_Laden 0;
BA_ "NWM-WakeupAllowed" SG_ 1397 HVLM_Status_Timer_4_Zyklus_Di 0;
BA_ "GenSigSendType" SG_ 1397 HVLM_Status_Timer_4_Zyklus_Di 7;
BA_ "NWM-WakeupAllowed" SG_ 1397 HVLM_Status_Timer_4_Zyklus_Mi 0;
BA_ "GenSigSendType" SG_ 1397 HVLM_Status_Timer_4_Zyklus_Mi 7;
BA_ "NWM-WakeupAllowed" SG_ 1397 HVLM_Status_Timer_4_Zyklus_Do 0;
BA_ "GenSigSendType" SG_ 1397 HVLM_Status_Timer_4_Zyklus_Do 7;
BA_ "NWM-WakeupAllowed" SG_ 1397 HVLM_Status_Timer_4_Zyklus_Fr 0;
BA_ "GenSigSendType" SG_ 1397 HVLM_Status_Timer_4_Zyklus_Fr 7;
BA_ "GenSigStartValue" SG_ 1397 HVLM_Status_Timer_1_Jahr 126;
BA_ "NWM-WakeupAllowed" SG_ 1397 HVLM_Status_Timer_1_Jahr 0;
BA_ "GenSigSendType" SG_ 1397 HVLM_Status_Timer_1_Jahr 7;
BA_ "GenSigStartValue" SG_ 1397 HVLM_Status_Timer_2_Jahr 126;
BA_ "NWM-WakeupAllowed" SG_ 1397 HVLM_Status_Timer_2_Jahr 0;
BA_ "GenSigSendType" SG_ 1397 HVLM_Status_Timer_2_Jahr 7;
BA_ "GenSigStartValue" SG_ 1397 HVLM_Status_Timer_3_Jahr 126;
BA_ "NWM-WakeupAllowed" SG_ 1397 HVLM_Status_Timer_3_Jahr 0;
BA_ "GenSigSendType" SG_ 1397 HVLM_Status_Timer_3_Jahr 7;
BA_ "GenSigStartValue" SG_ 1397 HVLM_Status_Timer_7_Jahr 126;
BA_ "NWM-WakeupAllowed" SG_ 1397 HVLM_Status_Timer_7_Jahr 0;
BA_ "GenSigSendType" SG_ 1397 HVLM_Status_Timer_7_Jahr 7;
BA_ "Fehlerwert" SG_ 1397 HVLM_Status_Timer_1_Minute 63;
BA_ "GenSigStartValue" SG_ 1397 HVLM_Status_Timer_1_Minute 62;
BA_ "NWM-WakeupAllowed" SG_ 1397 HVLM_Status_Timer_1_Minute 0;
BA_ "GenSigSendType" SG_ 1397 HVLM_Status_Timer_1_Minute 7;
BA_ "Fehlerwert" SG_ 1397 HVLM_Status_Timer_2_Minute 63;
BA_ "GenSigStartValue" SG_ 1397 HVLM_Status_Timer_2_Minute 62;
BA_ "NWM-WakeupAllowed" SG_ 1397 HVLM_Status_Timer_2_Minute 0;
BA_ "GenSigSendType" SG_ 1397 HVLM_Status_Timer_2_Minute 7;
BA_ "Fehlerwert" SG_ 1397 HVLM_Status_Timer_3_Minute 63;
BA_ "GenSigStartValue" SG_ 1397 HVLM_Status_Timer_3_Minute 62;
BA_ "NWM-WakeupAllowed" SG_ 1397 HVLM_Status_Timer_3_Minute 0;
BA_ "GenSigSendType" SG_ 1397 HVLM_Status_Timer_3_Minute 7;
BA_ "Fehlerwert" SG_ 1397 HVLM_Status_Timer_7_Minute 63;
BA_ "GenSigStartValue" SG_ 1397 HVLM_Status_Timer_7_Minute 62;
BA_ "NWM-WakeupAllowed" SG_ 1397 HVLM_Status_Timer_7_Minute 0;
BA_ "GenSigSendType" SG_ 1397 HVLM_Status_Timer_7_Minute 7;
BA_ "Fehlerwert" SG_ 1397 HVLM_Status_Timer_1_Monat 15;
BA_ "NWM-WakeupAllowed" SG_ 1397 HVLM_Status_Timer_1_Monat 0;
BA_ "GenSigSendType" SG_ 1397 HVLM_Status_Timer_1_Monat 7;
BA_ "Fehlerwert" SG_ 1397 HVLM_Status_Timer_2_Monat 15;
BA_ "NWM-WakeupAllowed" SG_ 1397 HVLM_Status_Timer_2_Monat 0;
BA_ "GenSigSendType" SG_ 1397 HVLM_Status_Timer_2_Monat 7;
BA_ "Fehlerwert" SG_ 1397 HVLM_Status_Timer_3_Monat 15;
BA_ "NWM-WakeupAllowed" SG_ 1397 HVLM_Status_Timer_3_Monat 0;
BA_ "GenSigSendType" SG_ 1397 HVLM_Status_Timer_3_Monat 7;
BA_ "Fehlerwert" SG_ 1397 HVLM_Status_Timer_7_Monat 15;
BA_ "NWM-WakeupAllowed" SG_ 1397 HVLM_Status_Timer_7_Monat 0;
BA_ "GenSigSendType" SG_ 1397 HVLM_Status_Timer_7_Monat 7;
BA_ "Fehlerwert" SG_ 1397 HVLM_Status_Timer_1_Stunde 31;
BA_ "GenSigStartValue" SG_ 1397 HVLM_Status_Timer_1_Stunde 30;
BA_ "NWM-WakeupAllowed" SG_ 1397 HVLM_Status_Timer_1_Stunde 0;
BA_ "GenSigSendType" SG_ 1397 HVLM_Status_Timer_1_Stunde 7;
BA_ "Fehlerwert" SG_ 1397 HVLM_Status_Timer_2_Stunde 31;
BA_ "GenSigStartValue" SG_ 1397 HVLM_Status_Timer_2_Stunde 30;
BA_ "NWM-WakeupAllowed" SG_ 1397 HVLM_Status_Timer_2_Stunde 0;
BA_ "GenSigSendType" SG_ 1397 HVLM_Status_Timer_2_Stunde 7;
BA_ "Fehlerwert" SG_ 1397 HVLM_Status_Timer_3_Stunde 31;
BA_ "GenSigStartValue" SG_ 1397 HVLM_Status_Timer_3_Stunde 30;
BA_ "NWM-WakeupAllowed" SG_ 1397 HVLM_Status_Timer_3_Stunde 0;
BA_ "GenSigSendType" SG_ 1397 HVLM_Status_Timer_3_Stunde 7;
BA_ "Fehlerwert" SG_ 1397 HVLM_Status_Timer_7_Stunde 31;
BA_ "GenSigStartValue" SG_ 1397 HVLM_Status_Timer_7_Stunde 30;
BA_ "NWM-WakeupAllowed" SG_ 1397 HVLM_Status_Timer_7_Stunde 0;
BA_ "GenSigSendType" SG_ 1397 HVLM_Status_Timer_7_Stunde 7;
BA_ "NWM-WakeupAllowed" SG_ 1397 HVLM_Status_Timer_1_Tag 0;
BA_ "GenSigSendType" SG_ 1397 HVLM_Status_Timer_1_Tag 7;
BA_ "NWM-WakeupAllowed" SG_ 1397 HVLM_Status_Timer_2_Tag 0;
BA_ "GenSigSendType" SG_ 1397 HVLM_Status_Timer_2_Tag 7;
BA_ "NWM-WakeupAllowed" SG_ 1397 HVLM_Status_Timer_3_Tag 0;
BA_ "GenSigSendType" SG_ 1397 HVLM_Status_Timer_3_Tag 7;
BA_ "NWM-WakeupAllowed" SG_ 1397 HVLM_Status_Timer_7_Tag 0;
BA_ "GenSigSendType" SG_ 1397 HVLM_Status_Timer_7_Tag 7;
BA_ "NWM-WakeupAllowed" SG_ 1397 HVLM_Status_Timer_1_Laden 0;
BA_ "GenSigSendType" SG_ 1397 HVLM_Status_Timer_1_Laden 7;
BA_ "NWM-WakeupAllowed" SG_ 1397 HVLM_Status_Timer_2_Laden 0;
BA_ "GenSigSendType" SG_ 1397 HVLM_Status_Timer_2_Laden 7;
BA_ "NWM-WakeupAllowed" SG_ 1397 HVLM_Status_Timer_3_Laden 0;
BA_ "GenSigSendType" SG_ 1397 HVLM_Status_Timer_3_Laden 7;
BA_ "NWM-WakeupAllowed" SG_ 1397 HVLM_Status_Timer_1_Vorklima 0;
BA_ "GenSigSendType" SG_ 1397 HVLM_Status_Timer_1_Vorklima 7;
BA_ "NWM-WakeupAllowed" SG_ 1397 HVLM_Status_Timer_4_Zyklus_Sa 0;
BA_ "GenSigSendType" SG_ 1397 HVLM_Status_Timer_4_Zyklus_Sa 7;
BA_ "NWM-WakeupAllowed" SG_ 1397 HVLM_Status_Timer_4_Zyklus_So 0;
BA_ "GenSigSendType" SG_ 1397 HVLM_Status_Timer_4_Zyklus_So 7;
BA_ "NWM-WakeupAllowed" SG_ 1397 HVLM_Status_Timer_4_Zyklus_WH 0;
BA_ "GenSigSendType" SG_ 1397 HVLM_Status_Timer_4_Zyklus_WH 7;
BA_ "GenSigStartValue" SG_ 1446 OBC_KomponentenFehler_01 2;
BA_ "NWM-WakeupAllowed" SG_ 1446 OBC_KomponentenFehler_01 0;
BA_ "GenSigStartValue" SG_ 1446 OBC_KomponentenFehler_02 2;
BA_ "NWM-WakeupAllowed" SG_ 1446 OBC_KomponentenFehler_02 0;
BA_ "GenSigStartValue" SG_ 1446 OBC_KomponentenFehler_03 2;
BA_ "NWM-WakeupAllowed" SG_ 1446 OBC_KomponentenFehler_03 0;
BA_ "GenSigStartValue" SG_ 1446 OBC_KomponentenFehler_04 2;
BA_ "NWM-WakeupAllowed" SG_ 1446 OBC_KomponentenFehler_04 0;
BA_ "GenSigStartValue" SG_ 1446 OBC_KomponentenFehler_05 2;
BA_ "NWM-WakeupAllowed" SG_ 1446 OBC_KomponentenFehler_05 0;
BA_ "GenSigStartValue" SG_ 1446 OBC_KomponentenFehler_06 2;
BA_ "NWM-WakeupAllowed" SG_ 1446 OBC_KomponentenFehler_06 0;
BA_ "GenSigStartValue" SG_ 1446 OBC_KomponentenFehler_07 2;
BA_ "NWM-WakeupAllowed" SG_ 1446 OBC_KomponentenFehler_07 0;
BA_ "GenSigStartValue" SG_ 1446 OBC_KomponentenFehler_08 2;
BA_ "NWM-WakeupAllowed" SG_ 1446 OBC_KomponentenFehler_08 0;
BA_ "GenSigStartValue" SG_ 1446 OBC_KomponentenFehler_09 2;
BA_ "NWM-WakeupAllowed" SG_ 1446 OBC_KomponentenFehler_09 0;
BA_ "GenSigStartValue" SG_ 1446 OBC_KomponentenFehler_10 2;
BA_ "NWM-WakeupAllowed" SG_ 1446 OBC_KomponentenFehler_10 0;
BA_ "GenSigStartValue" SG_ 1446 OBC_KomponentenFehler_11 2;
BA_ "NWM-WakeupAllowed" SG_ 1446 OBC_KomponentenFehler_11 0;
BA_ "GenSigStartValue" SG_ 1446 OBC_KomponentenFehler_12 2;
BA_ "NWM-WakeupAllowed" SG_ 1446 OBC_KomponentenFehler_12 0;
BA_ "GenSigStartValue" SG_ 1446 OBC_KomponentenFehler_13 2;
BA_ "NWM-WakeupAllowed" SG_ 1446 OBC_KomponentenFehler_13 0;
BA_ "GenSigStartValue" SG_ 1446 OBC_KomponentenFehler_14 2;
BA_ "NWM-WakeupAllowed" SG_ 1446 OBC_KomponentenFehler_14 0;
BA_ "GenSigStartValue" SG_ 1446 OBC_KomponentenFehler_15 2;
BA_ "NWM-WakeupAllowed" SG_ 1446 OBC_KomponentenFehler_15 0;
BA_ "GenSigStartValue" SG_ 1446 OBC_KomponentenFehler_16 2;
BA_ "NWM-WakeupAllowed" SG_ 1446 OBC_KomponentenFehler_16 0;
BA_ "GenSigStartValue" SG_ 1446 OBC_KomponentenFehler_17 2;
BA_ "NWM-WakeupAllowed" SG_ 1446 OBC_KomponentenFehler_17 0;
BA_ "GenSigStartValue" SG_ 1446 OBC_KomponentenFehler_18 2;
BA_ "NWM-WakeupAllowed" SG_ 1446 OBC_KomponentenFehler_18 0;
BA_ "GenSigStartValue" SG_ 1446 OBC_KomponentenFehler_19 2;
BA_ "NWM-WakeupAllowed" SG_ 1446 OBC_KomponentenFehler_19 0;
BA_ "GenSigStartValue" SG_ 1446 OBC_KomponentenFehler_20 2;
BA_ "NWM-WakeupAllowed" SG_ 1446 OBC_KomponentenFehler_20 0;
BA_ "GenSigStartValue" SG_ 1446 OBC_KomponentenFehler_21 2;
BA_ "NWM-WakeupAllowed" SG_ 1446 OBC_KomponentenFehler_21 0;
BA_ "GenSigStartValue" SG_ 1446 OBC_KomponentenFehler_22 2;
BA_ "NWM-WakeupAllowed" SG_ 1446 OBC_KomponentenFehler_22 0;
BA_ "GenSigStartValue" SG_ 1446 OBC_KomponentenFehler_23 2;
BA_ "NWM-WakeupAllowed" SG_ 1446 OBC_KomponentenFehler_23 0;
BA_ "GenSigStartValue" SG_ 1446 OBC_KomponentenFehler_24 2;
BA_ "NWM-WakeupAllowed" SG_ 1446 OBC_KomponentenFehler_24 0;
BA_ "GenSigStartValue" SG_ 1446 OBC_KomponentenFehler_25 2;
BA_ "NWM-WakeupAllowed" SG_ 1446 OBC_KomponentenFehler_25 0;
BA_ "GenSigStartValue" SG_ 1446 OBC_KomponentenFehler_26 2;
BA_ "NWM-WakeupAllowed" SG_ 1446 OBC_KomponentenFehler_26 0;
BA_ "GenSigStartValue" SG_ 1446 OBC_KomponentenFehler_27 2;
BA_ "NWM-WakeupAllowed" SG_ 1446 OBC_KomponentenFehler_27 0;
BA_ "GenSigStartValue" SG_ 1446 OBC_KomponentenFehler_28 2;
BA_ "NWM-WakeupAllowed" SG_ 1446 OBC_KomponentenFehler_28 0;
BA_ "GenSigStartValue" SG_ 1446 OBC_KomponentenFehler_29 2;
BA_ "NWM-WakeupAllowed" SG_ 1446 OBC_KomponentenFehler_29 0;
BA_ "GenSigStartValue" SG_ 1446 OBC_KomponentenFehler_30 2;
BA_ "NWM-WakeupAllowed" SG_ 1446 OBC_KomponentenFehler_30 0;
BA_ "GenSigStartValue" SG_ 1446 OBC_KomponentenFehler_31 2;
BA_ "NWM-WakeupAllowed" SG_ 1446 OBC_KomponentenFehler_31 0;
BA_ "GenSigStartValue" SG_ 1446 OBC_KomponentenFehler_32 2;
BA_ "NWM-WakeupAllowed" SG_ 1446 OBC_KomponentenFehler_32 0;
BA_REL_ "GenSigTimeoutTime" BU_SG_REL_ Motor_MED17_Hybrid SG_ 1413 SI_QRS_Mode 5000;
BA_REL_ "GenSigTimeoutTime" BU_SG_REL_ Motor_EDC17_Pirol SG_ 1413 SI_QRS_Mode 5000;
BA_REL_ "GenSigTimeoutTime" BU_SG_REL_ Motor_EDC17_Pirol SG_ 1413 SI_T_Mode 5000;
BA_REL_ "GenSigTimeoutTime" BU_SG_REL_ Motor_MED17_Hybrid SG_ 1413 SI_T_Mode 5000;
BA_REL_ "GenSigTimeoutTime" BU_SG_REL_ Airbag SG_ 1413 SI_T_Mode 5000;
BA_REL_ "GenSigTimeoutTime" BU_SG_REL_ Motor_MED17_Hybrid SG_ 2616986624 CCP_MO_CRO_02_Data 500;
BA_REL_ "GenSigTimeoutTime" BU_SG_REL_ Motor_EDC17_Pirol SG_ 2616986624 CCP_MO_CRO_02_Data 500;
BA_REL_ "GenSigTimeoutTime" BU_SG_REL_ Motor_MED17_Hybrid SG_ 480 CCP_MO_CRO_01_Data 500;
BA_REL_ "GenSigTimeoutTime" BU_SG_REL_ Motor_EDC17_Pirol SG_ 480 CCP_MO_CRO_01_Data 500;
BA_REL_ "GenSigTimeoutTime" BU_SG_REL_ Ladegeraet_PAG_PF SG_ 1728 NMH_GW_Start_1 2000;
BA_REL_ "GenSigTimeoutTime" BU_SG_REL_ Getriebe_Derivate SG_ 1728 NMH_GW_Start_1 2000;
BA_REL_ "GenSigTimeoutTime" BU_SG_REL_ Motor_MED17_Hybrid SG_ 1728 NMH_GW_Start_1 2000;
BA_REL_ "GenSigTimeoutTime" BU_SG_REL_ Motor_EDC17_Pirol SG_ 1728 NMH_GW_Start_1 2000;
BA_REL_ "GenSigTimeoutTime" BU_SG_REL_ LEH_Hybrid SG_ 1728 NMH_GW_Start_1 2000;
BA_REL_ "GenSigTimeoutTime" BU_SG_REL_ BMS_Hybrid SG_ 1728 NMH_GW_Start_1 2000;
BA_REL_ "GenSigTimeoutTime" BU_SG_REL_ Motor_MED17_Hybrid SG_ 1327 OBD_Fehler_Laengsbeschleunigung 2000;
BA_REL_ "GenSigTimeoutTime" BU_SG_REL_ Motor_MED17_Hybrid SG_ 1327 OBD_Fehler_Vordrucksensor 2000;
BA_REL_ "GenSigTimeoutTime" BU_SG_REL_ GW_Applikation_Derivate SG_ 1381 HVLM_IstSpannung_HV 5000;
BA_REL_ "GenSigTimeoutTime" BU_SG_REL_ GW_Routing_Derivate SG_ 1381 HVLM_IstSpannung_HV 5000;
BA_REL_ "GenSigTimeoutTime" BU_SG_REL_ GW_Routing_Derivate SG_ 1381 HVLM_HV_Abstellzeit 5000;
BA_REL_ "GenSigTimeoutTime" BU_SG_REL_ GW_Routing_Derivate SG_ 1381 HVLM_Zustand_LED 5000;
BA_REL_ "GenSigTimeoutTime" BU_SG_REL_ GW_Routing_Derivate SG_ 1381 HVLM_MaxLadezeitDCHV 5000;
BA_REL_ "GenSigTimeoutTime" BU_SG_REL_ GW_Routing_Derivate SG_ 1381 HVLM_MaxStrom_Netz 5000;
BA_REL_ "GenSigTimeoutTime" BU_SG_REL_ GW_Routing_Derivate SG_ 1381 HVLM_LG_Sollmodus 5000;
BA_REL_ "GenSigTimeoutTime" BU_SG_REL_ GW_Routing_Derivate SG_ 1381 HVLM_FreigabeTankdeckel 5000;
BA_REL_ "GenSigTimeoutTime" BU_SG_REL_ GW_Routing_Derivate SG_ 1381 HVLM_Stecker_Verriegeln 5000;
BA_REL_ "GenSigTimeoutTime" BU_SG_REL_ GW_Routing_Derivate SG_ 1381 HVLM_Start_Spannungsmessung_DCLS 5000;
BA_REL_ "GenSigTimeoutTime" BU_SG_REL_ GW_Routing_Derivate SG_ 1381 HVLM_Sollzustand_Taster_Profi000 5000;
BA_REL_ "GenSigTimeoutTime" BU_SG_REL_ GW_Routing_Derivate SG_ 1381 HVLM_Sollzustand_Taster_Sofor001 5000;
BA_REL_ "GenSigTimeoutTime" BU_SG_REL_ GW_Routing_Derivate SG_ 1381 HVLM_FreigabeKlimatisierung 5000;
BA_REL_ "GenSigTimeoutTime" BU_SG_REL_ GW_Routing_Derivate SG_ 1381 HVLM_Ladetexte 5000;
BA_REL_ "GenSigTimeoutTime" BU_SG_REL_ Ladegeraet_PAG_PF SG_ 1534 KBI_Set_Timer_MUX 5000;
BA_REL_ "GenSigTimeoutTime" BU_SG_REL_ Ladegeraet_PAG_PF SG_ 1534 KBI_Set_Timer_1_Jahr 5000;
BA_REL_ "GenSigTimeoutTime" BU_SG_REL_ Ladegeraet_PAG_PF SG_ 1534 KBI_Set_Timer_2_Jahr 5000;
BA_REL_ "GenSigTimeoutTime" BU_SG_REL_ Ladegeraet_PAG_PF SG_ 1534 KBI_Set_Timer_3_Jahr 5000;
BA_REL_ "GenSigTimeoutTime" BU_SG_REL_ Ladegeraet_PAG_PF SG_ 1534 KBI_Set_Timer_4_Jahr 5000;
BA_REL_ "GenSigTimeoutTime" BU_SG_REL_ Ladegeraet_PAG_PF SG_ 1534 KBI_Set_Timer_1_Minute 5000;
BA_REL_ "GenSigTimeoutTime" BU_SG_REL_ Ladegeraet_PAG_PF SG_ 1534 KBI_Set_Timer_2_Minute 5000;
BA_REL_ "GenSigTimeoutTime" BU_SG_REL_ Ladegeraet_PAG_PF SG_ 1534 KBI_Set_Timer_3_Minute 5000;
BA_REL_ "GenSigTimeoutTime" BU_SG_REL_ Ladegeraet_PAG_PF SG_ 1534 KBI_Set_Timer_4_Minute 5000;
BA_REL_ "GenSigTimeoutTime" BU_SG_REL_ Ladegeraet_PAG_PF SG_ 1534 KBI_Set_Timer_1_Monat 5000;
BA_REL_ "GenSigTimeoutTime" BU_SG_REL_ Ladegeraet_PAG_PF SG_ 1534 KBI_Set_Timer_2_Monat 5000;
BA_REL_ "GenSigTimeoutTime" BU_SG_REL_ Ladegeraet_PAG_PF SG_ 1534 KBI_Set_Timer_3_Monat 5000;
BA_REL_ "GenSigTimeoutTime" BU_SG_REL_ Ladegeraet_PAG_PF SG_ 1534 KBI_Set_Timer_4_Monat 5000;
BA_REL_ "GenSigTimeoutTime" BU_SG_REL_ Ladegeraet_PAG_PF SG_ 1534 KBI_Set_Timer_1_Stunde 5000;
BA_REL_ "GenSigTimeoutTime" BU_SG_REL_ Ladegeraet_PAG_PF SG_ 1534 KBI_Set_Timer_2_Stunde 5000;
BA_REL_ "GenSigTimeoutTime" BU_SG_REL_ Ladegeraet_PAG_PF SG_ 1534 KBI_Set_Timer_3_Stunde 5000;
BA_REL_ "GenSigTimeoutTime" BU_SG_REL_ Ladegeraet_PAG_PF SG_ 1534 KBI_Set_Timer_4_Stunde 5000;
BA_REL_ "GenSigTimeoutTime" BU_SG_REL_ Ladegeraet_PAG_PF SG_ 1534 KBI_Set_Timer_1_Tag 5000;
BA_REL_ "GenSigTimeoutTime" BU_SG_REL_ Ladegeraet_PAG_PF SG_ 1534 KBI_Set_Timer_2_Tag 5000;
BA_REL_ "GenSigTimeoutTime" BU_SG_REL_ Ladegeraet_PAG_PF SG_ 1534 KBI_Set_Timer_3_Tag 5000;
BA_REL_ "GenSigTimeoutTime" BU_SG_REL_ Ladegeraet_PAG_PF SG_ 1534 KBI_Set_Timer_4_Tag 5000;
BA_REL_ "GenSigTimeoutTime" BU_SG_REL_ Ladegeraet_PAG_PF SG_ 1534 KBI_Set_Timer_1_Laden 5000;
BA_REL_ "GenSigTimeoutTime" BU_SG_REL_ Ladegeraet_PAG_PF SG_ 1534 KBI_Set_Timer_2_Laden 5000;
BA_REL_ "GenSigTimeoutTime" BU_SG_REL_ Ladegeraet_PAG_PF SG_ 1534 KBI_Set_Timer_3_Laden 5000;
BA_REL_ "GenSigTimeoutTime" BU_SG_REL_ Ladegeraet_PAG_PF SG_ 1534 KBI_Set_Timer_4_Laden 5000;
BA_REL_ "GenSigTimeoutTime" BU_SG_REL_ Ladegeraet_PAG_PF SG_ 1534 KBI_Set_Timer_1_Vorklima 5000;
BA_REL_ "GenSigTimeoutTime" BU_SG_REL_ Ladegeraet_PAG_PF SG_ 1534 KBI_Set_Timer_2_Vorklima 5000;
BA_REL_ "GenSigTimeoutTime" BU_SG_REL_ Ladegeraet_PAG_PF SG_ 1534 KBI_Set_Timer_3_Vorklima 5000;
BA_REL_ "GenSigTimeoutTime" BU_SG_REL_ Ladegeraet_PAG_PF SG_ 1534 KBI_Set_Timer_4_Vorklima 5000;
BA_REL_ "GenSigTimeoutTime" BU_SG_REL_ Ladegeraet_PAG_PF SG_ 1534 KBI_Set_Timer_1_Zyklus_Mo 5000;
BA_REL_ "GenSigTimeoutTime" BU_SG_REL_ Ladegeraet_PAG_PF SG_ 1534 KBI_Set_Timer_2_Zyklus_Mo 5000;
BA_REL_ "GenSigTimeoutTime" BU_SG_REL_ Ladegeraet_PAG_PF SG_ 1534 KBI_Set_Timer_3_Zyklus_Mo 5000;
BA_REL_ "GenSigTimeoutTime" BU_SG_REL_ Ladegeraet_PAG_PF SG_ 1534 KBI_Set_Timer_4_Zyklus_Mo 5000;
BA_REL_ "GenSigTimeoutTime" BU_SG_REL_ Ladegeraet_PAG_PF SG_ 1534 KBI_Set_Timer_1_Zyklus_Di 5000;
BA_REL_ "GenSigTimeoutTime" BU_SG_REL_ Ladegeraet_PAG_PF SG_ 1534 KBI_Set_Timer_2_Zyklus_Di 5000;
BA_REL_ "GenSigTimeoutTime" BU_SG_REL_ Ladegeraet_PAG_PF SG_ 1534 KBI_Set_Timer_3_Zyklus_Di 5000;
BA_REL_ "GenSigTimeoutTime" BU_SG_REL_ Ladegeraet_PAG_PF SG_ 1534 KBI_Set_Timer_4_Zyklus_Di 5000;
BA_REL_ "GenSigTimeoutTime" BU_SG_REL_ Ladegeraet_PAG_PF SG_ 1534 KBI_Set_Timer_1_Zyklus_Mi 5000;
BA_REL_ "GenSigTimeoutTime" BU_SG_REL_ Ladegeraet_PAG_PF SG_ 1534 KBI_Set_Timer_2_Zyklus_Mi 5000;
BA_REL_ "GenSigTimeoutTime" BU_SG_REL_ Ladegeraet_PAG_PF SG_ 1534 KBI_Set_Timer_3_Zyklus_Mi 5000;
BA_REL_ "GenSigTimeoutTime" BU_SG_REL_ Ladegeraet_PAG_PF SG_ 1534 KBI_Set_Timer_4_Zyklus_Mi 5000;
BA_REL_ "GenSigTimeoutTime" BU_SG_REL_ Ladegeraet_PAG_PF SG_ 1534 KBI_Set_Timer_1_Zyklus_Do 5000;
BA_REL_ "GenSigTimeoutTime" BU_SG_REL_ Ladegeraet_PAG_PF SG_ 1534 KBI_Set_Timer_2_Zyklus_Do 5000;
BA_REL_ "GenSigTimeoutTime" BU_SG_REL_ Ladegeraet_PAG_PF SG_ 1534 KBI_Set_Timer_3_Zyklus_Do 5000;
BA_REL_ "GenSigTimeoutTime" BU_SG_REL_ Ladegeraet_PAG_PF SG_ 1534 KBI_Set_Timer_4_Zyklus_Do 5000;
BA_REL_ "GenSigTimeoutTime" BU_SG_REL_ Ladegeraet_PAG_PF SG_ 1534 KBI_Set_Timer_1_Zyklus_Fr 5000;
BA_REL_ "GenSigTimeoutTime" BU_SG_REL_ Ladegeraet_PAG_PF SG_ 1534 KBI_Set_Timer_2_Zyklus_Fr 5000;
BA_REL_ "GenSigTimeoutTime" BU_SG_REL_ Ladegeraet_PAG_PF SG_ 1534 KBI_Set_Timer_3_Zyklus_Fr 5000;
BA_REL_ "GenSigTimeoutTime" BU_SG_REL_ Ladegeraet_PAG_PF SG_ 1534 KBI_Set_Timer_4_Zyklus_Fr 5000;
BA_REL_ "GenSigTimeoutTime" BU_SG_REL_ Ladegeraet_PAG_PF SG_ 1534 KBI_Set_Timer_1_Zyklus_Sa 5000;
BA_REL_ "GenSigTimeoutTime" BU_SG_REL_ Ladegeraet_PAG_PF SG_ 1534 KBI_Set_Timer_2_Zyklus_Sa 5000;
BA_REL_ "GenSigTimeoutTime" BU_SG_REL_ Ladegeraet_PAG_PF SG_ 1534 KBI_Set_Timer_3_Zyklus_Sa 5000;
BA_REL_ "GenSigTimeoutTime" BU_SG_REL_ Ladegeraet_PAG_PF SG_ 1534 KBI_Set_Timer_4_Zyklus_Sa 5000;
BA_REL_ "GenSigTimeoutTime" BU_SG_REL_ Ladegeraet_PAG_PF SG_ 1534 KBI_Set_Timer_1_Zyklus_So 5000;
BA_REL_ "GenSigTimeoutTime" BU_SG_REL_ Ladegeraet_PAG_PF SG_ 1534 KBI_Set_Timer_2_Zyklus_So 5000;
BA_REL_ "GenSigTimeoutTime" BU_SG_REL_ Ladegeraet_PAG_PF SG_ 1534 KBI_Set_Timer_3_Zyklus_So 5000;
BA_REL_ "GenSigTimeoutTime" BU_SG_REL_ Ladegeraet_PAG_PF SG_ 1534 KBI_Set_Timer_4_Zyklus_So 5000;
BA_REL_ "GenSigTimeoutTime" BU_SG_REL_ Ladegeraet_PAG_PF SG_ 1534 KBI_Set_Timer_1_Zyklus_WH 5000;
BA_REL_ "GenSigTimeoutTime" BU_SG_REL_ Ladegeraet_PAG_PF SG_ 1534 KBI_Set_Timer_2_Zyklus_WH 5000;
BA_REL_ "GenSigTimeoutTime" BU_SG_REL_ Ladegeraet_PAG_PF SG_ 1534 KBI_Set_Timer_3_Zyklus_WH 5000;
BA_REL_ "GenSigTimeoutTime" BU_SG_REL_ Ladegeraet_PAG_PF SG_ 1534 KBI_Set_Timer_4_Zyklus_WH 5000;
BA_REL_ "GenSigTimeoutTime" BU_SG_REL_ BMS_Hybrid SG_ 1631 MO_Energieinhalt_BMS 5000;
BA_REL_ "GenSigTimeoutTime" BU_SG_REL_ Ladegeraet_PAG_PF SG_ 1398 MOD_Set_Timerladen 5000;
BA_REL_ "GenSigTimeoutTime" BU_SG_REL_ Ladegeraet_PAG_PF SG_ 1398 MOD_Set_Sofortladen 5000;
BA_REL_ "GenSigTimeoutTime" BU_SG_REL_ Ladegeraet_PAG_PF SG_ 1398 MOD_Set_Timer_4_Jahr 5000;
BA_REL_ "GenSigTimeoutTime" BU_SG_REL_ Ladegeraet_PAG_PF SG_ 1398 MOD_Set_Timer_4_Minute 5000;
BA_REL_ "GenSigTimeoutTime" BU_SG_REL_ Ladegeraet_PAG_PF SG_ 1398 MOD_Set_Timer_4_Monat 5000;
BA_REL_ "GenSigTimeoutTime" BU_SG_REL_ Ladegeraet_PAG_PF SG_ 1398 MOD_Set_Timer_4_Stunde 5000;
BA_REL_ "GenSigTimeoutTime" BU_SG_REL_ Ladegeraet_PAG_PF SG_ 1398 MOD_Set_Timer_4_Tag 5000;
BA_REL_ "GenSigTimeoutTime" BU_SG_REL_ Ladegeraet_PAG_PF SG_ 1398 MOD_Set_Timer_4_Laden 5000;
BA_REL_ "GenSigTimeoutTime" BU_SG_REL_ Ladegeraet_PAG_PF SG_ 1398 MOD_Set_Timer_4_Vorklima 5000;
BA_REL_ "GenSigTimeoutTime" BU_SG_REL_ Ladegeraet_PAG_PF SG_ 1398 MOD_Set_Timer_4_Zyklus_Mo 5000;
BA_REL_ "GenSigTimeoutTime" BU_SG_REL_ Ladegeraet_PAG_PF SG_ 1398 MOD_Set_Timer_4_Zyklus_Di 5000;
BA_REL_ "GenSigTimeoutTime" BU_SG_REL_ Ladegeraet_PAG_PF SG_ 1398 MOD_Set_Timer_4_Zyklus_Mi 5000;
BA_REL_ "GenSigTimeoutTime" BU_SG_REL_ Ladegeraet_PAG_PF SG_ 1398 MOD_Set_Timer_4_Zyklus_Do 5000;
BA_REL_ "GenSigTimeoutTime" BU_SG_REL_ Ladegeraet_PAG_PF SG_ 1398 MOD_Set_Timer_4_Zyklus_Fr 5000;
BA_REL_ "GenSigTimeoutTime" BU_SG_REL_ Ladegeraet_PAG_PF SG_ 1398 MOD_Set_Timer_4_Zyklus_Sa 5000;
BA_REL_ "GenSigTimeoutTime" BU_SG_REL_ Ladegeraet_PAG_PF SG_ 1398 MOD_Set_Timer_4_Zyklus_So 5000;
BA_REL_ "GenSigTimeoutTime" BU_SG_REL_ Ladegeraet_PAG_PF SG_ 1398 MOD_Set_Timer_4_Zyklus_WH 5000;
BA_REL_ "GenSigTimeoutTime" BU_SG_REL_ Ladegeraet_PAG_PF SG_ 1398 MOD_Set_Timer_1_Jahr 5000;
BA_REL_ "GenSigTimeoutTime" BU_SG_REL_ Ladegeraet_PAG_PF SG_ 1398 MOD_Set_Timer_2_Jahr 5000;
BA_REL_ "GenSigTimeoutTime" BU_SG_REL_ Ladegeraet_PAG_PF SG_ 1398 MOD_Set_Timer_3_Jahr 5000;
BA_REL_ "GenSigTimeoutTime" BU_SG_REL_ Ladegeraet_PAG_PF SG_ 1398 MOD_Set_Timer_1_Minute 5000;
BA_REL_ "GenSigTimeoutTime" BU_SG_REL_ Ladegeraet_PAG_PF SG_ 1398 MOD_Set_Timer_2_Minute 5000;
BA_REL_ "GenSigTimeoutTime" BU_SG_REL_ Ladegeraet_PAG_PF SG_ 1398 MOD_Set_Timer_3_Minute 5000;
BA_REL_ "GenSigTimeoutTime" BU_SG_REL_ Ladegeraet_PAG_PF SG_ 1398 MOD_Set_Timer_1_Monat 5000;
BA_REL_ "GenSigTimeoutTime" BU_SG_REL_ Ladegeraet_PAG_PF SG_ 1398 MOD_Set_Timer_2_Monat 5000;
BA_REL_ "GenSigTimeoutTime" BU_SG_REL_ Ladegeraet_PAG_PF SG_ 1398 MOD_Set_Timer_3_Monat 5000;
BA_REL_ "GenSigTimeoutTime" BU_SG_REL_ Ladegeraet_PAG_PF SG_ 1398 MOD_Set_Timer_1_Stunde 5000;
BA_REL_ "GenSigTimeoutTime" BU_SG_REL_ Ladegeraet_PAG_PF SG_ 1398 MOD_Set_Timer_2_Stunde 5000;
BA_REL_ "GenSigTimeoutTime" BU_SG_REL_ Ladegeraet_PAG_PF SG_ 1398 MOD_Set_Timer_3_Stunde 5000;
BA_REL_ "GenSigTimeoutTime" BU_SG_REL_ Ladegeraet_PAG_PF SG_ 1398 MOD_Set_Timer_1_Tag 5000;
BA_REL_ "GenSigTimeoutTime" BU_SG_REL_ Ladegeraet_PAG_PF SG_ 1398 MOD_Set_Timer_2_Tag 5000;
BA_REL_ "GenSigTimeoutTime" BU_SG_REL_ Ladegeraet_PAG_PF SG_ 1398 MOD_Set_Timer_3_Tag 5000;
BA_REL_ "GenSigTimeoutTime" BU_SG_REL_ Ladegeraet_PAG_PF SG_ 1398 MOD_Set_Timer_1_Laden 5000;
BA_REL_ "GenSigTimeoutTime" BU_SG_REL_ Ladegeraet_PAG_PF SG_ 1398 MOD_Set_Timer_2_Laden 5000;
BA_REL_ "GenSigTimeoutTime" BU_SG_REL_ Ladegeraet_PAG_PF SG_ 1398 MOD_Set_Timer_3_Laden 5000;
BA_REL_ "GenSigTimeoutTime" BU_SG_REL_ Ladegeraet_PAG_PF SG_ 1398 MOD_Set_Timer_1_Vorklima 5000;
BA_REL_ "GenSigTimeoutTime" BU_SG_REL_ Ladegeraet_PAG_PF SG_ 1398 MOD_Set_Timer_2_Vorklima 5000;
BA_REL_ "GenSigTimeoutTime" BU_SG_REL_ Ladegeraet_PAG_PF SG_ 1398 MOD_Set_Timer_3_Vorklima 5000;
BA_REL_ "GenSigTimeoutTime" BU_SG_REL_ Ladegeraet_PAG_PF SG_ 1398 MOD_Set_Timer_1_Zyklus_Mo 5000;
BA_REL_ "GenSigTimeoutTime" BU_SG_REL_ Ladegeraet_PAG_PF SG_ 1398 MOD_Set_Timer_2_Zyklus_Mo 5000;
BA_REL_ "GenSigTimeoutTime" BU_SG_REL_ Ladegeraet_PAG_PF SG_ 1398 MOD_Set_Timer_3_Zyklus_Mo 5000;
BA_REL_ "GenSigTimeoutTime" BU_SG_REL_ Ladegeraet_PAG_PF SG_ 1398 MOD_Set_Timer_1_Zyklus_Di 5000;
BA_REL_ "GenSigTimeoutTime" BU_SG_REL_ Ladegeraet_PAG_PF SG_ 1398 MOD_Set_Timer_2_Zyklus_Di 5000;
BA_REL_ "GenSigTimeoutTime" BU_SG_REL_ Ladegeraet_PAG_PF SG_ 1398 MOD_Set_Timer_3_Zyklus_Di 5000;
BA_REL_ "GenSigTimeoutTime" BU_SG_REL_ Ladegeraet_PAG_PF SG_ 1398 MOD_Set_Timer_1_Zyklus_Mi 5000;
BA_REL_ "GenSigTimeoutTime" BU_SG_REL_ Ladegeraet_PAG_PF SG_ 1398 MOD_Set_Timer_2_Zyklus_Mi 5000;
BA_REL_ "GenSigTimeoutTime" BU_SG_REL_ Ladegeraet_PAG_PF SG_ 1398 MOD_Set_Timer_3_Zyklus_Mi 5000;
BA_REL_ "GenSigTimeoutTime" BU_SG_REL_ Ladegeraet_PAG_PF SG_ 1398 MOD_Set_Timer_1_Zyklus_Do 5000;
BA_REL_ "GenSigTimeoutTime" BU_SG_REL_ Ladegeraet_PAG_PF SG_ 1398 MOD_Set_Timer_2_Zyklus_Do 5000;
BA_REL_ "GenSigTimeoutTime" BU_SG_REL_ Ladegeraet_PAG_PF SG_ 1398 MOD_Set_Timer_3_Zyklus_Do 5000;
BA_REL_ "GenSigTimeoutTime" BU_SG_REL_ Ladegeraet_PAG_PF SG_ 1398 MOD_Set_Timer_1_Zyklus_Fr 5000;
BA_REL_ "GenSigTimeoutTime" BU_SG_REL_ Ladegeraet_PAG_PF SG_ 1398 MOD_Set_Timer_2_Zyklus_Fr 5000;
BA_REL_ "GenSigTimeoutTime" BU_SG_REL_ Ladegeraet_PAG_PF SG_ 1398 MOD_Set_Timer_3_Zyklus_Fr 5000;
BA_REL_ "GenSigTimeoutTime" BU_SG_REL_ Ladegeraet_PAG_PF SG_ 1398 MOD_Set_Timer_1_Zyklus_Sa 5000;
BA_REL_ "GenSigTimeoutTime" BU_SG_REL_ Ladegeraet_PAG_PF SG_ 1398 MOD_Set_Timer_2_Zyklus_Sa 5000;
BA_REL_ "GenSigTimeoutTime" BU_SG_REL_ Ladegeraet_PAG_PF SG_ 1398 MOD_Set_Timer_3_Zyklus_Sa 5000;
BA_REL_ "GenSigTimeoutTime" BU_SG_REL_ Ladegeraet_PAG_PF SG_ 1398 MOD_Set_Timer_1_Zyklus_So 5000;
BA_REL_ "GenSigTimeoutTime" BU_SG_REL_ Ladegeraet_PAG_PF SG_ 1398 MOD_Set_Timer_2_Zyklus_So 5000;
BA_REL_ "GenSigTimeoutTime" BU_SG_REL_ Ladegeraet_PAG_PF SG_ 1398 MOD_Set_Timer_3_Zyklus_So 5000;
BA_REL_ "GenSigTimeoutTime" BU_SG_REL_ Ladegeraet_PAG_PF SG_ 1398 MOD_Set_Timer_1_Zyklus_WH 5000;
BA_REL_ "GenSigTimeoutTime" BU_SG_REL_ Ladegeraet_PAG_PF SG_ 1398 MOD_Set_Timer_2_Zyklus_WH 5000;
BA_REL_ "GenSigTimeoutTime" BU_SG_REL_ Ladegeraet_PAG_PF SG_ 1398 MOD_Set_Timer_MUX 5000;
BA_REL_ "GenSigTimeoutTime" BU_SG_REL_ Ladegeraet_PAG_PF SG_ 1398 MOD_Set_Timer_3_Zyklus_WH 5000;
BA_REL_ "GenSigTimeoutTime" BU_SG_REL_ Ladegeraet_PAG_PF SG_ 1398 MOD_Set_Nachtstrom_X_Std_Anf 5000;
BA_REL_ "GenSigTimeoutTime" BU_SG_REL_ Ladegeraet_PAG_PF SG_ 1398 MOD_Set_Nachtstrom_Prof 5000;
BA_REL_ "GenSigTimeoutTime" BU_SG_REL_ Ladegeraet_PAG_PF SG_ 1398 MOD_Set_Nachtstrom_X_Std_End 5000;
BA_REL_ "GenSigTimeoutTime" BU_SG_REL_ Ladegeraet_PAG_PF SG_ 1398 MOD_Set_Nachtstrom_Akt_Prof 5000;
BA_REL_ "GenSigTimeoutTime" BU_SG_REL_ Ladegeraet_PAG_PF SG_ 1398 MOD_Set_Abbruch_Klima 5000;
BA_REL_ "GenSigTimeoutTime" BU_SG_REL_ Ladegeraet_PAG_PF SG_ 1398 MOD_Set_Sofortstart_Klima 5000;
BA_REL_ "GenSigTimeoutTime" BU_SG_REL_ GW_Routing_Derivate SG_ 1397 HVLM_Status_Timer_7_Laden 5000;
BA_REL_ "GenSigTimeoutTime" BU_SG_REL_ GW_Routing_Derivate SG_ 1397 HVLM_Ladetexte 5000;
BA_REL_ "GenSigTimeoutTime" BU_SG_REL_ GW_Routing_Derivate SG_ 1397 HVLM_Status_Timer_4_Jahr 5000;
BA_REL_ "GenSigTimeoutTime" BU_SG_REL_ GW_Routing_Derivate SG_ 1397 HVLM_Status_Timer_4_Minute 5000;
BA_REL_ "GenSigTimeoutTime" BU_SG_REL_ GW_Routing_Derivate SG_ 1397 HVLM_Status_Timer_4_Monat 5000;
BA_REL_ "GenSigTimeoutTime" BU_SG_REL_ GW_Routing_Derivate SG_ 1397 HVLM_Status_Timer_4_Stunde 5000;
BA_REL_ "GenSigTimeoutTime" BU_SG_REL_ GW_Routing_Derivate SG_ 1397 HVLM_Status_Timer_4_Tag 5000;
BA_REL_ "GenSigTimeoutTime" BU_SG_REL_ GW_Routing_Derivate SG_ 1397 HVLM_Status_Timer_4_Laden 5000;
BA_REL_ "GenSigTimeoutTime" BU_SG_REL_ GW_Routing_Derivate SG_ 1397 HVLM_Status_Timer_4_Vorklima 5000;
BA_REL_ "GenSigTimeoutTime" BU_SG_REL_ GW_Routing_Derivate SG_ 1397 HVLM_Status_Timer_4_Zyklus_Mo 5000;
BA_REL_ "GenSigTimeoutTime" BU_SG_REL_ GW_Routing_Derivate SG_ 1397 HVLM_Status_Timer_2_Vorklima 5000;
BA_REL_ "GenSigTimeoutTime" BU_SG_REL_ GW_Routing_Derivate SG_ 1397 HVLM_Status_Timer_3_Vorklima 5000;
BA_REL_ "GenSigTimeoutTime" BU_SG_REL_ GW_Routing_Derivate SG_ 1397 HVLM_Status_Timer_1_Zyklus_Mo 5000;
BA_REL_ "GenSigTimeoutTime" BU_SG_REL_ GW_Routing_Derivate SG_ 1397 HVLM_Status_Timer_2_Zyklus_Mo 5000;
BA_REL_ "GenSigTimeoutTime" BU_SG_REL_ GW_Routing_Derivate SG_ 1397 HVLM_Status_Timer_3_Zyklus_Mo 5000;
BA_REL_ "GenSigTimeoutTime" BU_SG_REL_ GW_Routing_Derivate SG_ 1397 HVLM_Status_Timer_1_Zyklus_Di 5000;
BA_REL_ "GenSigTimeoutTime" BU_SG_REL_ GW_Routing_Derivate SG_ 1397 HVLM_Status_Timer_2_Zyklus_Di 5000;
BA_REL_ "GenSigTimeoutTime" BU_SG_REL_ GW_Routing_Derivate SG_ 1397 HVLM_Status_Timer_3_Zyklus_Di 5000;
BA_REL_ "GenSigTimeoutTime" BU_SG_REL_ GW_Routing_Derivate SG_ 1397 HVLM_Status_Timer_1_Zyklus_Mi 5000;
BA_REL_ "GenSigTimeoutTime" BU_SG_REL_ GW_Routing_Derivate SG_ 1397 HVLM_Status_Timer_2_Zyklus_Mi 5000;
BA_REL_ "GenSigTimeoutTime" BU_SG_REL_ GW_Routing_Derivate SG_ 1397 HVLM_Status_Timer_3_Zyklus_Mi 5000;
BA_REL_ "GenSigTimeoutTime" BU_SG_REL_ GW_Routing_Derivate SG_ 1397 HVLM_Status_Timer_1_Zyklus_Do 5000;
BA_REL_ "GenSigTimeoutTime" BU_SG_REL_ GW_Routing_Derivate SG_ 1397 HVLM_Status_Timer_2_Zyklus_Do 5000;
BA_REL_ "GenSigTimeoutTime" BU_SG_REL_ GW_Routing_Derivate SG_ 1397 HVLM_Status_Timer_3_Zyklus_Do 5000;
BA_REL_ "GenSigTimeoutTime" BU_SG_REL_ GW_Routing_Derivate SG_ 1397 HVLM_Status_Timer_1_Zyklus_Fr 5000;
BA_REL_ "GenSigTimeoutTime" BU_SG_REL_ GW_Routing_Derivate SG_ 1397 HVLM_Status_Timer_2_Zyklus_Fr 5000;
BA_REL_ "GenSigTimeoutTime" BU_SG_REL_ GW_Routing_Derivate SG_ 1397 HVLM_Status_Timer_3_Zyklus_Fr 5000;
BA_REL_ "GenSigTimeoutTime" BU_SG_REL_ GW_Routing_Derivate SG_ 1397 HVLM_Status_Timer_1_Zyklus_Sa 5000;
BA_REL_ "GenSigTimeoutTime" BU_SG_REL_ GW_Routing_Derivate SG_ 1397 HVLM_Status_Timer_2_Zyklus_Sa 5000;
BA_REL_ "GenSigTimeoutTime" BU_SG_REL_ GW_Routing_Derivate SG_ 1397 HVLM_Status_Timer_3_Zyklus_Sa 5000;
BA_REL_ "GenSigTimeoutTime" BU_SG_REL_ GW_Routing_Derivate SG_ 1397 HVLM_Status_Timer_1_Zyklus_So 5000;
BA_REL_ "GenSigTimeoutTime" BU_SG_REL_ GW_Routing_Derivate SG_ 1397 HVLM_Status_Timer_2_Zyklus_So 5000;
BA_REL_ "GenSigTimeoutTime" BU_SG_REL_ GW_Routing_Derivate SG_ 1397 HVLM_Status_Timer_3_Zyklus_So 5000;
BA_REL_ "GenSigTimeoutTime" BU_SG_REL_ GW_Routing_Derivate SG_ 1397 HVLM_Status_Timer_1_Zyklus_WH 5000;
BA_REL_ "GenSigTimeoutTime" BU_SG_REL_ GW_Routing_Derivate SG_ 1397 HVLM_Status_Timer_2_Zyklus_WH 5000;
BA_REL_ "GenSigTimeoutTime" BU_SG_REL_ GW_Routing_Derivate SG_ 1397 HVLM_Status_Timer_MUX 5000;
BA_REL_ "GenSigTimeoutTime" BU_SG_REL_ GW_Routing_Derivate SG_ 1397 HVLM_Status_Timer_3_Zyklus_WH 5000;
BA_REL_ "GenSigTimeoutTime" BU_SG_REL_ GW_Routing_Derivate SG_ 1397 HVLM_Status_Nachtstrom_X_Std_Anf 5000;
BA_REL_ "GenSigTimeoutTime" BU_SG_REL_ GW_Routing_Derivate SG_ 1397 HVLM_Status_Nachtstrom_Prof 5000;
BA_REL_ "GenSigTimeoutTime" BU_SG_REL_ GW_Routing_Derivate SG_ 1397 HVLM_Status_Nachtstrom_X_Std_End 5000;
BA_REL_ "GenSigTimeoutTime" BU_SG_REL_ GW_Routing_Derivate SG_ 1397 HVLM_Status_Nachtstrom_Akt_Prof 5000;
BA_REL_ "GenSigTimeoutTime" BU_SG_REL_ GW_Routing_Derivate SG_ 1397 HVLM_Status_Laden 5000;
BA_REL_ "GenSigTimeoutTime" BU_SG_REL_ GW_Routing_Derivate SG_ 1397 HVLM_Status_Timer_4_Zyklus_Di 5000;
BA_REL_ "GenSigTimeoutTime" BU_SG_REL_ GW_Routing_Derivate SG_ 1397 HVLM_Status_Timer_4_Zyklus_Mi 5000;
BA_REL_ "GenSigTimeoutTime" BU_SG_REL_ GW_Routing_Derivate SG_ 1397 HVLM_Status_Timer_4_Zyklus_Do 5000;
BA_REL_ "GenSigTimeoutTime" BU_SG_REL_ GW_Routing_Derivate SG_ 1397 HVLM_Status_Timer_4_Zyklus_Fr 5000;
BA_REL_ "GenSigTimeoutTime" BU_SG_REL_ GW_Routing_Derivate SG_ 1397 HVLM_Status_Timer_1_Jahr 5000;
BA_REL_ "GenSigTimeoutTime" BU_SG_REL_ GW_Routing_Derivate SG_ 1397 HVLM_Status_Timer_2_Jahr 5000;
BA_REL_ "GenSigTimeoutTime" BU_SG_REL_ GW_Routing_Derivate SG_ 1397 HVLM_Status_Timer_3_Jahr 5000;
BA_REL_ "GenSigTimeoutTime" BU_SG_REL_ GW_Routing_Derivate SG_ 1397 HVLM_Status_Timer_7_Jahr 5000;
BA_REL_ "GenSigTimeoutTime" BU_SG_REL_ GW_Routing_Derivate SG_ 1397 HVLM_Status_Timer_1_Minute 5000;
BA_REL_ "GenSigTimeoutTime" BU_SG_REL_ GW_Routing_Derivate SG_ 1397 HVLM_Status_Timer_2_Minute 5000;
BA_REL_ "GenSigTimeoutTime" BU_SG_REL_ GW_Routing_Derivate SG_ 1397 HVLM_Status_Timer_3_Minute 5000;
BA_REL_ "GenSigTimeoutTime" BU_SG_REL_ GW_Routing_Derivate SG_ 1397 HVLM_Status_Timer_7_Minute 5000;
BA_REL_ "GenSigTimeoutTime" BU_SG_REL_ GW_Routing_Derivate SG_ 1397 HVLM_Status_Timer_1_Monat 5000;
BA_REL_ "GenSigTimeoutTime" BU_SG_REL_ GW_Routing_Derivate SG_ 1397 HVLM_Status_Timer_2_Monat 5000;
BA_REL_ "GenSigTimeoutTime" BU_SG_REL_ GW_Routing_Derivate SG_ 1397 HVLM_Status_Timer_3_Monat 5000;
BA_REL_ "GenSigTimeoutTime" BU_SG_REL_ GW_Routing_Derivate SG_ 1397 HVLM_Status_Timer_7_Monat 5000;
BA_REL_ "GenSigTimeoutTime" BU_SG_REL_ GW_Routing_Derivate SG_ 1397 HVLM_Status_Timer_1_Stunde 5000;
BA_REL_ "GenSigTimeoutTime" BU_SG_REL_ GW_Routing_Derivate SG_ 1397 HVLM_Status_Timer_2_Stunde 5000;
BA_REL_ "GenSigTimeoutTime" BU_SG_REL_ GW_Routing_Derivate SG_ 1397 HVLM_Status_Timer_3_Stunde 5000;
BA_REL_ "GenSigTimeoutTime" BU_SG_REL_ GW_Routing_Derivate SG_ 1397 HVLM_Status_Timer_7_Stunde 5000;
BA_REL_ "GenSigTimeoutTime" BU_SG_REL_ GW_Routing_Derivate SG_ 1397 HVLM_Status_Timer_1_Tag 5000;
BA_REL_ "GenSigTimeoutTime" BU_SG_REL_ GW_Routing_Derivate SG_ 1397 HVLM_Status_Timer_2_Tag 5000;
BA_REL_ "GenSigTimeoutTime" BU_SG_REL_ GW_Routing_Derivate SG_ 1397 HVLM_Status_Timer_3_Tag 5000;
BA_REL_ "GenSigTimeoutTime" BU_SG_REL_ GW_Routing_Derivate SG_ 1397 HVLM_Status_Timer_7_Tag 5000;
BA_REL_ "GenSigTimeoutTime" BU_SG_REL_ GW_Routing_Derivate SG_ 1397 HVLM_Status_Timer_1_Laden 5000;
BA_REL_ "GenSigTimeoutTime" BU_SG_REL_ GW_Routing_Derivate SG_ 1397 HVLM_Status_Timer_2_Laden 5000;
BA_REL_ "GenSigTimeoutTime" BU_SG_REL_ GW_Routing_Derivate SG_ 1397 HVLM_Status_Timer_3_Laden 5000;
BA_REL_ "GenSigTimeoutTime" BU_SG_REL_ GW_Routing_Derivate SG_ 1397 HVLM_Status_Timer_1_Vorklima 5000;
BA_REL_ "GenSigTimeoutTime" BU_SG_REL_ GW_Routing_Derivate SG_ 1397 HVLM_Status_Timer_4_Zyklus_Sa 5000;
BA_REL_ "GenSigTimeoutTime" BU_SG_REL_ GW_Routing_Derivate SG_ 1397 HVLM_Status_Timer_4_Zyklus_So 5000;
BA_REL_ "GenSigTimeoutTime" BU_SG_REL_ GW_Routing_Derivate SG_ 1397 HVLM_Status_Timer_4_Zyklus_WH 5000;
BA_REL_ "GenSigTimeoutTime" BU_SG_REL_ BMS_Hybrid SG_ 1446 OBC_KomponentenFehler_01 5000;
BA_REL_ "GenSigTimeoutTime" BU_SG_REL_ BMS_Hybrid SG_ 1446 OBC_KomponentenFehler_02 5000;
BA_REL_ "GenSigTimeoutTime" BU_SG_REL_ BMS_Hybrid SG_ 1446 OBC_KomponentenFehler_03 5000;
BA_REL_ "GenSigTimeoutTime" BU_SG_REL_ BMS_Hybrid SG_ 1446 OBC_KomponentenFehler_04 5000;
BA_REL_ "GenSigTimeoutTime" BU_SG_REL_ BMS_Hybrid SG_ 1446 OBC_KomponentenFehler_05 5000;
BA_REL_ "GenSigTimeoutTime" BU_SG_REL_ BMS_Hybrid SG_ 1446 OBC_KomponentenFehler_06 5000;
BA_REL_ "GenSigTimeoutTime" BU_SG_REL_ BMS_Hybrid SG_ 1446 OBC_KomponentenFehler_07 5000;
BA_REL_ "GenSigTimeoutTime" BU_SG_REL_ BMS_Hybrid SG_ 1446 OBC_KomponentenFehler_08 5000;
BA_REL_ "GenSigTimeoutTime" BU_SG_REL_ BMS_Hybrid SG_ 1446 OBC_KomponentenFehler_09 5000;
BA_REL_ "GenSigTimeoutTime" BU_SG_REL_ BMS_Hybrid SG_ 1446 OBC_KomponentenFehler_10 5000;
BA_REL_ "GenSigTimeoutTime" BU_SG_REL_ BMS_Hybrid SG_ 1446 OBC_KomponentenFehler_11 5000;
BA_REL_ "GenSigTimeoutTime" BU_SG_REL_ BMS_Hybrid SG_ 1446 OBC_KomponentenFehler_12 5000;
BA_REL_ "GenSigTimeoutTime" BU_SG_REL_ BMS_Hybrid SG_ 1446 OBC_KomponentenFehler_13 5000;
BA_REL_ "GenSigTimeoutTime" BU_SG_REL_ BMS_Hybrid SG_ 1446 OBC_KomponentenFehler_14 5000;
BA_REL_ "GenSigTimeoutTime" BU_SG_REL_ BMS_Hybrid SG_ 1446 OBC_KomponentenFehler_15 5000;
BA_REL_ "GenSigTimeoutTime" BU_SG_REL_ BMS_Hybrid SG_ 1446 OBC_KomponentenFehler_16 5000;
BA_REL_ "GenSigTimeoutTime" BU_SG_REL_ BMS_Hybrid SG_ 1446 OBC_KomponentenFehler_17 5000;
BA_REL_ "GenSigTimeoutTime" BU_SG_REL_ BMS_Hybrid SG_ 1446 OBC_KomponentenFehler_18 5000;
BA_REL_ "GenSigTimeoutTime" BU_SG_REL_ BMS_Hybrid SG_ 1446 OBC_KomponentenFehler_19 5000;
BA_REL_ "GenSigTimeoutTime" BU_SG_REL_ BMS_Hybrid SG_ 1446 OBC_KomponentenFehler_20 5000;
BA_REL_ "GenSigTimeoutTime" BU_SG_REL_ BMS_Hybrid SG_ 1446 OBC_KomponentenFehler_21 5000;
BA_REL_ "GenSigTimeoutTime" BU_SG_REL_ BMS_Hybrid SG_ 1446 OBC_KomponentenFehler_22 5000;
BA_REL_ "GenSigTimeoutTime" BU_SG_REL_ BMS_Hybrid SG_ 1446 OBC_KomponentenFehler_23 5000;
BA_REL_ "GenSigTimeoutTime" BU_SG_REL_ BMS_Hybrid SG_ 1446 OBC_KomponentenFehler_24 5000;
BA_REL_ "GenSigTimeoutTime" BU_SG_REL_ BMS_Hybrid SG_ 1446 OBC_KomponentenFehler_25 5000;
BA_REL_ "GenSigTimeoutTime" BU_SG_REL_ BMS_Hybrid SG_ 1446 OBC_KomponentenFehler_26 5000;
BA_REL_ "GenSigTimeoutTime" BU_SG_REL_ BMS_Hybrid SG_ 1446 OBC_KomponentenFehler_27 5000;
BA_REL_ "GenSigTimeoutTime" BU_SG_REL_ BMS_Hybrid SG_ 1446 OBC_KomponentenFehler_28 5000;
BA_REL_ "GenSigTimeoutTime" BU_SG_REL_ BMS_Hybrid SG_ 1446 OBC_KomponentenFehler_29 5000;
BA_REL_ "GenSigTimeoutTime" BU_SG_REL_ BMS_Hybrid SG_ 1446 OBC_KomponentenFehler_30 5000;
BA_REL_ "GenSigTimeoutTime" BU_SG_REL_ BMS_Hybrid SG_ 1446 OBC_KomponentenFehler_31 5000;
BA_REL_ "GenSigTimeoutTime" BU_SG_REL_ BMS_Hybrid SG_ 1446 OBC_KomponentenFehler_32 5000;
BA_REL_ "HYB_Tx_Baureihe" BU_BO_REL_ GW_Routing_Derivate 901 2;
BA_REL_ "HYB_Tx_Baureihe" BU_BO_REL_ GW_Routing_Derivate 1534 2;
BA_REL_ "HYB_Tx_Baureihe" BU_BO_REL_ GW_Routing_Derivate 1398 2;
VAL_ 1413 GW_KD_Fehler 1 "mind. ein KD-Fehler vorhanden" 0 "kein KD-Fehler" ;
VAL_ 1413 SI_QRS_Mode 0 "QRS_Messmodus_nicht_aktiv" 1 "QRS_Messmodus_aktiv" ;
VAL_ 1413 SI_NWDF_gueltig 1 "NWDF_wird_unterstuetzt" 0 "NWDF_wird_nicht_unterstuetzt" ;
VAL_ 1413 SI_NWDF 1 "Ueberwachung_freigeben" 0 "Ueberwachung_nicht_freigeben" ;
VAL_ 1413 SI_Fahrwerk_Sleep 1 "Busruhe" 0 "keine Busruhe" ;
VAL_ 1413 SI_CAN_Crash_Sleep 1 "Busruhe" 0 "keine Busruhe" ;
VAL_ 1413 SI_CAN_Antrieb_Sleep 1 "Busruhe" 0 "keine Busruhe" ;
VAL_ 1413 SI_CAN_MMI_Sleep 1 "Busruhe" 0 "keine Busruhe" ;
VAL_ 1413 SI_CAN_Komfort_Sleep 1 "Busruhe" 0 "keine Busruhe" ;
VAL_ 1413 SI_T_Mode 1 "Transportmode aktiv" 0 "Transportmode nicht aktiv" ;
VAL_ 901 CHA_Systemstatus 1 "reserviert" 3 "reserviert" 0 "Status in Ordnung" 2 "reserviert" ;
VAL_ 901 CHA_Ziel_FahrPr_MO 4 "FahrPr_4" 0 "nicht_belegt" 2 "FahrPr_2" 1 "FahrPr_1" 3 "FahrPr_3" 6 "FahrPr_6" 5 "FahrPr_5" 7 "FahrPr_7" ;
VAL_ 901 CHA_Ziel_FahrPr_GE 4 "FahrPr_4" 0 "nicht_belegt" 2 "FahrPr_2" 1 "FahrPr_1" 3 "FahrPr_3" 6 "FahrPr_6" 5 "FahrPr_5" 7 "FahrPr_7" ;
VAL_ 901 CHA_Ziel_FahrPr_ST 4 "FahrPr_4" 0 "nicht_belegt" 2 "FahrPr_2" 1 "FahrPr_1" 3 "FahrPr_3" 6 "FahrPr_6" 5 "FahrPr_5" 7 "FahrPr_7" ;
VAL_ 901 CHA_Ziel_FahrPr_SCU 4 "FahrPr_4" 0 "nicht_belegt" 2 "FahrPr_2" 1 "FahrPr_1" 3 "FahrPr_3" 6 "FahrPr_6" 5 "FahrPr_5" 7 "FahrPr_7" ;
VAL_ 901 CHA_Ziel_FahrPr_DR 4 "FahrPr_4" 0 "nicht_belegt" 2 "FahrPr_2" 1 "FahrPr_1" 3 "FahrPr_3" 6 "FahrPr_6" 5 "FahrPr_5" 7 "FahrPr_7" ;
VAL_ 901 CHA_Ziel_FahrPr_QS 4 "FahrPr_4" 0 "nicht_belegt" 2 "FahrPr_2" 1 "FahrPr_1" 3 "FahrPr_3" 6 "FahrPr_6" 5 "FahrPr_5" 7 "FahrPr_7" ;
VAL_ 901 CHA_Ziel_FahrPr_AFS 4 "FahrPr_4" 0 "nicht_belegt" 2 "FahrPr_2" 1 "FahrPr_1" 3 "FahrPr_3" 6 "FahrPr_6" 5 "FahrPr_5" 7 "FahrPr_7" ;
VAL_ 901 CHA_Ziel_FahrPr_RGS 4 "FahrPr_4" 0 "nicht_belegt" 2 "FahrPr_2" 1 "FahrPr_1" 3 "FahrPr_3" 6 "FahrPr_6" 5 "FahrPr_5" 7 "FahrPr_7" ;
VAL_ 901 CHA_Ziel_FahrPr_EPS 4 "FahrPr_4" 0 "nicht_belegt" 2 "FahrPr_2" 1 "FahrPr_1" 3 "FahrPr_3" 6 "FahrPr_6" 5 "FahrPr_5" 7 "FahrPr_7" ;
VAL_ 901 CHA_Ziel_FahrPr_ACC 0 "nicht_belegt" 1 "FahrPr_1" 2 "FahrPr_2" 3 "FahrPr_3" 4 "FahrPr_4" 5 "FahrPr_5" 6 "FahrPr_6" 7 "FahrPr_7" ;
VAL_ 1728 NMH_GW_Start_1 1 "Zustand Start (<--Sleep)" ;
VAL_ 1728 NMH_GW_Start_2 1 "Zustand Start (<--Prepare to Sleep)" ;
VAL_ 1728 NMH_GW_Normal_Mode_1 1 "Zustand Normal Mode (<-- Start)" ;
VAL_ 1728 NMH_GW_Normal_Mode_2 1 "Zustand Normal Mode (<-- Ready to Sleep)" ;
VAL_ 1728 NMH_GW_Per_WakeUp 0 "Wenn_FunktionsWakeup" 1 "CAN_Wakeup__Weckendes_CAN_Segment_siehe_NMH_GW_WakeUp_CAN_Bus" 2 "P_WakeUp_Ursache_unbekannt" 3 "Klemme_15HW__falls_vorhanden" 4 "MOST_Wakeup" 5 "LIN_Wakeup" 6 "KL30_Reset" ;
VAL_ 1728 NMH_GW_Fkt_WakeUp 0 "Wenn_Peripherie_Wakeup" 1 "Funktionswakeup_EM" 2 "Car_Wakeup_empfangen" 3 "VNSM_VehicleNetworkStateManager" 4 "Alarm_RTC__Wecken_weil_Weckzeit_abgelaufen" 5 "Wecken_durch_Diagnose" ;
VAL_ 1728 NMH_GW_NM_aktiv_Klemme_15 1 "Klemme 15 EIN" ;
VAL_ 1728 NMH_GW_NM_aktiv_Diagnose 1 "Diagnose bei Kl 15 aus" ;
VAL_ 1728 NMH_GW_NM_aktiv_Start 1 "Zustand 'START' (NM-high)" ;
VAL_ 1728 NMH_GW_NM_aktiv_BDM 1 "BDM-Kommunikation" ;
VAL_ 1728 NMH_GW_NM_aktiv_Warnblinken 1 "Warnblinken aktiv" ;
VAL_ 1728 NMH_GW_NM_aktiv_ESP 1 "ESP aktiv (Wakeup/Sleep-Konzept)" ;
VAL_ 1728 NMH_GW_NM_aktiv_EMP 1 "EMP_aktiv" ;
VAL_ 1728 NMH_GW_Abschaltstufe_3 1 "BEM aufgrund Abschaltstufe 3 aktiv" ;
VAL_ 1728 NMH_GW_SG_Fehlerdauer 1 "BEM aufgrund Steuergeraetefehlerdauer aktiv" ;
VAL_ 1728 NMH_GW_STH_Wakeup 1 "BEM aktiv aufgrund Standheizungswakeup" ;
VAL_ 1728 NMH_GW_NL_Diagnose 0 "keine_Diagnose_aktiv" 1 "Diagnose_war_lokal_aktiv" ;
VAL_ 1728 NM_GW_Signalfehler 1 "Aktiver_Signalfehler_eingetragen" ;
VAL_ 1728 NMH_GW_TimeOut_Fehler 1 "Aktiver Timeout Fehlerspeichereintrag  " ;
VAL_ 1728 NMH_GW_CAN_Diag_deaktiv 1 "CAN Bus bezogene Eigendiagnose deaktiv" ;
VAL_ 1728 NMH_GW_KompSchutz 0 "inaktiv" 1 "aktiv" ;
VAL_ 1728 NMH_GW_Mute_Mode 1 "MuteMode aktiv" ;
VAL_ 1728 NMH_GW_Transport_Mode 1 "Transportmodus aktiv" ;
VAL_ 1728 NMH_GW_Abschaltstufe_aktiv 1 "Abschaltstufe aktiv" ;
VAL_ 1728 NMH_GW_Eindraht_Fehler 1 "Eindrahtbetrieb erkannt" ;
VAL_ 1728 NMH_GW_ACAN 1 "ACAN aktiv (Wakeup/Sleep-Konzept)" ;
VAL_ 1728 NMH_GW_KombiCAN 1 "KombiCAN aktiv (Wakeup/Sleep-Konzept)" ;
VAL_ 1728 NMH_GW_KomfortCAN 1 "KomfortCAN aktiv (Wakeup/Sleep-Konzept)" ;
VAL_ 1728 NMH_GW_Infotainment 1 "Infotainment aktiv (CAN oder MOST), Wakeup/Sleep-Konzept" ;
VAL_ 1728 NMH_GW_Fahrwerk 1 "BUS_Fahrwerk_aktiv (Wakeup/Sleep-Konzept)" ;
VAL_ 1728 NMH_GW_WakeUp_CAN_Bus 0 "Nicht zutreffend (kein CAN-Wakeup bzw. CarWakeup)" 1 "Antriebs-CAN" 2 "Kombi-CAN" 3 "Komfort-CAN" 4 "Infotainment-CAN (wenn verfuegbar)" 5 "Fahrwerks-CAN" 6 "Diagnose-CAN" ;
VAL_ 1327 OBD_Fehler_Laengsbeschleunigung 0 "kein Fehler" 1 "Fehler Spannungsversorgung" 2 "Interner Fehler" 3 "Fehler Sensor out of range" 4 "Fehler CAN Bus monitoring" 5 "Initialisierung Sensorcluster fehlgeschlagen" 6 "Offset Sensorcluster zu groß" 7 "Fehler Überwachung Plausibilität gegen Modell" 8 "Fehler Sensortausch ohne Anlernen" 9 "frei" 10 "frei" 11 "frei" 12 "frei" 13 "frei" 14 "frei" 15 "frei" ;
VAL_ 1327 OBD_Fehler_Vordrucksensor 0 "kein_Fehler" 1 "Fehler_Plausibilitaet_gegen_BLS" 2 "Fehler_Plausibilitaet_Vordrucksensor" 3 "elektrischer_Fehler" ;
VAL_ 1381 HVLM_IstSpannung_HV 1022 "Init" 1023 "Fehler" ;
VAL_ 1381 HVLM_HV_Abstellzeit 254 "Init" 255 "Fehler" ;
VAL_ 1381 HVLM_Zustand_LED 0 "Farbe_1__aus" 1 "Farbe_2__weiss" 2 "Farbe_3__gelb" 3 "Farbe_4__gruen" 4 "Farbe_5__rot" 5 "Farbe_3_pulsierend" 6 "Farbe_4_pulsierend" 7 "Farbe_5_pulsierend" 8 "Farbe_4_5_pulsierend" 14 "Init" 15 "Fehler" ;
VAL_ 1381 HVLM_MaxLadezeitDCHV 254 "Init" 255 "Fehler" ;
VAL_ 1381 HVLM_MaxStrom_Netz 126 "Init" 127 "Fehler" ;
VAL_ 1381 HVLM_LG_Sollmodus 0 "Standby" 1 "Netzladung" ;
VAL_ 1381 HVLM_FreigabeTankdeckel 0 "keine_Freigabe" 1 "Freigabe" 2 "Init" 3 "Fehler" ;
VAL_ 1381 HVLM_Stecker_Verriegeln 0 "Stecker_entriegeln" 1 "Stecker_verriegeln" 2 "Init" 3 "keine_Anforderung" ;
VAL_ 1381 HVLM_Start_Spannungsmessung_DCLS 0 "inaktiv" 1 "DCLS_mit_Diode_Start_Messung" 2 "DCLS_ohne_Diode_Start_Messung" 3 "reserve" ;
VAL_ 1381 HVLM_Sollzustand_Taster_Profi000 0 "nicht_aktiv" 1 "aktiv" 2 "Init" 3 "Fehler" ;
VAL_ 1381 HVLM_Sollzustand_Taster_Sofor001 0 "nicht_aktiv" 1 "aktiv" 2 "Init" 3 "Fehler" ;
VAL_ 1381 HVLM_FreigabeKlimatisierung 0 "keine_Freigabe" 1 "Freigabe" 2 "Init" 3 "Fehler" ;
VAL_ 1381 HVLM_Ladetexte 0 "Keine_Anzeige" 1 "AC_Laden_nicht_moeglich" 2 "DC_Laden_nicht_moeglich" 3 "AC_und_DC_Laden_nicht_moeglich" ;
VAL_ 1534 KBI_Set_Timer_MUX 0 "leer" 1 "Timer_1" 2 "Timer_2" 3 "Timer_3" 4 "Timer_4" 5 "reserviert" 6 "reserviert" 7 "reserviert" ;
VAL_ 1534 KBI_Set_Timer_1_Jahr 126 "Init" 127 "reserviert" ;
VAL_ 1534 KBI_Set_Timer_2_Jahr 126 "Init" 127 "reserviert" ;
VAL_ 1534 KBI_Set_Timer_3_Jahr 126 "Init" 127 "reserviert" ;
VAL_ 1534 KBI_Set_Timer_4_Jahr 126 "Init" 127 "reserviert" ;
VAL_ 1534 KBI_Set_Timer_1_Minute 60 "reserviert" 61 "reserviert" 62 "Init" 63 "Fehler" ;
VAL_ 1534 KBI_Set_Timer_2_Minute 60 "reserviert" 61 "reserviert" 62 "Init" 63 "Fehler" ;
VAL_ 1534 KBI_Set_Timer_3_Minute 60 "reserviert" 61 "reserviert" 62 "Init" 63 "Fehler" ;
VAL_ 1534 KBI_Set_Timer_4_Minute 60 "reserviert" 61 "reserviert" 62 "Init" 63 "Fehler" ;
VAL_ 1534 KBI_Set_Timer_1_Monat 0 "Init" 14 "reserviert" 15 "Fehler" ;
VAL_ 1534 KBI_Set_Timer_2_Monat 0 "Init" 14 "reserviert" 15 "Fehler" ;
VAL_ 1534 KBI_Set_Timer_3_Monat 0 "Init" 14 "reserviert" 15 "Fehler" ;
VAL_ 1534 KBI_Set_Timer_4_Monat 0 "Init" 14 "reserviert" 15 "Fehler" ;
VAL_ 1534 KBI_Set_Timer_1_Stunde 24 "reserviert" 25 "reserviert" 26 "reserviert" 27 "reserviert" 28 "reserviert" 29 "reserviert" 30 "Init" 31 "Fehler" ;
VAL_ 1534 KBI_Set_Timer_2_Stunde 24 "reserviert" 25 "reserviert" 26 "reserviert" 27 "reserviert" 28 "reserviert" 29 "reserviert" 30 "Init" 31 "Fehler" ;
VAL_ 1534 KBI_Set_Timer_3_Stunde 24 "reserviert" 25 "reserviert" 26 "reserviert" 27 "reserviert" 28 "reserviert" 29 "reserviert" 30 "Init" 31 "Fehler" ;
VAL_ 1534 KBI_Set_Timer_4_Stunde 24 "reserviert" 25 "reserviert" 26 "reserviert" 27 "reserviert" 28 "reserviert" 29 "reserviert" 30 "Init" 31 "Fehler" ;
VAL_ 1534 KBI_Set_Timer_1_Tag 0 "Init" ;
VAL_ 1534 KBI_Set_Timer_2_Tag 0 "Init" ;
VAL_ 1534 KBI_Set_Timer_3_Tag 0 "Init" ;
VAL_ 1534 KBI_Set_Timer_4_Tag 0 "Init" ;
VAL_ 1534 KBI_Set_Timer_1_Laden 0 "Timer_nicht_aktiv" 1 "Timer_aktiv" ;
VAL_ 1534 KBI_Set_Timer_2_Laden 0 "Timer_nicht_aktiv" 1 "Timer_aktiv" ;
VAL_ 1534 KBI_Set_Timer_3_Laden 0 "Timer_nicht_aktiv" 1 "Timer_aktiv" ;
VAL_ 1534 KBI_Set_Timer_4_Laden 0 "Timer_nicht_aktiv" 1 "Timer_aktiv" ;
VAL_ 1534 KBI_Set_Timer_1_Vorklima 0 "Timer_nicht_aktiv" 1 "Timer_aktiv" ;
VAL_ 1534 KBI_Set_Timer_2_Vorklima 0 "Timer_nicht_aktiv" 1 "Timer_aktiv" ;
VAL_ 1534 KBI_Set_Timer_3_Vorklima 0 "Timer_nicht_aktiv" 1 "Timer_aktiv" ;
VAL_ 1534 KBI_Set_Timer_4_Vorklima 0 "Timer_nicht_aktiv" 1 "Timer_aktiv" ;
VAL_ 1534 KBI_Set_Timer_1_Zyklus_Mo 0 "Timer_am_Wochentag_nicht_aktiv" 1 "Timer_am_Wochentag_aktiv" ;
VAL_ 1534 KBI_Set_Timer_2_Zyklus_Mo 0 "Timer_am_Wochentag_nicht_aktiv" 1 "Timer_am_Wochentag_aktiv" ;
VAL_ 1534 KBI_Set_Timer_3_Zyklus_Mo 0 "Timer_am_Wochentag_nicht_aktiv" 1 "Timer_am_Wochentag_aktiv" ;
VAL_ 1534 KBI_Set_Timer_4_Zyklus_Mo 0 "Timer_am_Wochentag_nicht_aktiv" 1 "Timer_am_Wochentag_aktiv" ;
VAL_ 1534 KBI_Set_Timer_1_Zyklus_Di 0 "Timer_am_Wochentag_nicht_aktiv" 1 "Timer_am_Wochentag_aktiv" ;
VAL_ 1534 KBI_Set_Timer_2_Zyklus_Di 0 "Timer_am_Wochentag_nicht_aktiv" 1 "Timer_am_Wochentag_aktiv" ;
VAL_ 1534 KBI_Set_Timer_3_Zyklus_Di 0 "Timer_am_Wochentag_nicht_aktiv" 1 "Timer_am_Wochentag_aktiv" ;
VAL_ 1534 KBI_Set_Timer_4_Zyklus_Di 0 "Timer_am_Wochentag_nicht_aktiv" 1 "Timer_am_Wochentag_aktiv" ;
VAL_ 1534 KBI_Set_Timer_1_Zyklus_Mi 0 "Timer_am_Wochentag_nicht_aktiv" 1 "Timer_am_Wochentag_aktiv" ;
VAL_ 1534 KBI_Set_Timer_2_Zyklus_Mi 0 "Timer_am_Wochentag_nicht_aktiv" 1 "Timer_am_Wochentag_aktiv" ;
VAL_ 1534 KBI_Set_Timer_3_Zyklus_Mi 0 "Timer_am_Wochentag_nicht_aktiv" 1 "Timer_am_Wochentag_aktiv" ;
VAL_ 1534 KBI_Set_Timer_4_Zyklus_Mi 0 "Timer_am_Wochentag_nicht_aktiv" 1 "Timer_am_Wochentag_aktiv" ;
VAL_ 1534 KBI_Set_Timer_1_Zyklus_Do 0 "Timer_am_Wochentag_nicht_aktiv" 1 "Timer_am_Wochentag_aktiv" ;
VAL_ 1534 KBI_Set_Timer_2_Zyklus_Do 0 "Timer_am_Wochentag_nicht_aktiv" 1 "Timer_am_Wochentag_aktiv" ;
VAL_ 1534 KBI_Set_Timer_3_Zyklus_Do 0 "Timer_am_Wochentag_nicht_aktiv" 1 "Timer_am_Wochentag_aktiv" ;
VAL_ 1534 KBI_Set_Timer_4_Zyklus_Do 0 "Timer_am_Wochentag_nicht_aktiv" 1 "Timer_am_Wochentag_aktiv" ;
VAL_ 1534 KBI_Set_Timer_1_Zyklus_Fr 0 "Timer_am_Wochentag_nicht_aktiv" 1 "Timer_am_Wochentag_aktiv" ;
VAL_ 1534 KBI_Set_Timer_2_Zyklus_Fr 0 "Timer_am_Wochentag_nicht_aktiv" 1 "Timer_am_Wochentag_aktiv" ;
VAL_ 1534 KBI_Set_Timer_3_Zyklus_Fr 0 "Timer_am_Wochentag_nicht_aktiv" 1 "Timer_am_Wochentag_aktiv" ;
VAL_ 1534 KBI_Set_Timer_4_Zyklus_Fr 0 "Timer_am_Wochentag_nicht_aktiv" 1 "Timer_am_Wochentag_aktiv" ;
VAL_ 1534 KBI_Set_Timer_1_Zyklus_Sa 0 "Timer_am_Wochentag_nicht_aktiv" 1 "Timer_am_Wochentag_aktiv" ;
VAL_ 1534 KBI_Set_Timer_2_Zyklus_Sa 0 "Timer_am_Wochentag_nicht_aktiv" 1 "Timer_am_Wochentag_aktiv" ;
VAL_ 1534 KBI_Set_Timer_3_Zyklus_Sa 0 "Timer_am_Wochentag_nicht_aktiv" 1 "Timer_am_Wochentag_aktiv" ;
VAL_ 1534 KBI_Set_Timer_4_Zyklus_Sa 0 "Timer_am_Wochentag_nicht_aktiv" 1 "Timer_am_Wochentag_aktiv" ;
VAL_ 1534 KBI_Set_Timer_1_Zyklus_So 0 "Timer_am_Wochentag_nicht_aktiv" 1 "Timer_am_Wochentag_aktiv" ;
VAL_ 1534 KBI_Set_Timer_2_Zyklus_So 0 "Timer_am_Wochentag_nicht_aktiv" 1 "Timer_am_Wochentag_aktiv" ;
VAL_ 1534 KBI_Set_Timer_3_Zyklus_So 0 "Timer_am_Wochentag_nicht_aktiv" 1 "Timer_am_Wochentag_aktiv" ;
VAL_ 1534 KBI_Set_Timer_4_Zyklus_So 0 "Timer_am_Wochentag_nicht_aktiv" 1 "Timer_am_Wochentag_aktiv" ;
VAL_ 1534 KBI_Set_Timer_1_Zyklus_WH 0 "zyklisch" 1 "einmalig" ;
VAL_ 1534 KBI_Set_Timer_2_Zyklus_WH 0 "zyklisch" 1 "einmalig" ;
VAL_ 1534 KBI_Set_Timer_3_Zyklus_WH 0 "zyklisch" 1 "einmalig" ;
VAL_ 1534 KBI_Set_Timer_4_Zyklus_WH 0 "zyklisch" 1 "einmalig" ;
VAL_ 1534 KBI_MOD_Privatsphaere 0 "Init" 1 "MOD verfügbar" 2 "MOD nicht verfügbar" 3 "reserviert" ;
VAL_ 1534 KBI_STH_Status 0 "keine EIN/AUS-Anforderung" 1 "Standheizung EIN" 2 "Standheizung AUS" 3 "reserviert" ;
VAL_ 1631 MO_Energieinhalt_BMS 4094 "Init" 4095 "Fehler" ;
VAL_ 1398 MOD_Set_Timer_5_Jahr 126 "Init" 127 "reserviert" ;
VAL_ 1398 MOD_Set_Timer_6_Jahr 126 "Init" 127 "reserviert" ;
VAL_ 1398 MOD_Set_Timer_5_Minute 60 "reserviert" 61 "reserviert" 62 "Init" 63 "Fehler" ;
VAL_ 1398 MOD_Set_Timer_6_Minute 60 "reserviert" 61 "reserviert" 62 "Init" 63 "Fehler" ;
VAL_ 1398 MOD_Set_Timer_5_Monat 0 "Init" 14 "reserviert" 15 "Fehler" ;
VAL_ 1398 MOD_Set_Timer_6_Monat 0 "Init" 14 "reserviert" 15 "Fehler" ;
VAL_ 1398 MOD_Set_Timer_5_Stunde 24 "reserviert" 25 "reserviert" 26 "reserviert" 27 "reserviert" 28 "reserviert" 29 "reserviert" 30 "Init" 31 "Fehler" ;
VAL_ 1398 MOD_Set_Timer_6_Stunde 24 "reserviert" 25 "reserviert" 26 "reserviert" 27 "reserviert" 28 "reserviert" 29 "reserviert" 30 "Init" 31 "Fehler" ;
VAL_ 1398 MOD_Set_Timer_5_Tag 0 "Init" ;
VAL_ 1398 MOD_Set_Timer_6_Tag 0 "Init" ;
VAL_ 1398 MOD_Set_Timer_5_Vorklima 0 "Timer_nicht_aktiv" 1 "Timer_aktiv" ;
VAL_ 1398 MOD_Set_Timer_6_Vorklima 0 "Timer_nicht_aktiv" 1 "Timer_aktiv" ;
VAL_ 1398 MOD_Set_Timerladen 0 "Init, keine Aktion" 1 "Timerladen" ;
VAL_ 1398 MOD_Set_Sofortladen 0 "Init, keine Aktion" 1 "Sofortladen" ;
VAL_ 1398 MOD_Set_Timer_4_Jahr 126 "Init" 127 "reserviert" ;
VAL_ 1398 MOD_Set_Timer_4_Minute 60 "reserviert" 61 "reserviert" 62 "Init" 63 "Fehler" ;
VAL_ 1398 MOD_Set_Timer_4_Monat 0 "Init" 14 "reserviert" 15 "Fehler" ;
VAL_ 1398 MOD_Set_Timer_4_Stunde 24 "reserviert" 25 "reserviert" 26 "reserviert" 27 "reserviert" 28 "reserviert" 29 "reserviert" 30 "Init" 31 "Fehler" ;
VAL_ 1398 MOD_Set_Timer_4_Tag 0 "Init" ;
VAL_ 1398 MOD_Set_Timer_4_Laden 0 "Timer_nicht_aktiv" 1 "Timer_aktiv" ;
VAL_ 1398 MOD_Set_Timer_4_Vorklima 0 "Timer_nicht_aktiv" 1 "Timer_aktiv" ;
VAL_ 1398 MOD_Set_Timer_4_Zyklus_Mo 0 "Timer_am_Wochentag_nicht_aktiv" 1 "Timer_am_Wochentag_aktiv" ;
VAL_ 1398 MOD_Set_Timer_4_Zyklus_Di 0 "Timer_am_Wochentag_nicht_aktiv" 1 "Timer_am_Wochentag_aktiv" ;
VAL_ 1398 MOD_Set_Timer_4_Zyklus_Mi 0 "Timer_am_Wochentag_nicht_aktiv" 1 "Timer_am_Wochentag_aktiv" ;
VAL_ 1398 MOD_Set_Timer_4_Zyklus_Do 0 "Timer_am_Wochentag_nicht_aktiv" 1 "Timer_am_Wochentag_aktiv" ;
VAL_ 1398 MOD_Set_Timer_4_Zyklus_Fr 0 "Timer_am_Wochentag_nicht_aktiv" 1 "Timer_am_Wochentag_aktiv" ;
VAL_ 1398 MOD_Set_Timer_4_Zyklus_Sa 0 "Timer_am_Wochentag_nicht_aktiv" 1 "Timer_am_Wochentag_aktiv" ;
VAL_ 1398 MOD_Set_Timer_4_Zyklus_So 0 "Timer_am_Wochentag_nicht_aktiv" 1 "Timer_am_Wochentag_aktiv" ;
VAL_ 1398 MOD_Set_Timer_4_Zyklus_WH 0 "zyklisch" 1 "einmalig" ;
VAL_ 1398 MOD_Set_Timer_1_Jahr 126 "Init" 127 "reserviert" ;
VAL_ 1398 MOD_Set_Timer_2_Jahr 126 "Init" 127 "reserviert" ;
VAL_ 1398 MOD_Set_Timer_3_Jahr 126 "Init" 127 "reserviert" ;
VAL_ 1398 MOD_Set_Timer_1_Minute 60 "reserviert" 61 "reserviert" 62 "Init" 63 "Fehler" ;
VAL_ 1398 MOD_Set_Timer_2_Minute 60 "reserviert" 61 "reserviert" 62 "Init" 63 "Fehler" ;
VAL_ 1398 MOD_Set_Timer_3_Minute 60 "reserviert" 61 "reserviert" 62 "Init" 63 "Fehler" ;
VAL_ 1398 MOD_Set_Timer_1_Monat 0 "Init" 14 "reserviert" 15 "Fehler" ;
VAL_ 1398 MOD_Set_Timer_2_Monat 0 "Init" 14 "reserviert" 15 "Fehler" ;
VAL_ 1398 MOD_Set_Timer_3_Monat 0 "Init" 14 "reserviert" 15 "Fehler" ;
VAL_ 1398 MOD_Set_Timer_1_Stunde 24 "reserviert" 25 "reserviert" 26 "reserviert" 27 "reserviert" 28 "reserviert" 29 "reserviert" 30 "Init" 31 "Fehler" ;
VAL_ 1398 MOD_Set_Timer_2_Stunde 24 "reserviert" 25 "reserviert" 26 "reserviert" 27 "reserviert" 28 "reserviert" 29 "reserviert" 30 "Init" 31 "Fehler" ;
VAL_ 1398 MOD_Set_Timer_3_Stunde 24 "reserviert" 25 "reserviert" 26 "reserviert" 27 "reserviert" 28 "reserviert" 29 "reserviert" 30 "Init" 31 "Fehler" ;
VAL_ 1398 MOD_Set_Timer_1_Tag 0 "Init" ;
VAL_ 1398 MOD_Set_Timer_2_Tag 0 "Init" ;
VAL_ 1398 MOD_Set_Timer_3_Tag 0 "Init" ;
VAL_ 1398 MOD_Set_Timer_1_Laden 0 "Timer_nicht_aktiv" 1 "Timer_aktiv" ;
VAL_ 1398 MOD_Set_Timer_2_Laden 0 "Timer_nicht_aktiv" 1 "Timer_aktiv" ;
VAL_ 1398 MOD_Set_Timer_3_Laden 0 "Timer_nicht_aktiv" 1 "Timer_aktiv" ;
VAL_ 1398 MOD_Set_Timer_1_Vorklima 0 "Timer_nicht_aktiv" 1 "Timer_aktiv" ;
VAL_ 1398 MOD_Set_Timer_2_Vorklima 0 "Timer_nicht_aktiv" 1 "Timer_aktiv" ;
VAL_ 1398 MOD_Set_Timer_3_Vorklima 0 "Timer_nicht_aktiv" 1 "Timer_aktiv" ;
VAL_ 1398 MOD_Set_Timer_1_Zyklus_Mo 0 "Timer_am_Wochentag_nicht_aktiv" 1 "Timer_am_Wochentag_aktiv" ;
VAL_ 1398 MOD_Set_Timer_2_Zyklus_Mo 0 "Timer_am_Wochentag_nicht_aktiv" 1 "Timer_am_Wochentag_aktiv" ;
VAL_ 1398 MOD_Set_Timer_3_Zyklus_Mo 0 "Timer_am_Wochentag_nicht_aktiv" 1 "Timer_am_Wochentag_aktiv" ;
VAL_ 1398 MOD_Set_Timer_1_Zyklus_Di 0 "Timer_am_Wochentag_nicht_aktiv" 1 "Timer_am_Wochentag_aktiv" ;
VAL_ 1398 MOD_Set_Timer_2_Zyklus_Di 0 "Timer_am_Wochentag_nicht_aktiv" 1 "Timer_am_Wochentag_aktiv" ;
VAL_ 1398 MOD_Set_Timer_3_Zyklus_Di 0 "Timer_am_Wochentag_nicht_aktiv" 1 "Timer_am_Wochentag_aktiv" ;
VAL_ 1398 MOD_Set_Timer_1_Zyklus_Mi 0 "Timer_am_Wochentag_nicht_aktiv" 1 "Timer_am_Wochentag_aktiv" ;
VAL_ 1398 MOD_Set_Timer_2_Zyklus_Mi 0 "Timer_am_Wochentag_nicht_aktiv" 1 "Timer_am_Wochentag_aktiv" ;
VAL_ 1398 MOD_Set_Timer_3_Zyklus_Mi 0 "Timer_am_Wochentag_nicht_aktiv" 1 "Timer_am_Wochentag_aktiv" ;
VAL_ 1398 MOD_Set_Timer_1_Zyklus_Do 0 "Timer_am_Wochentag_nicht_aktiv" 1 "Timer_am_Wochentag_aktiv" ;
VAL_ 1398 MOD_Set_Timer_2_Zyklus_Do 0 "Timer_am_Wochentag_nicht_aktiv" 1 "Timer_am_Wochentag_aktiv" ;
VAL_ 1398 MOD_Set_Timer_3_Zyklus_Do 0 "Timer_am_Wochentag_nicht_aktiv" 1 "Timer_am_Wochentag_aktiv" ;
VAL_ 1398 MOD_Set_Timer_1_Zyklus_Fr 0 "Timer_am_Wochentag_nicht_aktiv" 1 "Timer_am_Wochentag_aktiv" ;
VAL_ 1398 MOD_Set_Timer_2_Zyklus_Fr 0 "Timer_am_Wochentag_nicht_aktiv" 1 "Timer_am_Wochentag_aktiv" ;
VAL_ 1398 MOD_Set_Timer_3_Zyklus_Fr 0 "Timer_am_Wochentag_nicht_aktiv" 1 "Timer_am_Wochentag_aktiv" ;
VAL_ 1398 MOD_Set_Timer_1_Zyklus_Sa 0 "Timer_am_Wochentag_nicht_aktiv" 1 "Timer_am_Wochentag_aktiv" ;
VAL_ 1398 MOD_Set_Timer_2_Zyklus_Sa 0 "Timer_am_Wochentag_nicht_aktiv" 1 "Timer_am_Wochentag_aktiv" ;
VAL_ 1398 MOD_Set_Timer_3_Zyklus_Sa 0 "Timer_am_Wochentag_nicht_aktiv" 1 "Timer_am_Wochentag_aktiv" ;
VAL_ 1398 MOD_Set_Timer_1_Zyklus_So 0 "Timer_am_Wochentag_nicht_aktiv" 1 "Timer_am_Wochentag_aktiv" ;
VAL_ 1398 MOD_Set_Timer_2_Zyklus_So 0 "Timer_am_Wochentag_nicht_aktiv" 1 "Timer_am_Wochentag_aktiv" ;
VAL_ 1398 MOD_Set_Timer_3_Zyklus_So 0 "Timer_am_Wochentag_nicht_aktiv" 1 "Timer_am_Wochentag_aktiv" ;
VAL_ 1398 MOD_Set_Timer_1_Zyklus_WH 0 "zyklisch" 1 "einmalig" ;
VAL_ 1398 MOD_Set_Timer_2_Zyklus_WH 0 "zyklisch" 1 "einmalig" ;
VAL_ 1398 MOD_Set_Timer_MUX 0 "leer" 1 "Abfahrtstimer_1" 2 "Abfahrtstimer_2" 3 "Abfahrtstimer_3" 4 "Klimatimer_1" 5 "Klimatimer_2" 6 "reserviert" 7 "reserviert" ;
VAL_ 1398 MOD_Set_Timer_3_Zyklus_WH 0 "zyklisch" 1 "einmalig" ;
VAL_ 1398 MOD_Set_Nachtstrom_X_Std_Anf 62 "Init" 63 "ungueltig" ;
VAL_ 1398 MOD_Set_Nachtstrom_Prof 0 "keine_Aktion" 1 "Profil_1_setzen" 2 "Profil_2_setzen" 3 "Profil_3_setzen" ;
VAL_ 1398 MOD_Set_Nachtstrom_X_Std_End 62 "Init" 63 "ungueltig" ;
VAL_ 1398 MOD_Set_Nachtstrom_Akt_Prof 0 "kein_Profil_gesetzt" 1 "Profil_1_aktiv" 2 "Profil_2_aktiv" 3 "Profil_3_aktiv" ;
VAL_ 1398 MOD_Set_Abbruch_Klima 0 "keine_Aktion" 1 "Abbruch_Standkl_Standh" ;
VAL_ 1398 MOD_Set_Sofortstart_Klima 0 "keine_Aktion" 1 "Start_Standkl_Standh" ;
VAL_ 1398 MOD_Anf_Spiegel_anklappen 0 "keine_Aktion" 1 "Anforderung_Spiegel_anklappen" ;
VAL_ 1398 MOD_Anf_ZV 0 "keine_Aktion" 1 "Anforderung_alle_Tueren_verriegeln" 2 "Anforderung_alle_Tueren_entriegeln" 3 "reserviert" ;
VAL_ 1397 HVLM_Status_Timer_7_Laden 0 "Timer_nicht_aktiv" 1 "Timer_aktiv" ;
VAL_ 1397 HVLM_Ladetexte 0 "Keine_Anzeige" 1 "AC_Laden_nicht_moeglich" 2 "DC_Laden_nicht_moeglich" 3 "AC_und_DC_Laden_nicht_moeglich" ;
VAL_ 1397 HVLM_Status_Timer_4_Jahr 126 "Init" 127 "reserviert" ;
VAL_ 1397 HVLM_Status_Timer_4_Minute 60 "reserviert" 61 "reserviert" 62 "Init" 63 "Fehler" ;
VAL_ 1397 HVLM_Status_Timer_4_Monat 0 "Init" 14 "reserviert" 15 "Fehler" ;
VAL_ 1397 HVLM_Status_Timer_4_Stunde 24 "reserviert" 25 "reserviert" 26 "reserviert" 27 "reserviert" 28 "reserviert" 29 "reserviert" 30 "Init" 31 "Fehler" ;
VAL_ 1397 HVLM_Status_Timer_4_Tag 0 "Init" ;
VAL_ 1397 HVLM_Status_Timer_4_Laden 0 "Timer_nicht_aktiv" 1 "Timer_aktiv" ;
VAL_ 1397 HVLM_Status_Timer_4_Vorklima 0 "Timer_nicht_aktiv" 1 "Timer_aktiv" ;
VAL_ 1397 HVLM_Status_Timer_4_Zyklus_Mo 0 "Timer_am_Wochentag_nicht_aktiv" 1 "Timer_am_Wochentag_aktiv" ;
VAL_ 1397 HVLM_Status_Timer_2_Vorklima 0 "Timer_nicht_aktiv" 1 "Timer_aktiv" ;
VAL_ 1397 HVLM_Status_Timer_3_Vorklima 0 "Timer_nicht_aktiv" 1 "Timer_aktiv" ;
VAL_ 1397 HVLM_Status_Timer_1_Zyklus_Mo 0 "Timer_am_Wochentag_nicht_aktiv" 1 "Timer_am_Wochentag_aktiv" ;
VAL_ 1397 HVLM_Status_Timer_2_Zyklus_Mo 0 "Timer_am_Wochentag_nicht_aktiv" 1 "Timer_am_Wochentag_aktiv" ;
VAL_ 1397 HVLM_Status_Timer_3_Zyklus_Mo 0 "Timer_am_Wochentag_nicht_aktiv" 1 "Timer_am_Wochentag_aktiv" ;
VAL_ 1397 HVLM_Status_Timer_1_Zyklus_Di 0 "Timer_am_Wochentag_nicht_aktiv" 1 "Timer_am_Wochentag_aktiv" ;
VAL_ 1397 HVLM_Status_Timer_2_Zyklus_Di 0 "Timer_am_Wochentag_nicht_aktiv" 1 "Timer_am_Wochentag_aktiv" ;
VAL_ 1397 HVLM_Status_Timer_3_Zyklus_Di 0 "Timer_am_Wochentag_nicht_aktiv" 1 "Timer_am_Wochentag_aktiv" ;
VAL_ 1397 HVLM_Status_Timer_1_Zyklus_Mi 0 "Timer_am_Wochentag_nicht_aktiv" 1 "Timer_am_Wochentag_aktiv" ;
VAL_ 1397 HVLM_Status_Timer_2_Zyklus_Mi 0 "Timer_am_Wochentag_nicht_aktiv" 1 "Timer_am_Wochentag_aktiv" ;
VAL_ 1397 HVLM_Status_Timer_3_Zyklus_Mi 0 "Timer_am_Wochentag_nicht_aktiv" 1 "Timer_am_Wochentag_aktiv" ;
VAL_ 1397 HVLM_Status_Timer_1_Zyklus_Do 0 "Timer_am_Wochentag_nicht_aktiv" 1 "Timer_am_Wochentag_aktiv" ;
VAL_ 1397 HVLM_Status_Timer_2_Zyklus_Do 0 "Timer_am_Wochentag_nicht_aktiv" 1 "Timer_am_Wochentag_aktiv" ;
VAL_ 1397 HVLM_Status_Timer_3_Zyklus_Do 0 "Timer_am_Wochentag_nicht_aktiv" 1 "Timer_am_Wochentag_aktiv" ;
VAL_ 1397 HVLM_Status_Timer_1_Zyklus_Fr 0 "Timer_am_Wochentag_nicht_aktiv" 1 "Timer_am_Wochentag_aktiv" ;
VAL_ 1397 HVLM_Status_Timer_2_Zyklus_Fr 0 "Timer_am_Wochentag_nicht_aktiv" 1 "Timer_am_Wochentag_aktiv" ;
VAL_ 1397 HVLM_Status_Timer_3_Zyklus_Fr 0 "Timer_am_Wochentag_nicht_aktiv" 1 "Timer_am_Wochentag_aktiv" ;
VAL_ 1397 HVLM_Status_Timer_1_Zyklus_Sa 0 "Timer_am_Wochentag_nicht_aktiv" 1 "Timer_am_Wochentag_aktiv" ;
VAL_ 1397 HVLM_Status_Timer_2_Zyklus_Sa 0 "Timer_am_Wochentag_nicht_aktiv" 1 "Timer_am_Wochentag_aktiv" ;
VAL_ 1397 HVLM_Status_Timer_3_Zyklus_Sa 0 "Timer_am_Wochentag_nicht_aktiv" 1 "Timer_am_Wochentag_aktiv" ;
VAL_ 1397 HVLM_Status_Timer_1_Zyklus_So 0 "Timer_am_Wochentag_nicht_aktiv" 1 "Timer_am_Wochentag_aktiv" ;
VAL_ 1397 HVLM_Status_Timer_2_Zyklus_So 0 "Timer_am_Wochentag_nicht_aktiv" 1 "Timer_am_Wochentag_aktiv" ;
VAL_ 1397 HVLM_Status_Timer_3_Zyklus_So 0 "Timer_am_Wochentag_nicht_aktiv" 1 "Timer_am_Wochentag_aktiv" ;
VAL_ 1397 HVLM_Status_Timer_1_Zyklus_WH 0 "zyklisch" 1 "einmalig" ;
VAL_ 1397 HVLM_Status_Timer_2_Zyklus_WH 0 "zyklisch" 1 "einmalig" ;
VAL_ 1397 HVLM_Status_Timer_MUX 0 "leer" 1 "Timer_1" 2 "Timer_2" 3 "Timer_3" 4 "Timer_4" 5 "reserviert" 6 "reserviert" 7 "Timer_7" ;
VAL_ 1397 HVLM_Status_Timer_3_Zyklus_WH 0 "zyklisch" 1 "einmalig" ;
VAL_ 1397 HVLM_Status_Nachtstrom_X_Std_Anf 62 "Init" 63 "ungueltig" ;
VAL_ 1397 HVLM_Status_Nachtstrom_Prof 0 "keine_Aktion" 1 "Profil_1_setzen" 2 "Profil_2_setzen" 3 "Profil_3_setzen" ;
VAL_ 1397 HVLM_Status_Nachtstrom_X_Std_End 62 "Init" 63 "ungueltig" ;
VAL_ 1397 HVLM_Status_Nachtstrom_Akt_Prof 0 "kein_Profil_gesetzt" 1 "Profil_1_aktiv" 2 "Profil_2_aktiv" 3 "Profil_3_aktiv" ;
VAL_ 1397 HVLM_Status_Laden 0 "Ladefehler" 1 "Laden_aktv" 2 "Laden_unterbrochen" 3 "Laden_beendet" 4 "Ladung_extern_unterbrochen" 5 "Ladung_standby" 6 "Init" 7 "Fehler" ;
VAL_ 1397 HVLM_Status_Timer_4_Zyklus_Di 0 "Timer_am_Wochentag_nicht_aktiv" 1 "Timer_am_Wochentag_aktiv" ;
VAL_ 1397 HVLM_Status_Timer_4_Zyklus_Mi 0 "Timer_am_Wochentag_nicht_aktiv" 1 "Timer_am_Wochentag_aktiv" ;
VAL_ 1397 HVLM_Status_Timer_4_Zyklus_Do 0 "Timer_am_Wochentag_nicht_aktiv" 1 "Timer_am_Wochentag_aktiv" ;
VAL_ 1397 HVLM_Status_Timer_4_Zyklus_Fr 0 "Timer_am_Wochentag_nicht_aktiv" 1 "Timer_am_Wochentag_aktiv" ;
VAL_ 1397 HVLM_Status_Timer_1_Jahr 126 "Init" 127 "reserviert" ;
VAL_ 1397 HVLM_Status_Timer_2_Jahr 126 "Init" 127 "reserviert" ;
VAL_ 1397 HVLM_Status_Timer_3_Jahr 126 "Init" 127 "reserviert" ;
VAL_ 1397 HVLM_Status_Timer_7_Jahr 126 "Init" 127 "reserviert" ;
VAL_ 1397 HVLM_Status_Timer_1_Minute 60 "reserviert" 61 "reserviert" 62 "Init" 63 "Fehler" ;
VAL_ 1397 HVLM_Status_Timer_2_Minute 60 "reserviert" 61 "reserviert" 62 "Init" 63 "Fehler" ;
VAL_ 1397 HVLM_Status_Timer_3_Minute 60 "reserviert" 61 "reserviert" 62 "Init" 63 "Fehler" ;
VAL_ 1397 HVLM_Status_Timer_7_Minute 60 "reserviert" 61 "reserviert" 62 "Init" 63 "Fehler" ;
VAL_ 1397 HVLM_Status_Timer_1_Monat 0 "Init" 14 "reserviert" 15 "Fehler" ;
VAL_ 1397 HVLM_Status_Timer_2_Monat 0 "Init" 14 "reserviert" 15 "Fehler" ;
VAL_ 1397 HVLM_Status_Timer_3_Monat 0 "Init" 14 "reserviert" 15 "Fehler" ;
VAL_ 1397 HVLM_Status_Timer_7_Monat 0 "Init" 14 "reserviert" 15 "Fehler" ;
VAL_ 1397 HVLM_Status_Timer_1_Stunde 24 "reserviert" 25 "reserviert" 26 "reserviert" 27 "reserviert" 28 "reserviert" 29 "reserviert" 30 "Init" 31 "Fehler" ;
VAL_ 1397 HVLM_Status_Timer_2_Stunde 24 "reserviert" 25 "reserviert" 26 "reserviert" 27 "reserviert" 28 "reserviert" 29 "reserviert" 30 "Init" 31 "Fehler" ;
VAL_ 1397 HVLM_Status_Timer_3_Stunde 24 "reserviert" 25 "reserviert" 26 "reserviert" 27 "reserviert" 28 "reserviert" 29 "reserviert" 30 "Init" 31 "Fehler" ;
VAL_ 1397 HVLM_Status_Timer_7_Stunde 24 "reserviert" 25 "reserviert" 26 "reserviert" 27 "reserviert" 28 "reserviert" 29 "reserviert" 30 "Init" 31 "Fehler" ;
VAL_ 1397 HVLM_Status_Timer_1_Tag 0 "Init" ;
VAL_ 1397 HVLM_Status_Timer_2_Tag 0 "Init" ;
VAL_ 1397 HVLM_Status_Timer_3_Tag 0 "Init" ;
VAL_ 1397 HVLM_Status_Timer_7_Tag 0 "Init" ;
VAL_ 1397 HVLM_Status_Timer_1_Laden 0 "Timer_nicht_aktiv" 1 "Timer_aktiv" ;
VAL_ 1397 HVLM_Status_Timer_2_Laden 0 "Timer_nicht_aktiv" 1 "Timer_aktiv" ;
VAL_ 1397 HVLM_Status_Timer_3_Laden 0 "Timer_nicht_aktiv" 1 "Timer_aktiv" ;
VAL_ 1397 HVLM_Status_Timer_1_Vorklima 0 "Timer_nicht_aktiv" 1 "Timer_aktiv" ;
VAL_ 1397 HVLM_Status_Timer_4_Zyklus_Sa 0 "Timer_am_Wochentag_nicht_aktiv" 1 "Timer_am_Wochentag_aktiv" ;
VAL_ 1397 HVLM_Status_Timer_4_Zyklus_So 0 "Timer_am_Wochentag_nicht_aktiv" 1 "Timer_am_Wochentag_aktiv" ;
VAL_ 1397 HVLM_Status_Timer_4_Zyklus_WH 0 "zyklisch" 1 "einmalig" ;
VAL_ 1446 OBC_KomponentenFehler_01 0 "TestComplete_PASS" 1 "TestComplete_FAIL" 2 "TestNotComplete_PASS" ;
VAL_ 1446 OBC_KomponentenFehler_02 0 "TestComplete_PASS" 1 "TestComplete_FAIL" 2 "TestNotComplete_PASS" ;
VAL_ 1446 OBC_KomponentenFehler_03 0 "TestComplete_PASS" 1 "TestComplete_FAIL" 2 "TestNotComplete_PASS" ;
VAL_ 1446 OBC_KomponentenFehler_04 0 "TestComplete_PASS" 1 "TestComplete_FAIL" 2 "TestNotComplete_PASS" ;
VAL_ 1446 OBC_KomponentenFehler_05 0 "TestComplete_PASS" 1 "TestComplete_FAIL" 2 "TestNotComplete_PASS" ;
VAL_ 1446 OBC_KomponentenFehler_06 0 "TestComplete_PASS" 1 "TestComplete_FAIL" 2 "TestNotComplete_PASS" ;
VAL_ 1446 OBC_KomponentenFehler_07 0 "TestComplete_PASS" 1 "TestComplete_FAIL" 2 "TestNotComplete_PASS" ;
VAL_ 1446 OBC_KomponentenFehler_08 0 "TestComplete_PASS" 1 "TestComplete_FAIL" 2 "TestNotComplete_PASS" ;
VAL_ 1446 OBC_KomponentenFehler_09 0 "TestComplete_PASS" 1 "TestComplete_FAIL" 2 "TestNotComplete_PASS" ;
VAL_ 1446 OBC_KomponentenFehler_10 0 "TestComplete_PASS" 1 "TestComplete_FAIL" 2 "TestNotComplete_PASS" ;
VAL_ 1446 OBC_KomponentenFehler_11 0 "TestComplete_PASS" 1 "TestComplete_FAIL" 2 "TestNotComplete_PASS" ;
VAL_ 1446 OBC_KomponentenFehler_12 0 "TestComplete_PASS" 1 "TestComplete_FAIL" 2 "TestNotComplete_PASS" ;
VAL_ 1446 OBC_KomponentenFehler_13 0 "TestComplete_PASS" 1 "TestComplete_FAIL" 2 "TestNotComplete_PASS" ;
VAL_ 1446 OBC_KomponentenFehler_14 0 "TestComplete_PASS" 1 "TestComplete_FAIL" 2 "TestNotComplete_PASS" ;
VAL_ 1446 OBC_KomponentenFehler_15 0 "TestComplete_PASS" 1 "TestComplete_FAIL" 2 "TestNotComplete_PASS" ;
VAL_ 1446 OBC_KomponentenFehler_16 0 "TestComplete_PASS" 1 "TestComplete_FAIL" 2 "TestNotComplete_PASS" ;
VAL_ 1446 OBC_KomponentenFehler_17 0 "TestComplete_PASS" 1 "TestComplete_FAIL" 2 "TestNotComplete_PASS" ;
VAL_ 1446 OBC_KomponentenFehler_18 0 "TestComplete_PASS" 1 "TestComplete_FAIL" 2 "TestNotComplete_PASS" ;
VAL_ 1446 OBC_KomponentenFehler_19 0 "TestComplete_PASS" 1 "TestComplete_FAIL" 2 "TestNotComplete_PASS" ;
VAL_ 1446 OBC_KomponentenFehler_20 0 "TestComplete_PASS" 1 "TestComplete_FAIL" 2 "TestNotComplete_PASS" ;
VAL_ 1446 OBC_KomponentenFehler_21 0 "TestComplete_PASS" 1 "TestComplete_FAIL" 2 "TestNotComplete_PASS" ;
VAL_ 1446 OBC_KomponentenFehler_22 0 "TestComplete_PASS" 1 "TestComplete_FAIL" 2 "TestNotComplete_PASS" ;
VAL_ 1446 OBC_KomponentenFehler_23 0 "TestComplete_PASS" 1 "TestComplete_FAIL" 2 "TestNotComplete_PASS" ;
VAL_ 1446 OBC_KomponentenFehler_24 0 "TestComplete_PASS" 1 "TestComplete_FAIL" 2 "TestNotComplete_PASS" ;
VAL_ 1446 OBC_KomponentenFehler_25 0 "TestComplete_PASS" 1 "TestComplete_FAIL" 2 "TestNotComplete_PASS" ;
VAL_ 1446 OBC_KomponentenFehler_26 0 "TestComplete_PASS" 1 "TestComplete_FAIL" 2 "TestNotComplete_PASS" ;
VAL_ 1446 OBC_KomponentenFehler_27 0 "TestComplete_PASS" 1 "TestComplete_FAIL" 2 "TestNotComplete_PASS" ;
VAL_ 1446 OBC_KomponentenFehler_28 0 "TestComplete_PASS" 1 "TestComplete_FAIL" 2 "TestNotComplete_PASS" ;
VAL_ 1446 OBC_KomponentenFehler_29 0 "TestComplete_PASS" 1 "TestComplete_FAIL" 2 "TestNotComplete_PASS" ;
VAL_ 1446 OBC_KomponentenFehler_30 0 "TestComplete_PASS" 1 "TestComplete_FAIL" 2 "TestNotComplete_PASS" ;
VAL_ 1446 OBC_KomponentenFehler_31 0 "TestComplete_PASS" 1 "TestComplete_FAIL" 2 "TestNotComplete_PASS" ;
VAL_ 1446 OBC_KomponentenFehler_32 0 "TestComplete_PASS" 1 "TestComplete_FAIL" 2 "TestNotComplete_PASS" ;
